VERSION ""

NS_ :

BS_:

BU_:  Inverter  Battery  Charger  Host

BO_ 2571108363 BATT_eventMatrix_A_11: 8 Battery
 SG_ BATT_packModIdFault_11 : 8|1@1+ (1,0) [0|1] "" Host
 SG_ BATT_packModExitedFromBus_11 : 16|1@1+ (1,0) [0|1] "" Host
 SG_ BATT_packFetChgWelded_11 : 35|1@1+ (1,0) [0|1] "" Host
 SG_ BATT_packFetDsgWelded_11 : 36|1@1+ (1,0) [0|1] "" Host
 SG_ BATT_fetDsgShortedAux_11 : 63|1@1+ (1,0) [0|1] "" Host
 SG_ BATT_fetChgShortedAux_11 : 25|1@1+ (1,0) [0|1] "" Host
 SG_ BATT_prechargeFetFail_11 : 39|1@1+ (1,0) [0|1] "" Host
 SG_ BATT_abnormalResetReason_11 : 31|1@1+ (1,0) [0|1] "" Host
 SG_ BATT_prechargeTooSlow_11 : 49|1@1+ (1,0) [0|1] "" Host
 SG_ BATT_prechargeTooFast_11 : 50|1@1+ (1,0) [0|1] "" Host
 SG_ BATT_prechargeTimeout_11 : 51|1@1+ (1,0) [0|1] "" Host
 SG_ BATT_fetChgShorted_11 : 23|1@1+ (1,0) [0|1] "" Host
 SG_ BATT_fetChgFailToClose_11 : 22|1@1+ (1,0) [0|1] "" Host
 SG_ BATT_packModSelectFault_11 : 21|1@1+ (1,0) [0|1] "" Host
 SG_ BATT_packModConnectFault_11 : 20|1@1+ (1,0) [0|1] "" Host
 SG_ BATT_packModMIA_11 : 19|1@1+ (1,0) [0|1] "" Host
 SG_ BATT_packModImbalance_11 : 18|1@1+ (1,0) [0|1] "" Host
 SG_ BATT_afeFault_11 : 17|1@1+ (1,0) [0|1] "" Host
 SG_ BATT_chargerMIA_11 : 60|1@1+ (1,0) [0|1] "" Host
 SG_ BATT_chargerError_11 : 59|1@1+ (1,0) [0|1] "" Host
 SG_ BATT_vBrickUnderWar_11 : 58|1@1+ (1,0) [0|1] "" Host
 SG_ BATT_vBrickUnderSev_11 : 57|1@1+ (1,0) [0|1] "" Host
 SG_ BATT_vBrickUnderMod_11 : 56|1@1+ (1,0) [0|1] "" Host
 SG_ BATT_vBrickOverWar_11 : 55|1@1+ (1,0) [0|1] "" Host
 SG_ BATT_vBrickOverSev_11 : 54|1@1+ (1,0) [0|1] "" Host
 SG_ BATT_vBrickOverMod_11 : 53|1@1+ (1,0) [0|1] "" Host
 SG_ BATT_vBrickImbalance_11 : 52|1@1+ (1,0) [0|1] "" Host
 SG_ BATT_loggerAlmostFull_11 : 61|1@1+ (1,0) [0|1] "" Host
 SG_ BATT_tempModuleUnderWar_11 : 48|1@1+ (1,0) [0|1] "" Host
 SG_ BATT_tempModuleUnderSev_11 : 47|1@1+ (1,0) [0|1] "" Host
 SG_ BATT_tempModuleUnderMod_11 : 46|1@1+ (1,0) [0|1] "" Host
 SG_ BATT_tempModuleOverWar_11 : 45|1@1+ (1,0) [0|1] "" Host
 SG_ BATT_tempModuleOverSev_11 : 44|1@1+ (1,0) [0|1] "" Host
 SG_ BATT_tempModuleOverMod_11 : 43|1@1+ (1,0) [0|1] "" Host
 SG_ BATT_tempBrickImbalance_11 : 42|1@1+ (1,0) [0|1] "" Host
 SG_ BATT_taskLockupError_11 : 41|1@1+ (1,0) [0|1] "" Host
 SG_ BATT_tempAmbientOverWar_11 : 40|1@1+ (1,0) [0|1] "" Host
 SG_ BATT_tempAmbientOverSev_11 : 38|1@1+ (1,0) [0|1] "" Host
 SG_ BATT_tempAmbientOverMod_11 : 37|1@1+ (1,0) [0|1] "" Host
 SG_ BATT_sensePackVoltError_11 : 34|1@1+ (1,0) [0|1] "" Host
 SG_ BATT_senseLoadVoltError_11 : 33|1@1+ (1,0) [0|1] "" Host
 SG_ BATT_loggerFull_11 : 62|1@1+ (1,0) [0|1] "" Host
 SG_ BATT_senseCurrentError_11 : 32|1@1+ (1,0) [0|1] "" Host
 SG_ BATT_senseBrickTempError_11 : 30|1@1+ (1,0) [0|1] "" Host
 SG_ BATT_resPackHigh_11 : 29|1@1+ (1,0) [0|1] "" Host
 SG_ BATT_ramOverUtilError_11 : 28|1@1+ (1,0) [0|1] "" Host
 SG_ BATT_powerPackInsufficient_11 : 27|1@1+ (1,0) [0|1] "" Host
 SG_ BATT_packCellSoftShort_11 : 26|1@1+ (1,0) [0|1] "" Host
 SG_ BATT_iOverHardware_11 : 24|1@1+ (1,0) [0|1] "" Host
 SG_ BATT_fetOverTemp_11 : 15|1@1+ (1,0) [0|1] "" Host
 SG_ BATT_iOverDischarge_11 : 14|1@1+ (1,0) [0|1] "" Host
 SG_ BATT_iOverCharge_11 : 13|1@1+ (1,0) [0|1] "" Host
 SG_ BATT_inverterDriveMIA_11 : 12|1@1+ (1,0) [0|1] "" Host
 SG_ BATT_iUnderCharge_11 : 11|1@1+ (1,0) [0|1] "" Host
 SG_ BATT_hostMIA_11 : 10|1@1+ (1,0) [0|1] "" Host
 SG_ BATT_fetDsgShorted_11 : 7|1@1+ (1,0) [0|1] "" Host
 SG_ BATT_fetDsgFailToClose_11 : 6|1@1+ (1,0) [0|1] "" Host
 SG_ BATT_capLow_11 : 5|1@1+ (1,0) [0|1] "" Host
 SG_ BATT_brickOverDischarge_11 : 4|1@1+ (1,0) [0|1] "" Host
 SG_ BATT_brickOverCharge_11 : 3|1@1+ (1,0) [0|1] "" Host
 SG_ BATT_bmsProcessorError_11 : 2|1@1+ (1,0) [0|1] "" Host
 SG_ BATT_bmsMemoryError_11 : 1|1@1+ (1,0) [0|1] "" Host
 SG_ BATT_afeError_11 : 0|1@1+ (1,0) [0|1] "" Host

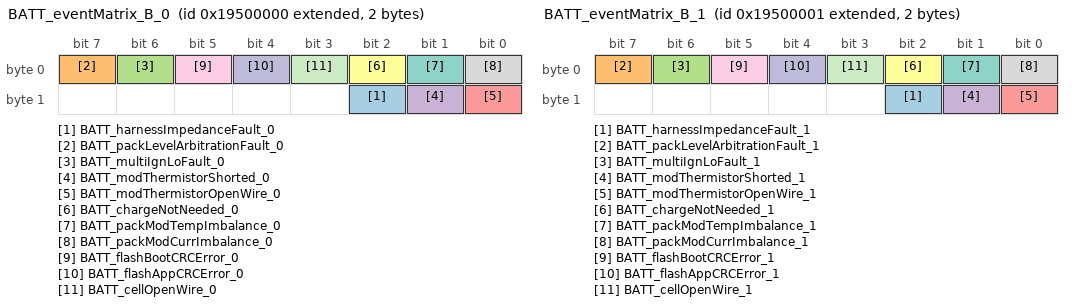
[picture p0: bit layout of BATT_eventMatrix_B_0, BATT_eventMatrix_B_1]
BO_ 2572156928 BATT_eventMatrix_B_0: 2 Battery
 SG_ BATT_harnessImpedanceFault_0 : 10|1@1+ (1,0) [0|1] "mOhms" Host
 SG_ BATT_packLevelArbitrationFault_0 : 7|1@1+ (1,0) [0|1] "" Host
 SG_ BATT_multiIgnLoFault_0 : 6|1@1+ (1,0) [0|1] "" Host
 SG_ BATT_modThermistorShorted_0 : 9|1@1+ (1,0) [0|1] "" Host
 SG_ BATT_modThermistorOpenWire_0 : 8|1@1+ (1,0) [0|1] "" Host
 SG_ BATT_chargeNotNeeded_0 : 2|1@1+ (1,0) [0|1] "" Host
 SG_ BATT_packModTempImbalance_0 : 1|1@1+ (1,0) [0|1] "" Host
 SG_ BATT_packModCurrImbalance_0 : 0|1@1+ (1,0) [0|1] "" Host
 SG_ BATT_flashBootCRCError_0 : 5|1@1+ (1,0) [0|1] "" Host
 SG_ BATT_flashAppCRCError_0 : 4|1@1+ (1,0) [0|1] "" Host
 SG_ BATT_cellOpenWire_0 : 3|1@1+ (1,0) [0|1] "" Host

BO_ 2572156929 BATT_eventMatrix_B_1: 2 Battery
 SG_ BATT_harnessImpedanceFault_1 : 10|1@1+ (1,0) [0|1] "mOhms" Host
 SG_ BATT_packLevelArbitrationFault_1 : 7|1@1+ (1,0) [0|1] "" Host
 SG_ BATT_multiIgnLoFault_1 : 6|1@1+ (1,0) [0|1] "" Host
 SG_ BATT_modThermistorShorted_1 : 9|1@1+ (1,0) [0|1] "" Host
 SG_ BATT_modThermistorOpenWire_1 : 8|1@1+ (1,0) [0|1] "" Host
 SG_ BATT_chargeNotNeeded_1 : 2|1@1+ (1,0) [0|1] "" Host
 SG_ BATT_packModTempImbalance_1 : 1|1@1+ (1,0) [0|1] "" Host
 SG_ BATT_packModCurrImbalance_1 : 0|1@1+ (1,0) [0|1] "" Host
 SG_ BATT_flashBootCRCError_1 : 5|1@1+ (1,0) [0|1] "" Host
 SG_ BATT_flashAppCRCError_1 : 4|1@1+ (1,0) [0|1] "" Host
 SG_ BATT_cellOpenWire_1 : 3|1@1+ (1,0) [0|1] "" Host

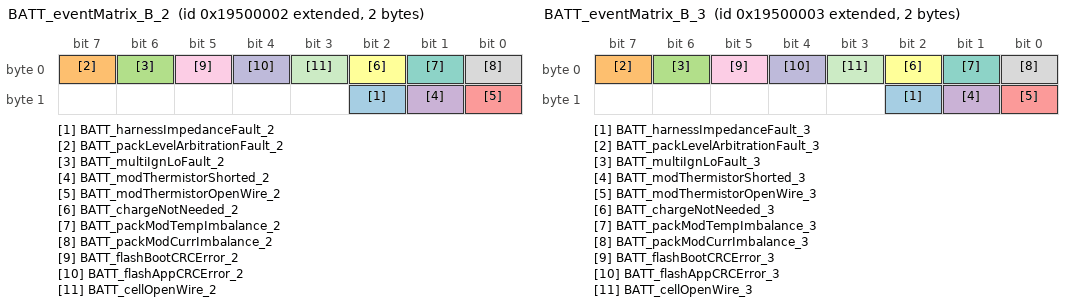
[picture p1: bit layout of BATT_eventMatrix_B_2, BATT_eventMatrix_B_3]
BO_ 2572156930 BATT_eventMatrix_B_2: 2 Battery
 SG_ BATT_harnessImpedanceFault_2 : 10|1@1+ (1,0) [0|1] "mOhms" Host
 SG_ BATT_packLevelArbitrationFault_2 : 7|1@1+ (1,0) [0|1] "" Host
 SG_ BATT_multiIgnLoFault_2 : 6|1@1+ (1,0) [0|1] "" Host
 SG_ BATT_modThermistorShorted_2 : 9|1@1+ (1,0) [0|1] "" Host
 SG_ BATT_modThermistorOpenWire_2 : 8|1@1+ (1,0) [0|1] "" Host
 SG_ BATT_chargeNotNeeded_2 : 2|1@1+ (1,0) [0|1] "" Host
 SG_ BATT_packModTempImbalance_2 : 1|1@1+ (1,0) [0|1] "" Host
 SG_ BATT_packModCurrImbalance_2 : 0|1@1+ (1,0) [0|1] "" Host
 SG_ BATT_flashBootCRCError_2 : 5|1@1+ (1,0) [0|1] "" Host
 SG_ BATT_flashAppCRCError_2 : 4|1@1+ (1,0) [0|1] "" Host
 SG_ BATT_cellOpenWire_2 : 3|1@1+ (1,0) [0|1] "" Host

BO_ 2572156931 BATT_eventMatrix_B_3: 2 Battery
 SG_ BATT_harnessImpedanceFault_3 : 10|1@1+ (1,0) [0|1] "mOhms" Host
 SG_ BATT_packLevelArbitrationFault_3 : 7|1@1+ (1,0) [0|1] "" Host
 SG_ BATT_multiIgnLoFault_3 : 6|1@1+ (1,0) [0|1] "" Host
 SG_ BATT_modThermistorShorted_3 : 9|1@1+ (1,0) [0|1] "" Host
 SG_ BATT_modThermistorOpenWire_3 : 8|1@1+ (1,0) [0|1] "" Host
 SG_ BATT_chargeNotNeeded_3 : 2|1@1+ (1,0) [0|1] "" Host
 SG_ BATT_packModTempImbalance_3 : 1|1@1+ (1,0) [0|1] "" Host
 SG_ BATT_packModCurrImbalance_3 : 0|1@1+ (1,0) [0|1] "" Host
 SG_ BATT_flashBootCRCError_3 : 5|1@1+ (1,0) [0|1] "" Host
 SG_ BATT_flashAppCRCError_3 : 4|1@1+ (1,0) [0|1] "" Host
 SG_ BATT_cellOpenWire_3 : 3|1@1+ (1,0) [0|1] "" Host

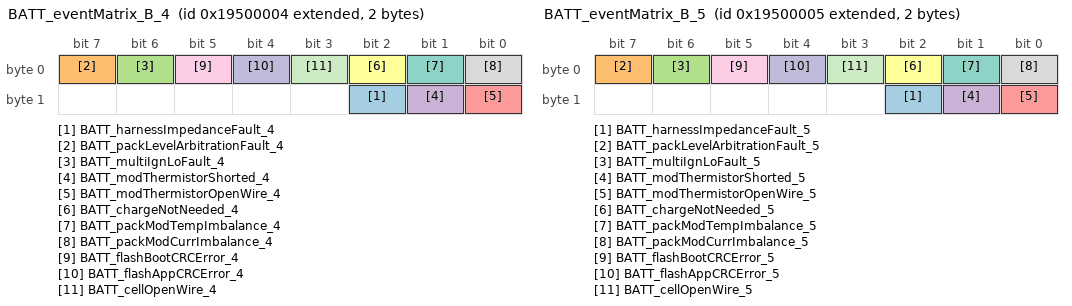
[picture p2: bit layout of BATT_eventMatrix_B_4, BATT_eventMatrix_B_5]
BO_ 2572156932 BATT_eventMatrix_B_4: 2 Battery
 SG_ BATT_harnessImpedanceFault_4 : 10|1@1+ (1,0) [0|1] "mOhms" Host
 SG_ BATT_packLevelArbitrationFault_4 : 7|1@1+ (1,0) [0|1] "" Host
 SG_ BATT_multiIgnLoFault_4 : 6|1@1+ (1,0) [0|1] "" Host
 SG_ BATT_modThermistorShorted_4 : 9|1@1+ (1,0) [0|1] "" Host
 SG_ BATT_modThermistorOpenWire_4 : 8|1@1+ (1,0) [0|1] "" Host
 SG_ BATT_chargeNotNeeded_4 : 2|1@1+ (1,0) [0|1] "" Host
 SG_ BATT_packModTempImbalance_4 : 1|1@1+ (1,0) [0|1] "" Host
 SG_ BATT_packModCurrImbalance_4 : 0|1@1+ (1,0) [0|1] "" Host
 SG_ BATT_flashBootCRCError_4 : 5|1@1+ (1,0) [0|1] "" Host
 SG_ BATT_flashAppCRCError_4 : 4|1@1+ (1,0) [0|1] "" Host
 SG_ BATT_cellOpenWire_4 : 3|1@1+ (1,0) [0|1] "" Host

BO_ 2572156933 BATT_eventMatrix_B_5: 2 Battery
 SG_ BATT_harnessImpedanceFault_5 : 10|1@1+ (1,0) [0|1] "mOhms" Host
 SG_ BATT_packLevelArbitrationFault_5 : 7|1@1+ (1,0) [0|1] "" Host
 SG_ BATT_multiIgnLoFault_5 : 6|1@1+ (1,0) [0|1] "" Host
 SG_ BATT_modThermistorShorted_5 : 9|1@1+ (1,0) [0|1] "" Host
 SG_ BATT_modThermistorOpenWire_5 : 8|1@1+ (1,0) [0|1] "" Host
 SG_ BATT_chargeNotNeeded_5 : 2|1@1+ (1,0) [0|1] "" Host
 SG_ BATT_packModTempImbalance_5 : 1|1@1+ (1,0) [0|1] "" Host
 SG_ BATT_packModCurrImbalance_5 : 0|1@1+ (1,0) [0|1] "" Host
 SG_ BATT_flashBootCRCError_5 : 5|1@1+ (1,0) [0|1] "" Host
 SG_ BATT_flashAppCRCError_5 : 4|1@1+ (1,0) [0|1] "" Host
 SG_ BATT_cellOpenWire_5 : 3|1@1+ (1,0) [0|1] "" Host

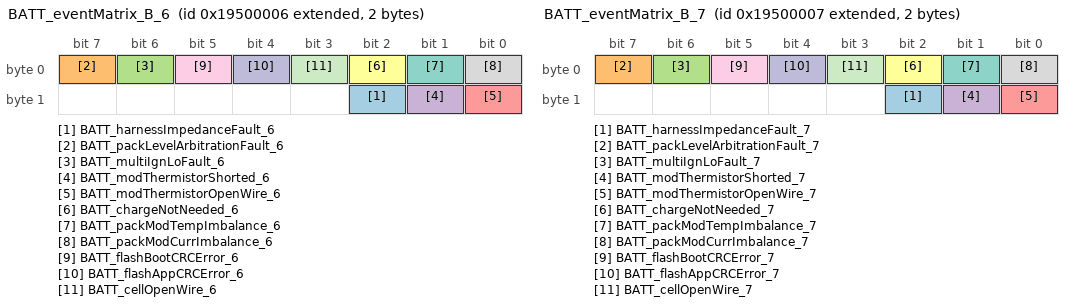
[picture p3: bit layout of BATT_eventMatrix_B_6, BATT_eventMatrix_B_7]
BO_ 2572156934 BATT_eventMatrix_B_6: 2 Battery
 SG_ BATT_harnessImpedanceFault_6 : 10|1@1+ (1,0) [0|1] "mOhms" Host
 SG_ BATT_packLevelArbitrationFault_6 : 7|1@1+ (1,0) [0|1] "" Host
 SG_ BATT_multiIgnLoFault_6 : 6|1@1+ (1,0) [0|1] "" Host
 SG_ BATT_modThermistorShorted_6 : 9|1@1+ (1,0) [0|1] "" Host
 SG_ BATT_modThermistorOpenWire_6 : 8|1@1+ (1,0) [0|1] "" Host
 SG_ BATT_chargeNotNeeded_6 : 2|1@1+ (1,0) [0|1] "" Host
 SG_ BATT_packModTempImbalance_6 : 1|1@1+ (1,0) [0|1] "" Host
 SG_ BATT_packModCurrImbalance_6 : 0|1@1+ (1,0) [0|1] "" Host
 SG_ BATT_flashBootCRCError_6 : 5|1@1+ (1,0) [0|1] "" Host
 SG_ BATT_flashAppCRCError_6 : 4|1@1+ (1,0) [0|1] "" Host
 SG_ BATT_cellOpenWire_6 : 3|1@1+ (1,0) [0|1] "" Host

BO_ 2572156935 BATT_eventMatrix_B_7: 2 Battery
 SG_ BATT_harnessImpedanceFault_7 : 10|1@1+ (1,0) [0|1] "mOhms" Host
 SG_ BATT_packLevelArbitrationFault_7 : 7|1@1+ (1,0) [0|1] "" Host
 SG_ BATT_multiIgnLoFault_7 : 6|1@1+ (1,0) [0|1] "" Host
 SG_ BATT_modThermistorShorted_7 : 9|1@1+ (1,0) [0|1] "" Host
 SG_ BATT_modThermistorOpenWire_7 : 8|1@1+ (1,0) [0|1] "" Host
 SG_ BATT_chargeNotNeeded_7 : 2|1@1+ (1,0) [0|1] "" Host
 SG_ BATT_packModTempImbalance_7 : 1|1@1+ (1,0) [0|1] "" Host
 SG_ BATT_packModCurrImbalance_7 : 0|1@1+ (1,0) [0|1] "" Host
 SG_ BATT_flashBootCRCError_7 : 5|1@1+ (1,0) [0|1] "" Host
 SG_ BATT_flashAppCRCError_7 : 4|1@1+ (1,0) [0|1] "" Host
 SG_ BATT_cellOpenWire_7 : 3|1@1+ (1,0) [0|1] "" Host

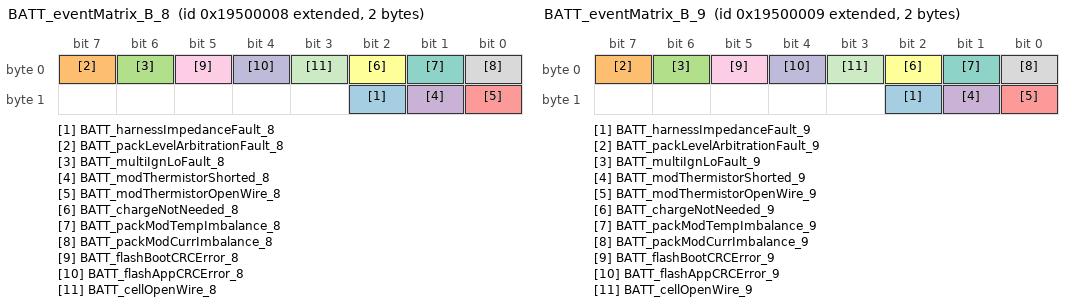
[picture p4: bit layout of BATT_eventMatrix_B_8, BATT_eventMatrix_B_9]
BO_ 2572156936 BATT_eventMatrix_B_8: 2 Battery
 SG_ BATT_harnessImpedanceFault_8 : 10|1@1+ (1,0) [0|1] "mOhms" Host
 SG_ BATT_packLevelArbitrationFault_8 : 7|1@1+ (1,0) [0|1] "" Host
 SG_ BATT_multiIgnLoFault_8 : 6|1@1+ (1,0) [0|1] "" Host
 SG_ BATT_modThermistorShorted_8 : 9|1@1+ (1,0) [0|1] "" Host
 SG_ BATT_modThermistorOpenWire_8 : 8|1@1+ (1,0) [0|1] "" Host
 SG_ BATT_chargeNotNeeded_8 : 2|1@1+ (1,0) [0|1] "" Host
 SG_ BATT_packModTempImbalance_8 : 1|1@1+ (1,0) [0|1] "" Host
 SG_ BATT_packModCurrImbalance_8 : 0|1@1+ (1,0) [0|1] "" Host
 SG_ BATT_flashBootCRCError_8 : 5|1@1+ (1,0) [0|1] "" Host
 SG_ BATT_flashAppCRCError_8 : 4|1@1+ (1,0) [0|1] "" Host
 SG_ BATT_cellOpenWire_8 : 3|1@1+ (1,0) [0|1] "" Host

BO_ 2572156937 BATT_eventMatrix_B_9: 2 Battery
 SG_ BATT_harnessImpedanceFault_9 : 10|1@1+ (1,0) [0|1] "mOhms" Host
 SG_ BATT_packLevelArbitrationFault_9 : 7|1@1+ (1,0) [0|1] "" Host
 SG_ BATT_multiIgnLoFault_9 : 6|1@1+ (1,0) [0|1] "" Host
 SG_ BATT_modThermistorShorted_9 : 9|1@1+ (1,0) [0|1] "" Host
 SG_ BATT_modThermistorOpenWire_9 : 8|1@1+ (1,0) [0|1] "" Host
 SG_ BATT_chargeNotNeeded_9 : 2|1@1+ (1,0) [0|1] "" Host
 SG_ BATT_packModTempImbalance_9 : 1|1@1+ (1,0) [0|1] "" Host
 SG_ BATT_packModCurrImbalance_9 : 0|1@1+ (1,0) [0|1] "" Host
 SG_ BATT_flashBootCRCError_9 : 5|1@1+ (1,0) [0|1] "" Host
 SG_ BATT_flashAppCRCError_9 : 4|1@1+ (1,0) [0|1] "" Host
 SG_ BATT_cellOpenWire_9 : 3|1@1+ (1,0) [0|1] "" Host

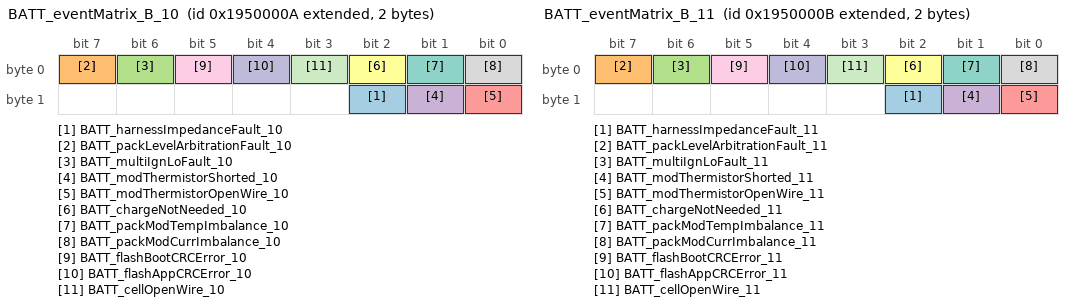
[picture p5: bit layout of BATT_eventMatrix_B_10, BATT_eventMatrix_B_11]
BO_ 2572156938 BATT_eventMatrix_B_10: 2 Battery
 SG_ BATT_harnessImpedanceFault_10 : 10|1@1+ (1,0) [0|1] "mOhms" Host
 SG_ BATT_packLevelArbitrationFault_10 : 7|1@1+ (1,0) [0|1] "" Host
 SG_ BATT_multiIgnLoFault_10 : 6|1@1+ (1,0) [0|1] "" Host
 SG_ BATT_modThermistorShorted_10 : 9|1@1+ (1,0) [0|1] "" Host
 SG_ BATT_modThermistorOpenWire_10 : 8|1@1+ (1,0) [0|1] "" Host
 SG_ BATT_chargeNotNeeded_10 : 2|1@1+ (1,0) [0|1] "" Host
 SG_ BATT_packModTempImbalance_10 : 1|1@1+ (1,0) [0|1] "" Host
 SG_ BATT_packModCurrImbalance_10 : 0|1@1+ (1,0) [0|1] "" Host
 SG_ BATT_flashBootCRCError_10 : 5|1@1+ (1,0) [0|1] "" Host
 SG_ BATT_flashAppCRCError_10 : 4|1@1+ (1,0) [0|1] "" Host
 SG_ BATT_cellOpenWire_10 : 3|1@1+ (1,0) [0|1] "" Host

BO_ 2572156939 BATT_eventMatrix_B_11: 2 Battery
 SG_ BATT_harnessImpedanceFault_11 : 10|1@1+ (1,0) [0|1] "mOhms" Host
 SG_ BATT_packLevelArbitrationFault_11 : 7|1@1+ (1,0) [0|1] "" Host
 SG_ BATT_multiIgnLoFault_11 : 6|1@1+ (1,0) [0|1] "" Host
 SG_ BATT_modThermistorShorted_11 : 9|1@1+ (1,0) [0|1] "" Host
 SG_ BATT_modThermistorOpenWire_11 : 8|1@1+ (1,0) [0|1] "" Host
 SG_ BATT_chargeNotNeeded_11 : 2|1@1+ (1,0) [0|1] "" Host
 SG_ BATT_packModTempImbalance_11 : 1|1@1+ (1,0) [0|1] "" Host
 SG_ BATT_packModCurrImbalance_11 : 0|1@1+ (1,0) [0|1] "" Host
 SG_ BATT_flashBootCRCError_11 : 5|1@1+ (1,0) [0|1] "" Host
 SG_ BATT_flashAppCRCError_11 : 4|1@1+ (1,0) [0|1] "" Host
 SG_ BATT_cellOpenWire_11 : 3|1@1+ (1,0) [0|1] "" Host

BO_ 2617245696 BATT_diagnosticRunTime_0: 6 Battery
 SG_ BATT_totalRunTime_0 : 0|16@1+ (10,0) [0|655350] "10min" Host

BO_ 2617245697 BATT_diagnosticRunTime_1: 6 Battery
 SG_ BATT_totalRunTime_1 : 0|16@1+ (10,0) [0|655350] "10min" Host

BO_ 2617245698 BATT_diagnosticRunTime_2: 6 Battery
 SG_ BATT_totalRunTime_2 : 0|16@1+ (10,0) [0|655350] "10min" Host

BO_ 2617245699 BATT_diagnosticRunTime_3: 6 Battery
 SG_ BATT_totalRunTime_3 : 0|16@1+ (10,0) [0|655350] "10min" Host

BO_ 2617245700 BATT_diagnosticRunTime_4: 6 Battery
 SG_ BATT_totalRunTime_4 : 0|16@1+ (10,0) [0|655350] "10min" Host

BO_ 2617245701 BATT_diagnosticRunTime_5: 6 Battery
 SG_ BATT_totalRunTime_5 : 0|16@1+ (10,0) [0|655350] "10min" Host

BO_ 2617245702 BATT_diagnosticRunTime_6: 6 Battery
 SG_ BATT_totalRunTime_6 : 0|16@1+ (10,0) [0|655350] "10min" Host

BO_ 2617245703 BATT_diagnosticRunTime_7: 6 Battery
 SG_ BATT_totalRunTime_7 : 0|16@1+ (10,0) [0|655350] "10min" Host

BO_ 2617245704 BATT_diagnosticRunTime_8: 6 Battery
 SG_ BATT_totalRunTime_8 : 0|16@1+ (10,0) [0|655350] "10min" Host

BO_ 2617245705 BATT_diagnosticRunTime_9: 6 Battery
 SG_ BATT_totalRunTime_9 : 0|16@1+ (10,0) [0|655350] "10min" Host

BO_ 2617245706 BATT_diagnosticRunTime_10: 6 Battery
 SG_ BATT_totalRunTime_10 : 0|16@1+ (10,0) [0|655350] "10min" Host

BO_ 2617245707 BATT_diagnosticRunTime_11: 6 Battery
 SG_ BATT_totalRunTime_11 : 0|16@1+ (10,0) [0|655350] "10min" Host

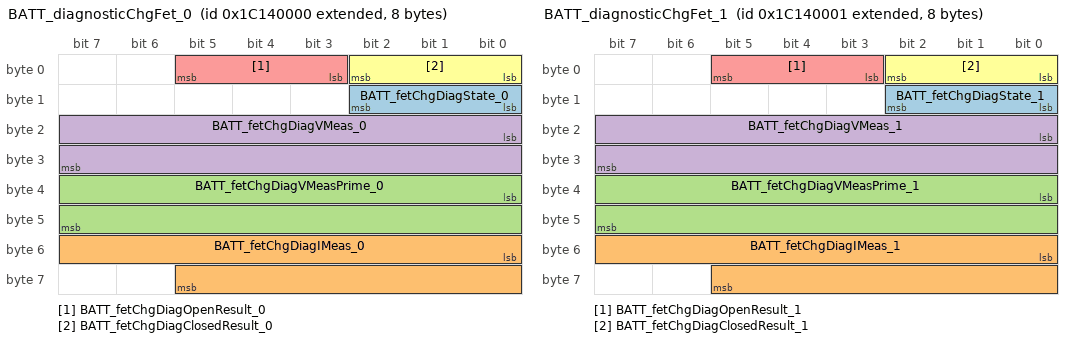
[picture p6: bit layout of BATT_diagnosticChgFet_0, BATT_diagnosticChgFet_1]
BO_ 2618556416 BATT_diagnosticChgFet_0: 8 Battery
 SG_ BATT_fetChgDiagState_0 : 8|3@1+ (1,0) [0|7] "" Host
 SG_ BATT_fetChgDiagIMeas_0 : 48|14@1- (0.025,0) [-204.8|204.775] "A" Host
 SG_ BATT_fetChgDiagVMeasPrime_0 : 32|16@1- (0.005,0) [-163.84|163.835] "V" Host
 SG_ BATT_fetChgDiagVMeas_0 : 16|16@1- (0.005,0) [-163.84|163.835] "V" Host
 SG_ BATT_fetChgDiagOpenResult_0 : 3|3@1+ (1,0) [0|7] "" Host
 SG_ BATT_fetChgDiagClosedResult_0 : 0|3@1+ (1,0) [0|7] "" Host

BO_ 2618556417 BATT_diagnosticChgFet_1: 8 Battery
 SG_ BATT_fetChgDiagState_1 : 8|3@1+ (1,0) [0|7] "" Host
 SG_ BATT_fetChgDiagIMeas_1 : 48|14@1- (0.025,0) [-204.8|204.775] "A" Host
 SG_ BATT_fetChgDiagVMeasPrime_1 : 32|16@1- (0.005,0) [-163.84|163.835] "V" Host
 SG_ BATT_fetChgDiagVMeas_1 : 16|16@1- (0.005,0) [-163.84|163.835] "V" Host
 SG_ BATT_fetChgDiagOpenResult_1 : 3|3@1+ (1,0) [0|7] "" Host
 SG_ BATT_fetChgDiagClosedResult_1 : 0|3@1+ (1,0) [0|7] "" Host

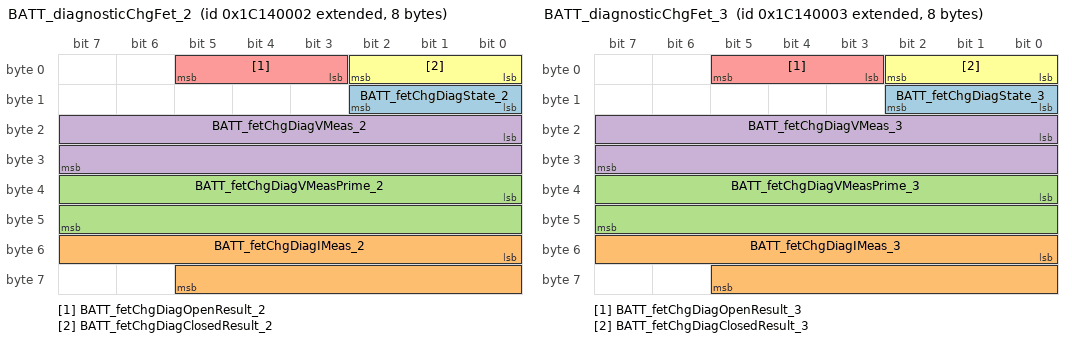
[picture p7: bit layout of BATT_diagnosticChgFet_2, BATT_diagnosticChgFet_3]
BO_ 2618556418 BATT_diagnosticChgFet_2: 8 Battery
 SG_ BATT_fetChgDiagState_2 : 8|3@1+ (1,0) [0|7] "" Host
 SG_ BATT_fetChgDiagIMeas_2 : 48|14@1- (0.025,0) [-204.8|204.775] "A" Host
 SG_ BATT_fetChgDiagVMeasPrime_2 : 32|16@1- (0.005,0) [-163.84|163.835] "V" Host
 SG_ BATT_fetChgDiagVMeas_2 : 16|16@1- (0.005,0) [-163.84|163.835] "V" Host
 SG_ BATT_fetChgDiagOpenResult_2 : 3|3@1+ (1,0) [0|7] "" Host
 SG_ BATT_fetChgDiagClosedResult_2 : 0|3@1+ (1,0) [0|7] "" Host

BO_ 2618556419 BATT_diagnosticChgFet_3: 8 Battery
 SG_ BATT_fetChgDiagState_3 : 8|3@1+ (1,0) [0|7] "" Host
 SG_ BATT_fetChgDiagIMeas_3 : 48|14@1- (0.025,0) [-204.8|204.775] "A" Host
 SG_ BATT_fetChgDiagVMeasPrime_3 : 32|16@1- (0.005,0) [-163.84|163.835] "V" Host
 SG_ BATT_fetChgDiagVMeas_3 : 16|16@1- (0.005,0) [-163.84|163.835] "V" Host
 SG_ BATT_fetChgDiagOpenResult_3 : 3|3@1+ (1,0) [0|7] "" Host
 SG_ BATT_fetChgDiagClosedResult_3 : 0|3@1+ (1,0) [0|7] "" Host

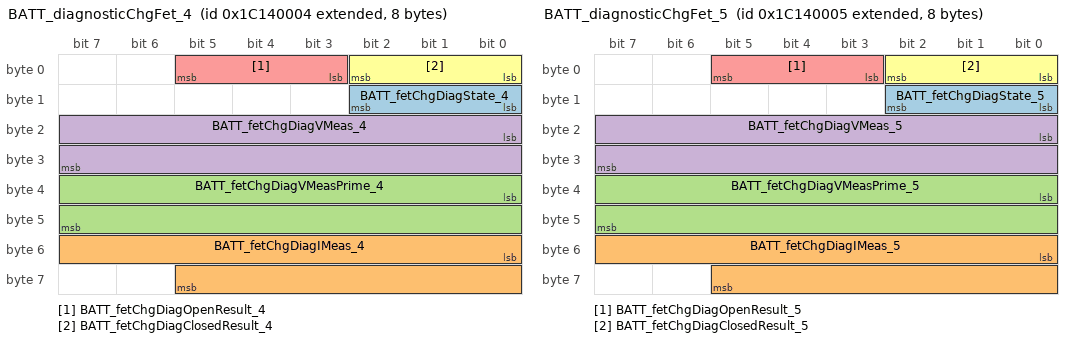
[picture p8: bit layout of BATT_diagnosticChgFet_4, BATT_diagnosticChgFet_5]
BO_ 2618556420 BATT_diagnosticChgFet_4: 8 Battery
 SG_ BATT_fetChgDiagState_4 : 8|3@1+ (1,0) [0|7] "" Host
 SG_ BATT_fetChgDiagIMeas_4 : 48|14@1- (0.025,0) [-204.8|204.775] "A" Host
 SG_ BATT_fetChgDiagVMeasPrime_4 : 32|16@1- (0.005,0) [-163.84|163.835] "V" Host
 SG_ BATT_fetChgDiagVMeas_4 : 16|16@1- (0.005,0) [-163.84|163.835] "V" Host
 SG_ BATT_fetChgDiagOpenResult_4 : 3|3@1+ (1,0) [0|7] "" Host
 SG_ BATT_fetChgDiagClosedResult_4 : 0|3@1+ (1,0) [0|7] "" Host

BO_ 2618556421 BATT_diagnosticChgFet_5: 8 Battery
 SG_ BATT_fetChgDiagState_5 : 8|3@1+ (1,0) [0|7] "" Host
 SG_ BATT_fetChgDiagIMeas_5 : 48|14@1- (0.025,0) [-204.8|204.775] "A" Host
 SG_ BATT_fetChgDiagVMeasPrime_5 : 32|16@1- (0.005,0) [-163.84|163.835] "V" Host
 SG_ BATT_fetChgDiagVMeas_5 : 16|16@1- (0.005,0) [-163.84|163.835] "V" Host
 SG_ BATT_fetChgDiagOpenResult_5 : 3|3@1+ (1,0) [0|7] "" Host
 SG_ BATT_fetChgDiagClosedResult_5 : 0|3@1+ (1,0) [0|7] "" Host

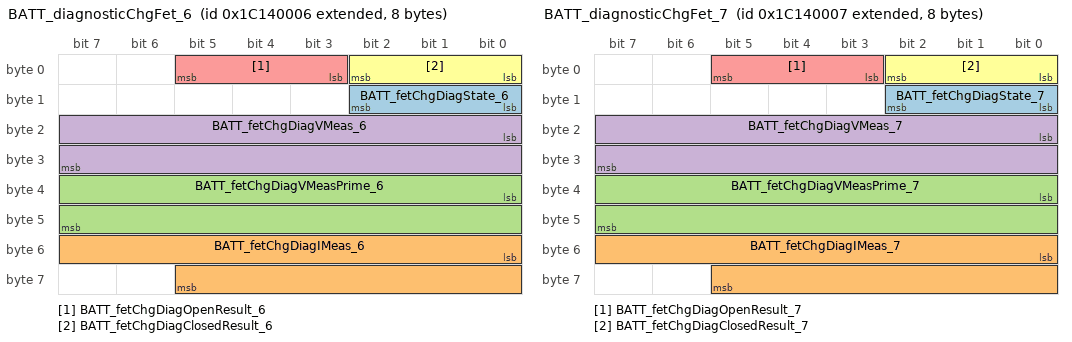
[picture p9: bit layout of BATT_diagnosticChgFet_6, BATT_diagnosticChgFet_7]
BO_ 2618556422 BATT_diagnosticChgFet_6: 8 Battery
 SG_ BATT_fetChgDiagState_6 : 8|3@1+ (1,0) [0|7] "" Host
 SG_ BATT_fetChgDiagIMeas_6 : 48|14@1- (0.025,0) [-204.8|204.775] "A" Host
 SG_ BATT_fetChgDiagVMeasPrime_6 : 32|16@1- (0.005,0) [-163.84|163.835] "V" Host
 SG_ BATT_fetChgDiagVMeas_6 : 16|16@1- (0.005,0) [-163.84|163.835] "V" Host
 SG_ BATT_fetChgDiagOpenResult_6 : 3|3@1+ (1,0) [0|7] "" Host
 SG_ BATT_fetChgDiagClosedResult_6 : 0|3@1+ (1,0) [0|7] "" Host

BO_ 2618556423 BATT_diagnosticChgFet_7: 8 Battery
 SG_ BATT_fetChgDiagState_7 : 8|3@1+ (1,0) [0|7] "" Host
 SG_ BATT_fetChgDiagIMeas_7 : 48|14@1- (0.025,0) [-204.8|204.775] "A" Host
 SG_ BATT_fetChgDiagVMeasPrime_7 : 32|16@1- (0.005,0) [-163.84|163.835] "V" Host
 SG_ BATT_fetChgDiagVMeas_7 : 16|16@1- (0.005,0) [-163.84|163.835] "V" Host
 SG_ BATT_fetChgDiagOpenResult_7 : 3|3@1+ (1,0) [0|7] "" Host
 SG_ BATT_fetChgDiagClosedResult_7 : 0|3@1+ (1,0) [0|7] "" Host

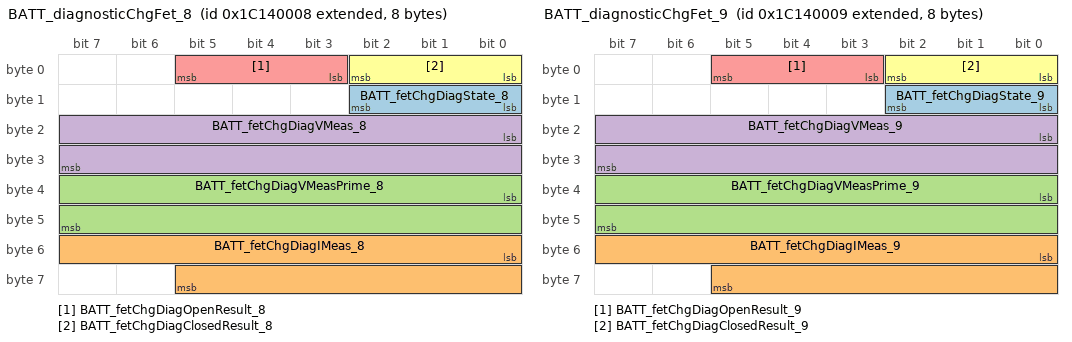
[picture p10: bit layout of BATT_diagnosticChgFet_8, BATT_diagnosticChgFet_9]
BO_ 2618556424 BATT_diagnosticChgFet_8: 8 Battery
 SG_ BATT_fetChgDiagState_8 : 8|3@1+ (1,0) [0|7] "" Host
 SG_ BATT_fetChgDiagIMeas_8 : 48|14@1- (0.025,0) [-204.8|204.775] "A" Host
 SG_ BATT_fetChgDiagVMeasPrime_8 : 32|16@1- (0.005,0) [-163.84|163.835] "V" Host
 SG_ BATT_fetChgDiagVMeas_8 : 16|16@1- (0.005,0) [-163.84|163.835] "V" Host
 SG_ BATT_fetChgDiagOpenResult_8 : 3|3@1+ (1,0) [0|7] "" Host
 SG_ BATT_fetChgDiagClosedResult_8 : 0|3@1+ (1,0) [0|7] "" Host

BO_ 2618556425 BATT_diagnosticChgFet_9: 8 Battery
 SG_ BATT_fetChgDiagState_9 : 8|3@1+ (1,0) [0|7] "" Host
 SG_ BATT_fetChgDiagIMeas_9 : 48|14@1- (0.025,0) [-204.8|204.775] "A" Host
 SG_ BATT_fetChgDiagVMeasPrime_9 : 32|16@1- (0.005,0) [-163.84|163.835] "V" Host
 SG_ BATT_fetChgDiagVMeas_9 : 16|16@1- (0.005,0) [-163.84|163.835] "V" Host
 SG_ BATT_fetChgDiagOpenResult_9 : 3|3@1+ (1,0) [0|7] "" Host
 SG_ BATT_fetChgDiagClosedResult_9 : 0|3@1+ (1,0) [0|7] "" Host

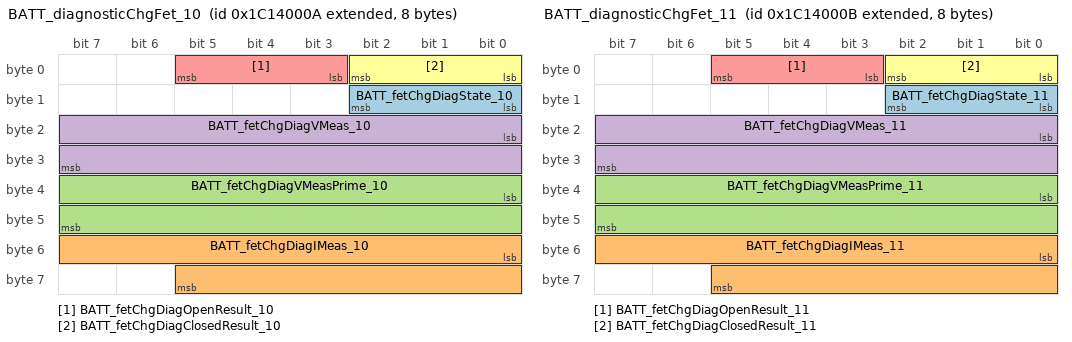
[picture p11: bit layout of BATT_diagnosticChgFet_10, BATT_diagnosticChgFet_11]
BO_ 2618556426 BATT_diagnosticChgFet_10: 8 Battery
 SG_ BATT_fetChgDiagState_10 : 8|3@1+ (1,0) [0|7] "" Host
 SG_ BATT_fetChgDiagIMeas_10 : 48|14@1- (0.025,0) [-204.8|204.775] "A" Host
 SG_ BATT_fetChgDiagVMeasPrime_10 : 32|16@1- (0.005,0) [-163.84|163.835] "V" Host
 SG_ BATT_fetChgDiagVMeas_10 : 16|16@1- (0.005,0) [-163.84|163.835] "V" Host
 SG_ BATT_fetChgDiagOpenResult_10 : 3|3@1+ (1,0) [0|7] "" Host
 SG_ BATT_fetChgDiagClosedResult_10 : 0|3@1+ (1,0) [0|7] "" Host

BO_ 2618556427 BATT_diagnosticChgFet_11: 8 Battery
 SG_ BATT_fetChgDiagState_11 : 8|3@1+ (1,0) [0|7] "" Host
 SG_ BATT_fetChgDiagIMeas_11 : 48|14@1- (0.025,0) [-204.8|204.775] "A" Host
 SG_ BATT_fetChgDiagVMeasPrime_11 : 32|16@1- (0.005,0) [-163.84|163.835] "V" Host
 SG_ BATT_fetChgDiagVMeas_11 : 16|16@1- (0.005,0) [-163.84|163.835] "V" Host
 SG_ BATT_fetChgDiagOpenResult_11 : 3|3@1+ (1,0) [0|7] "" Host
 SG_ BATT_fetChgDiagClosedResult_11 : 0|3@1+ (1,0) [0|7] "" Host

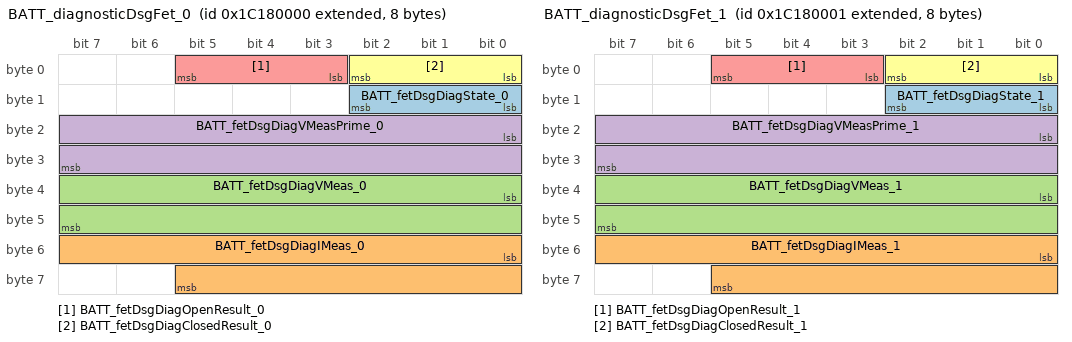
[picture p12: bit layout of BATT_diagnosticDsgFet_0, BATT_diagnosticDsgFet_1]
BO_ 2618818560 BATT_diagnosticDsgFet_0: 8 Battery
 SG_ BATT_fetDsgDiagState_0 : 8|3@1+ (1,0) [0|7] "" Host
 SG_ BATT_fetDsgDiagIMeas_0 : 48|14@1- (0.025,0) [-204.8|204.775] "A" Host
 SG_ BATT_fetDsgDiagVMeas_0 : 32|16@1- (0.005,0) [-163.84|163.835] "V" Host
 SG_ BATT_fetDsgDiagVMeasPrime_0 : 16|16@1- (0.005,0) [-163.84|163.835] "V" Host
 SG_ BATT_fetDsgDiagOpenResult_0 : 3|3@1+ (1,0) [0|7] "" Host
 SG_ BATT_fetDsgDiagClosedResult_0 : 0|3@1+ (1,0) [0|7] "" Host

BO_ 2618818561 BATT_diagnosticDsgFet_1: 8 Battery
 SG_ BATT_fetDsgDiagState_1 : 8|3@1+ (1,0) [0|7] "" Host
 SG_ BATT_fetDsgDiagIMeas_1 : 48|14@1- (0.025,0) [-204.8|204.775] "A" Host
 SG_ BATT_fetDsgDiagVMeas_1 : 32|16@1- (0.005,0) [-163.84|163.835] "V" Host
 SG_ BATT_fetDsgDiagVMeasPrime_1 : 16|16@1- (0.005,0) [-163.84|163.835] "V" Host
 SG_ BATT_fetDsgDiagOpenResult_1 : 3|3@1+ (1,0) [0|7] "" Host
 SG_ BATT_fetDsgDiagClosedResult_1 : 0|3@1+ (1,0) [0|7] "" Host

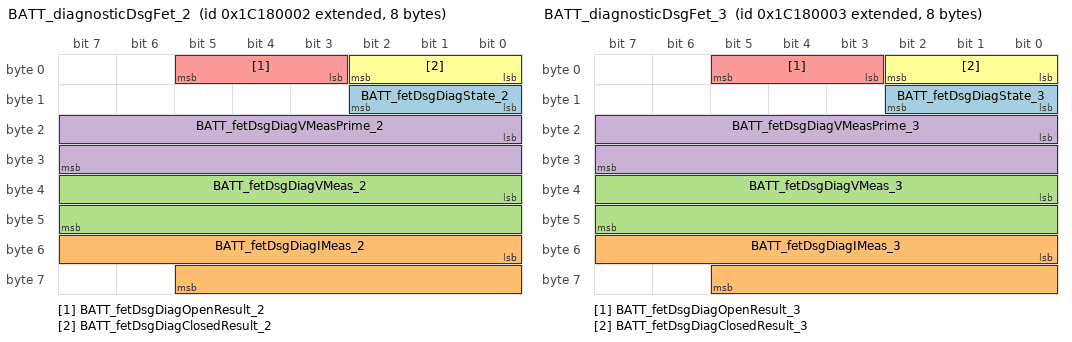
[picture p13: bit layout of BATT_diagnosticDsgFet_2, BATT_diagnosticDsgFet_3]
BO_ 2618818562 BATT_diagnosticDsgFet_2: 8 Battery
 SG_ BATT_fetDsgDiagState_2 : 8|3@1+ (1,0) [0|7] "" Host
 SG_ BATT_fetDsgDiagIMeas_2 : 48|14@1- (0.025,0) [-204.8|204.775] "A" Host
 SG_ BATT_fetDsgDiagVMeas_2 : 32|16@1- (0.005,0) [-163.84|163.835] "V" Host
 SG_ BATT_fetDsgDiagVMeasPrime_2 : 16|16@1- (0.005,0) [-163.84|163.835] "V" Host
 SG_ BATT_fetDsgDiagOpenResult_2 : 3|3@1+ (1,0) [0|7] "" Host
 SG_ BATT_fetDsgDiagClosedResult_2 : 0|3@1+ (1,0) [0|7] "" Host

BO_ 2618818563 BATT_diagnosticDsgFet_3: 8 Battery
 SG_ BATT_fetDsgDiagState_3 : 8|3@1+ (1,0) [0|7] "" Host
 SG_ BATT_fetDsgDiagIMeas_3 : 48|14@1- (0.025,0) [-204.8|204.775] "A" Host
 SG_ BATT_fetDsgDiagVMeas_3 : 32|16@1- (0.005,0) [-163.84|163.835] "V" Host
 SG_ BATT_fetDsgDiagVMeasPrime_3 : 16|16@1- (0.005,0) [-163.84|163.835] "V" Host
 SG_ BATT_fetDsgDiagOpenResult_3 : 3|3@1+ (1,0) [0|7] "" Host
 SG_ BATT_fetDsgDiagClosedResult_3 : 0|3@1+ (1,0) [0|7] "" Host

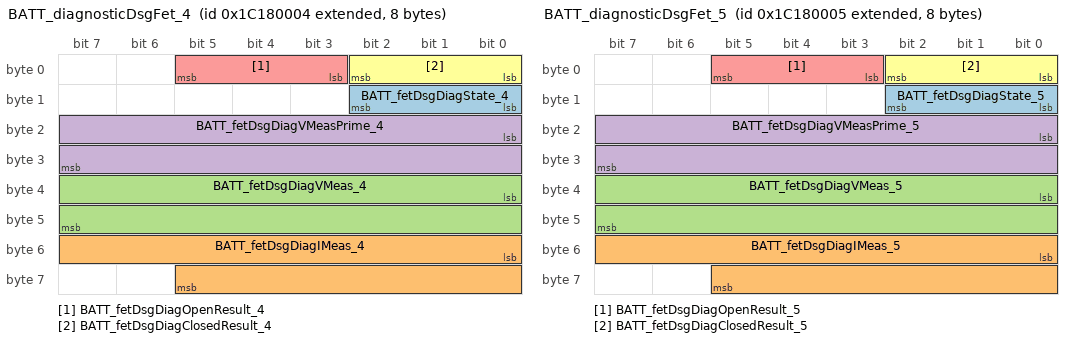
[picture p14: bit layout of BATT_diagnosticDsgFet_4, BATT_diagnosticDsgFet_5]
BO_ 2618818564 BATT_diagnosticDsgFet_4: 8 Battery
 SG_ BATT_fetDsgDiagState_4 : 8|3@1+ (1,0) [0|7] "" Host
 SG_ BATT_fetDsgDiagIMeas_4 : 48|14@1- (0.025,0) [-204.8|204.775] "A" Host
 SG_ BATT_fetDsgDiagVMeas_4 : 32|16@1- (0.005,0) [-163.84|163.835] "V" Host
 SG_ BATT_fetDsgDiagVMeasPrime_4 : 16|16@1- (0.005,0) [-163.84|163.835] "V" Host
 SG_ BATT_fetDsgDiagOpenResult_4 : 3|3@1+ (1,0) [0|7] "" Host
 SG_ BATT_fetDsgDiagClosedResult_4 : 0|3@1+ (1,0) [0|7] "" Host

BO_ 2618818565 BATT_diagnosticDsgFet_5: 8 Battery
 SG_ BATT_fetDsgDiagState_5 : 8|3@1+ (1,0) [0|7] "" Host
 SG_ BATT_fetDsgDiagIMeas_5 : 48|14@1- (0.025,0) [-204.8|204.775] "A" Host
 SG_ BATT_fetDsgDiagVMeas_5 : 32|16@1- (0.005,0) [-163.84|163.835] "V" Host
 SG_ BATT_fetDsgDiagVMeasPrime_5 : 16|16@1- (0.005,0) [-163.84|163.835] "V" Host
 SG_ BATT_fetDsgDiagOpenResult_5 : 3|3@1+ (1,0) [0|7] "" Host
 SG_ BATT_fetDsgDiagClosedResult_5 : 0|3@1+ (1,0) [0|7] "" Host

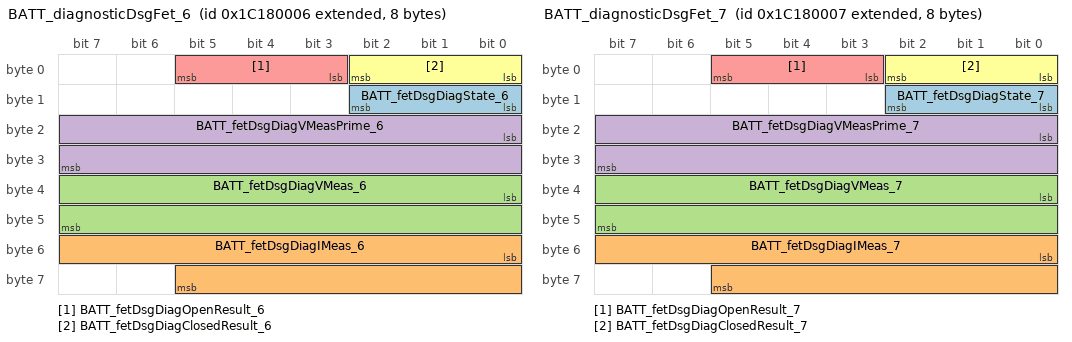
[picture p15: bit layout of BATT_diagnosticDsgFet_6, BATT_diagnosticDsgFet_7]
BO_ 2618818566 BATT_diagnosticDsgFet_6: 8 Battery
 SG_ BATT_fetDsgDiagState_6 : 8|3@1+ (1,0) [0|7] "" Host
 SG_ BATT_fetDsgDiagIMeas_6 : 48|14@1- (0.025,0) [-204.8|204.775] "A" Host
 SG_ BATT_fetDsgDiagVMeas_6 : 32|16@1- (0.005,0) [-163.84|163.835] "V" Host
 SG_ BATT_fetDsgDiagVMeasPrime_6 : 16|16@1- (0.005,0) [-163.84|163.835] "V" Host
 SG_ BATT_fetDsgDiagOpenResult_6 : 3|3@1+ (1,0) [0|7] "" Host
 SG_ BATT_fetDsgDiagClosedResult_6 : 0|3@1+ (1,0) [0|7] "" Host

BO_ 2618818567 BATT_diagnosticDsgFet_7: 8 Battery
 SG_ BATT_fetDsgDiagState_7 : 8|3@1+ (1,0) [0|7] "" Host
 SG_ BATT_fetDsgDiagIMeas_7 : 48|14@1- (0.025,0) [-204.8|204.775] "A" Host
 SG_ BATT_fetDsgDiagVMeas_7 : 32|16@1- (0.005,0) [-163.84|163.835] "V" Host
 SG_ BATT_fetDsgDiagVMeasPrime_7 : 16|16@1- (0.005,0) [-163.84|163.835] "V" Host
 SG_ BATT_fetDsgDiagOpenResult_7 : 3|3@1+ (1,0) [0|7] "" Host
 SG_ BATT_fetDsgDiagClosedResult_7 : 0|3@1+ (1,0) [0|7] "" Host

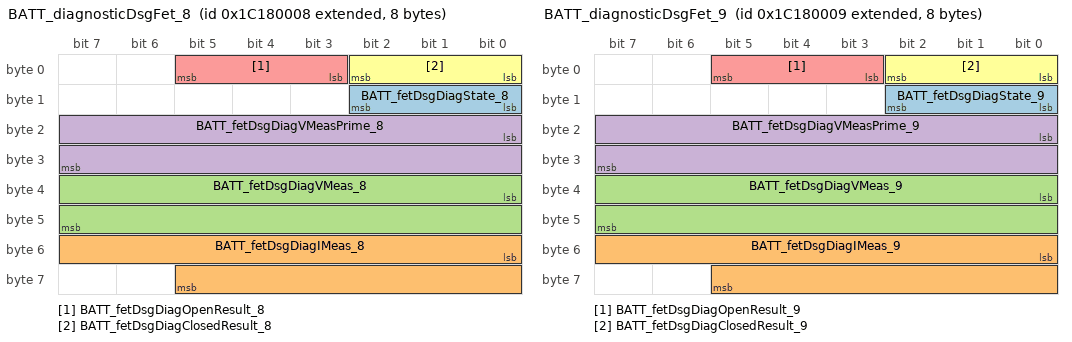
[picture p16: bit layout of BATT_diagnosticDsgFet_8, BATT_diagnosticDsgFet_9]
BO_ 2618818568 BATT_diagnosticDsgFet_8: 8 Battery
 SG_ BATT_fetDsgDiagState_8 : 8|3@1+ (1,0) [0|7] "" Host
 SG_ BATT_fetDsgDiagIMeas_8 : 48|14@1- (0.025,0) [-204.8|204.775] "A" Host
 SG_ BATT_fetDsgDiagVMeas_8 : 32|16@1- (0.005,0) [-163.84|163.835] "V" Host
 SG_ BATT_fetDsgDiagVMeasPrime_8 : 16|16@1- (0.005,0) [-163.84|163.835] "V" Host
 SG_ BATT_fetDsgDiagOpenResult_8 : 3|3@1+ (1,0) [0|7] "" Host
 SG_ BATT_fetDsgDiagClosedResult_8 : 0|3@1+ (1,0) [0|7] "" Host

BO_ 2618818569 BATT_diagnosticDsgFet_9: 8 Battery
 SG_ BATT_fetDsgDiagState_9 : 8|3@1+ (1,0) [0|7] "" Host
 SG_ BATT_fetDsgDiagIMeas_9 : 48|14@1- (0.025,0) [-204.8|204.775] "A" Host
 SG_ BATT_fetDsgDiagVMeas_9 : 32|16@1- (0.005,0) [-163.84|163.835] "V" Host
 SG_ BATT_fetDsgDiagVMeasPrime_9 : 16|16@1- (0.005,0) [-163.84|163.835] "V" Host
 SG_ BATT_fetDsgDiagOpenResult_9 : 3|3@1+ (1,0) [0|7] "" Host
 SG_ BATT_fetDsgDiagClosedResult_9 : 0|3@1+ (1,0) [0|7] "" Host

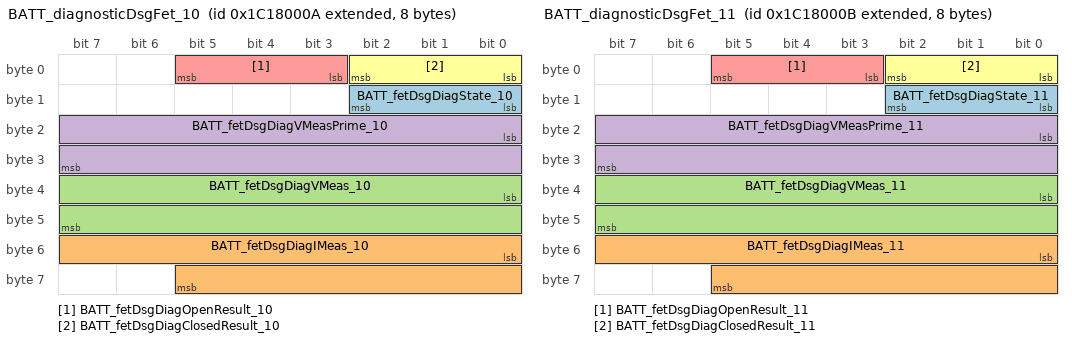
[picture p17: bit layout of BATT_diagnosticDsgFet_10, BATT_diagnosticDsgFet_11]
BO_ 2618818570 BATT_diagnosticDsgFet_10: 8 Battery
 SG_ BATT_fetDsgDiagState_10 : 8|3@1+ (1,0) [0|7] "" Host
 SG_ BATT_fetDsgDiagIMeas_10 : 48|14@1- (0.025,0) [-204.8|204.775] "A" Host
 SG_ BATT_fetDsgDiagVMeas_10 : 32|16@1- (0.005,0) [-163.84|163.835] "V" Host
 SG_ BATT_fetDsgDiagVMeasPrime_10 : 16|16@1- (0.005,0) [-163.84|163.835] "V" Host
 SG_ BATT_fetDsgDiagOpenResult_10 : 3|3@1+ (1,0) [0|7] "" Host
 SG_ BATT_fetDsgDiagClosedResult_10 : 0|3@1+ (1,0) [0|7] "" Host

BO_ 2618818571 BATT_diagnosticDsgFet_11: 8 Battery
 SG_ BATT_fetDsgDiagState_11 : 8|3@1+ (1,0) [0|7] "" Host
 SG_ BATT_fetDsgDiagIMeas_11 : 48|14@1- (0.025,0) [-204.8|204.775] "A" Host
 SG_ BATT_fetDsgDiagVMeas_11 : 32|16@1- (0.005,0) [-163.84|163.835] "V" Host
 SG_ BATT_fetDsgDiagVMeasPrime_11 : 16|16@1- (0.005,0) [-163.84|163.835] "V" Host
 SG_ BATT_fetDsgDiagOpenResult_11 : 3|3@1+ (1,0) [0|7] "" Host
 SG_ BATT_fetDsgDiagClosedResult_11 : 0|3@1+ (1,0) [0|7] "" Host

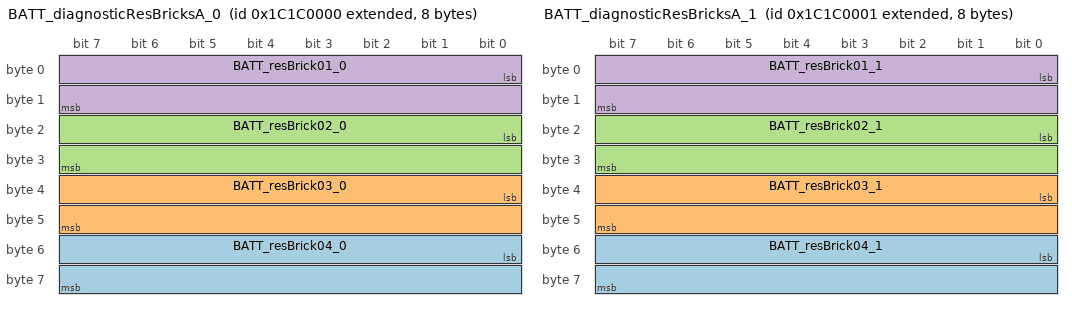
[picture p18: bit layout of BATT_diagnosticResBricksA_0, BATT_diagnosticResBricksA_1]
BO_ 2619080704 BATT_diagnosticResBricksA_0: 8 Battery
 SG_ BATT_resBrick04_0 : 48|16@1+ (0.01,0) [0|655.35] "mOhms" Host
 SG_ BATT_resBrick03_0 : 32|16@1+ (0.01,0) [0|655.35] "mOhms" Host
 SG_ BATT_resBrick02_0 : 16|16@1+ (0.01,0) [0|655.35] "mOhms" Host
 SG_ BATT_resBrick01_0 : 0|16@1+ (0.01,0) [0|655.35] "mOhms" Host

BO_ 2619080705 BATT_diagnosticResBricksA_1: 8 Battery
 SG_ BATT_resBrick04_1 : 48|16@1+ (0.01,0) [0|655.35] "mOhms" Host
 SG_ BATT_resBrick03_1 : 32|16@1+ (0.01,0) [0|655.35] "mOhms" Host
 SG_ BATT_resBrick02_1 : 16|16@1+ (0.01,0) [0|655.35] "mOhms" Host
 SG_ BATT_resBrick01_1 : 0|16@1+ (0.01,0) [0|655.35] "mOhms" Host

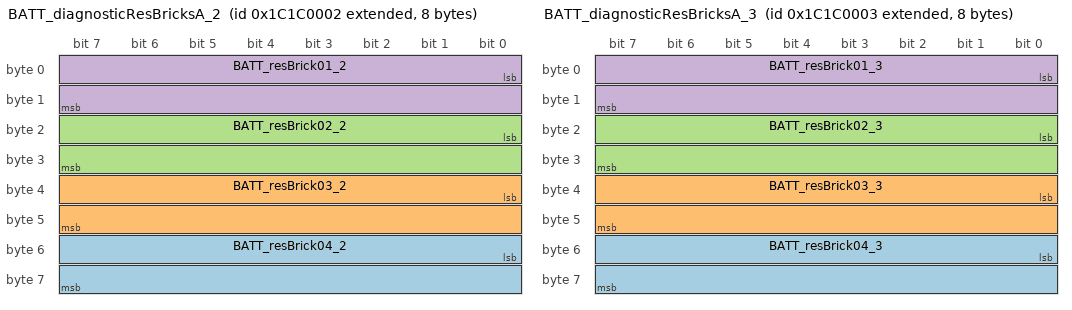
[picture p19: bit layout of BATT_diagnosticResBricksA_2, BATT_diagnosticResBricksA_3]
BO_ 2619080706 BATT_diagnosticResBricksA_2: 8 Battery
 SG_ BATT_resBrick04_2 : 48|16@1+ (0.01,0) [0|655.35] "mOhms" Host
 SG_ BATT_resBrick03_2 : 32|16@1+ (0.01,0) [0|655.35] "mOhms" Host
 SG_ BATT_resBrick02_2 : 16|16@1+ (0.01,0) [0|655.35] "mOhms" Host
 SG_ BATT_resBrick01_2 : 0|16@1+ (0.01,0) [0|655.35] "mOhms" Host

BO_ 2619080707 BATT_diagnosticResBricksA_3: 8 Battery
 SG_ BATT_resBrick04_3 : 48|16@1+ (0.01,0) [0|655.35] "mOhms" Host
 SG_ BATT_resBrick03_3 : 32|16@1+ (0.01,0) [0|655.35] "mOhms" Host
 SG_ BATT_resBrick02_3 : 16|16@1+ (0.01,0) [0|655.35] "mOhms" Host
 SG_ BATT_resBrick01_3 : 0|16@1+ (0.01,0) [0|655.35] "mOhms" Host

BO_ 2619080708 BATT_diagnosticResBricksA_4: 8 Battery
 SG_ BATT_resBrick04_4 : 48|16@1+ (0.01,0) [0|655.35] "mOhms" Host
 SG_ BATT_resBrick03_4 : 32|16@1+ (0.01,0) [0|655.35] "mOhms" Host
 SG_ BATT_resBrick02_4 : 16|16@1+ (0.01,0) [0|655.35] "mOhms" Host
 SG_ BATT_resBrick01_4 : 0|16@1+ (0.01,0) [0|655.35] "mOhms" Host

BO_ 2619080709 BATT_diagnosticResBricksA_5: 8 Battery
 SG_ BATT_resBrick04_5 : 48|16@1+ (0.01,0) [0|655.35] "mOhms" Host
 SG_ BATT_resBrick03_5 : 32|16@1+ (0.01,0) [0|655.35] "mOhms" Host
 SG_ BATT_resBrick02_5 : 16|16@1+ (0.01,0) [0|655.35] "mOhms" Host
 SG_ BATT_resBrick01_5 : 0|16@1+ (0.01,0) [0|655.35] "mOhms" Host

BO_ 2619080710 BATT_diagnosticResBricksA_6: 8 Battery
 SG_ BATT_resBrick04_6 : 48|16@1+ (0.01,0) [0|655.35] "mOhms" Host
 SG_ BATT_resBrick03_6 : 32|16@1+ (0.01,0) [0|655.35] "mOhms" Host
 SG_ BATT_resBrick02_6 : 16|16@1+ (0.01,0) [0|655.35] "mOhms" Host
 SG_ BATT_resBrick01_6 : 0|16@1+ (0.01,0) [0|655.35] "mOhms" Host

BO_ 2619080711 BATT_diagnosticResBricksA_7: 8 Battery
 SG_ BATT_resBrick04_7 : 48|16@1+ (0.01,0) [0|655.35] "mOhms" Host
 SG_ BATT_resBrick03_7 : 32|16@1+ (0.01,0) [0|655.35] "mOhms" Host
 SG_ BATT_resBrick02_7 : 16|16@1+ (0.01,0) [0|655.35] "mOhms" Host
 SG_ BATT_resBrick01_7 : 0|16@1+ (0.01,0) [0|655.35] "mOhms" Host

BO_ 2619080712 BATT_diagnosticResBricksA_8: 8 Battery
 SG_ BATT_resBrick04_8 : 48|16@1+ (0.01,0) [0|655.35] "mOhms" Host
 SG_ BATT_resBrick03_8 : 32|16@1+ (0.01,0) [0|655.35] "mOhms" Host
 SG_ BATT_resBrick02_8 : 16|16@1+ (0.01,0) [0|655.35] "mOhms" Host
 SG_ BATT_resBrick01_8 : 0|16@1+ (0.01,0) [0|655.35] "mOhms" Host

BO_ 2619080713 BATT_diagnosticResBricksA_9: 8 Battery
 SG_ BATT_resBrick04_9 : 48|16@1+ (0.01,0) [0|655.35] "mOhms" Host
 SG_ BATT_resBrick03_9 : 32|16@1+ (0.01,0) [0|655.35] "mOhms" Host
 SG_ BATT_resBrick02_9 : 16|16@1+ (0.01,0) [0|655.35] "mOhms" Host
 SG_ BATT_resBrick01_9 : 0|16@1+ (0.01,0) [0|655.35] "mOhms" Host

BO_ 2619080714 BATT_diagnosticResBricksA_10: 8 Battery
 SG_ BATT_resBrick04_10 : 48|16@1+ (0.01,0) [0|655.35] "mOhms" Host
 SG_ BATT_resBrick03_10 : 32|16@1+ (0.01,0) [0|655.35] "mOhms" Host
 SG_ BATT_resBrick02_10 : 16|16@1+ (0.01,0) [0|655.35] "mOhms" Host
 SG_ BATT_resBrick01_10 : 0|16@1+ (0.01,0) [0|655.35] "mOhms" Host

BO_ 2619080715 BATT_diagnosticResBricksA_11: 8 Battery
 SG_ BATT_resBrick04_11 : 48|16@1+ (0.01,0) [0|655.35] "mOhms" Host
 SG_ BATT_resBrick03_11 : 32|16@1+ (0.01,0) [0|655.35] "mOhms" Host
 SG_ BATT_resBrick02_11 : 16|16@1+ (0.01,0) [0|655.35] "mOhms" Host
 SG_ BATT_resBrick01_11 : 0|16@1+ (0.01,0) [0|655.35] "mOhms" Host

BO_ 2619342848 BATT_diagnosticResBricksB_0: 8 Battery
 SG_ BATT_resBrick08_0 : 48|16@1+ (0.01,0) [0|655.35] "mOhms" Host
 SG_ BATT_resBrick07_0 : 32|16@1+ (0.01,0) [0|655.35] "mOhms" Host
 SG_ BATT_resBrick06_0 : 16|16@1+ (0.01,0) [0|655.35] "mOhms" Host
 SG_ BATT_resBrick05_0 : 0|16@1+ (0.01,0) [0|655.35] "mOhms" Host

BO_ 2619342849 BATT_diagnosticResBricksB_1: 8 Battery
 SG_ BATT_resBrick08_1 : 48|16@1+ (0.01,0) [0|655.35] "mOhms" Host
 SG_ BATT_resBrick07_1 : 32|16@1+ (0.01,0) [0|655.35] "mOhms" Host
 SG_ BATT_resBrick06_1 : 16|16@1+ (0.01,0) [0|655.35] "mOhms" Host
 SG_ BATT_resBrick05_1 : 0|16@1+ (0.01,0) [0|655.35] "mOhms" Host

BO_ 2619342850 BATT_diagnosticResBricksB_2: 8 Battery
 SG_ BATT_resBrick08_2 : 48|16@1+ (0.01,0) [0|655.35] "mOhms" Host
 SG_ BATT_resBrick07_2 : 32|16@1+ (0.01,0) [0|655.35] "mOhms" Host
 SG_ BATT_resBrick06_2 : 16|16@1+ (0.01,0) [0|655.35] "mOhms" Host
 SG_ BATT_resBrick05_2 : 0|16@1+ (0.01,0) [0|655.35] "mOhms" Host

BO_ 2619342851 BATT_diagnosticResBricksB_3: 8 Battery
 SG_ BATT_resBrick08_3 : 48|16@1+ (0.01,0) [0|655.35] "mOhms" Host
 SG_ BATT_resBrick07_3 : 32|16@1+ (0.01,0) [0|655.35] "mOhms" Host
 SG_ BATT_resBrick06_3 : 16|16@1+ (0.01,0) [0|655.35] "mOhms" Host
 SG_ BATT_resBrick05_3 : 0|16@1+ (0.01,0) [0|655.35] "mOhms" Host

BO_ 2619342852 BATT_diagnosticResBricksB_4: 8 Battery
 SG_ BATT_resBrick08_4 : 48|16@1+ (0.01,0) [0|655.35] "mOhms" Host
 SG_ BATT_resBrick07_4 : 32|16@1+ (0.01,0) [0|655.35] "mOhms" Host
 SG_ BATT_resBrick06_4 : 16|16@1+ (0.01,0) [0|655.35] "mOhms" Host
 SG_ BATT_resBrick05_4 : 0|16@1+ (0.01,0) [0|655.35] "mOhms" Host

BO_ 2619342853 BATT_diagnosticResBricksB_5: 8 Battery
 SG_ BATT_resBrick08_5 : 48|16@1+ (0.01,0) [0|655.35] "mOhms" Host
 SG_ BATT_resBrick07_5 : 32|16@1+ (0.01,0) [0|655.35] "mOhms" Host
 SG_ BATT_resBrick06_5 : 16|16@1+ (0.01,0) [0|655.35] "mOhms" Host
 SG_ BATT_resBrick05_5 : 0|16@1+ (0.01,0) [0|655.35] "mOhms" Host

BO_ 2619342854 BATT_diagnosticResBricksB_6: 8 Battery
 SG_ BATT_resBrick08_6 : 48|16@1+ (0.01,0) [0|655.35] "mOhms" Host
 SG_ BATT_resBrick07_6 : 32|16@1+ (0.01,0) [0|655.35] "mOhms" Host
 SG_ BATT_resBrick06_6 : 16|16@1+ (0.01,0) [0|655.35] "mOhms" Host
 SG_ BATT_resBrick05_6 : 0|16@1+ (0.01,0) [0|655.35] "mOhms" Host

BO_ 2619342855 BATT_diagnosticResBricksB_7: 8 Battery
 SG_ BATT_resBrick08_7 : 48|16@1+ (0.01,0) [0|655.35] "mOhms" Host
 SG_ BATT_resBrick07_7 : 32|16@1+ (0.01,0) [0|655.35] "mOhms" Host
 SG_ BATT_resBrick06_7 : 16|16@1+ (0.01,0) [0|655.35] "mOhms" Host
 SG_ BATT_resBrick05_7 : 0|16@1+ (0.01,0) [0|655.35] "mOhms" Host

BO_ 2619342856 BATT_diagnosticResBricksB_8: 8 Battery
 SG_ BATT_resBrick08_8 : 48|16@1+ (0.01,0) [0|655.35] "mOhms" Host
 SG_ BATT_resBrick07_8 : 32|16@1+ (0.01,0) [0|655.35] "mOhms" Host
 SG_ BATT_resBrick06_8 : 16|16@1+ (0.01,0) [0|655.35] "mOhms" Host
 SG_ BATT_resBrick05_8 : 0|16@1+ (0.01,0) [0|655.35] "mOhms" Host

BO_ 2619342857 BATT_diagnosticResBricksB_9: 8 Battery
 SG_ BATT_resBrick08_9 : 48|16@1+ (0.01,0) [0|655.35] "mOhms" Host
 SG_ BATT_resBrick07_9 : 32|16@1+ (0.01,0) [0|655.35] "mOhms" Host
 SG_ BATT_resBrick06_9 : 16|16@1+ (0.01,0) [0|655.35] "mOhms" Host
 SG_ BATT_resBrick05_9 : 0|16@1+ (0.01,0) [0|655.35] "mOhms" Host

BO_ 2619342858 BATT_diagnosticResBricksB_10: 8 Battery
 SG_ BATT_resBrick08_10 : 48|16@1+ (0.01,0) [0|655.35] "mOhms" Host
 SG_ BATT_resBrick07_10 : 32|16@1+ (0.01,0) [0|655.35] "mOhms" Host
 SG_ BATT_resBrick06_10 : 16|16@1+ (0.01,0) [0|655.35] "mOhms" Host
 SG_ BATT_resBrick05_10 : 0|16@1+ (0.01,0) [0|655.35] "mOhms" Host

BO_ 2619342859 BATT_diagnosticResBricksB_11: 8 Battery
 SG_ BATT_resBrick08_11 : 48|16@1+ (0.01,0) [0|655.35] "mOhms" Host
 SG_ BATT_resBrick07_11 : 32|16@1+ (0.01,0) [0|655.35] "mOhms" Host
 SG_ BATT_resBrick06_11 : 16|16@1+ (0.01,0) [0|655.35] "mOhms" Host
 SG_ BATT_resBrick05_11 : 0|16@1+ (0.01,0) [0|655.35] "mOhms" Host

BO_ 2619604992 BATT_diagnosticResBricksC_0: 8 Battery
 SG_ BATT_resBrick12_0 : 48|16@1+ (0.01,0) [0|655.35] "mOhms" Host
 SG_ BATT_resBrick11_0 : 32|16@1+ (0.01,0) [0|655.35] "mOhms" Host
 SG_ BATT_resBrick09_0 : 0|16@1+ (0.01,0) [0|655.35] "mOhms" Host
 SG_ BATT_resBrick10_0 : 16|16@1+ (0.01,0) [0|655.35] "mOhms" Host

BO_ 2619604993 BATT_diagnosticResBricksC_1: 8 Battery
 SG_ BATT_resBrick12_1 : 48|16@1+ (0.01,0) [0|655.35] "mOhms" Host
 SG_ BATT_resBrick11_1 : 32|16@1+ (0.01,0) [0|655.35] "mOhms" Host
 SG_ BATT_resBrick09_1 : 0|16@1+ (0.01,0) [0|655.35] "mOhms" Host
 SG_ BATT_resBrick10_1 : 16|16@1+ (0.01,0) [0|655.35] "mOhms" Host

BO_ 2619604994 BATT_diagnosticResBricksC_2: 8 Battery
 SG_ BATT_resBrick12_2 : 48|16@1+ (0.01,0) [0|655.35] "mOhms" Host
 SG_ BATT_resBrick11_2 : 32|16@1+ (0.01,0) [0|655.35] "mOhms" Host
 SG_ BATT_resBrick09_2 : 0|16@1+ (0.01,0) [0|655.35] "mOhms" Host
 SG_ BATT_resBrick10_2 : 16|16@1+ (0.01,0) [0|655.35] "mOhms" Host

BO_ 2619604995 BATT_diagnosticResBricksC_3: 8 Battery
 SG_ BATT_resBrick12_3 : 48|16@1+ (0.01,0) [0|655.35] "mOhms" Host
 SG_ BATT_resBrick11_3 : 32|16@1+ (0.01,0) [0|655.35] "mOhms" Host
 SG_ BATT_resBrick09_3 : 0|16@1+ (0.01,0) [0|655.35] "mOhms" Host
 SG_ BATT_resBrick10_3 : 16|16@1+ (0.01,0) [0|655.35] "mOhms" Host

BO_ 2619604996 BATT_diagnosticResBricksC_4: 8 Battery
 SG_ BATT_resBrick12_4 : 48|16@1+ (0.01,0) [0|655.35] "mOhms" Host
 SG_ BATT_resBrick11_4 : 32|16@1+ (0.01,0) [0|655.35] "mOhms" Host
 SG_ BATT_resBrick09_4 : 0|16@1+ (0.01,0) [0|655.35] "mOhms" Host
 SG_ BATT_resBrick10_4 : 16|16@1+ (0.01,0) [0|655.35] "mOhms" Host

BO_ 2619604997 BATT_diagnosticResBricksC_5: 8 Battery
 SG_ BATT_resBrick12_5 : 48|16@1+ (0.01,0) [0|655.35] "mOhms" Host
 SG_ BATT_resBrick11_5 : 32|16@1+ (0.01,0) [0|655.35] "mOhms" Host
 SG_ BATT_resBrick09_5 : 0|16@1+ (0.01,0) [0|655.35] "mOhms" Host
 SG_ BATT_resBrick10_5 : 16|16@1+ (0.01,0) [0|655.35] "mOhms" Host

BO_ 2619604998 BATT_diagnosticResBricksC_6: 8 Battery
 SG_ BATT_resBrick12_6 : 48|16@1+ (0.01,0) [0|655.35] "mOhms" Host
 SG_ BATT_resBrick11_6 : 32|16@1+ (0.01,0) [0|655.35] "mOhms" Host
 SG_ BATT_resBrick09_6 : 0|16@1+ (0.01,0) [0|655.35] "mOhms" Host
 SG_ BATT_resBrick10_6 : 16|16@1+ (0.01,0) [0|655.35] "mOhms" Host

BO_ 2619604999 BATT_diagnosticResBricksC_7: 8 Battery
 SG_ BATT_resBrick12_7 : 48|16@1+ (0.01,0) [0|655.35] "mOhms" Host
 SG_ BATT_resBrick11_7 : 32|16@1+ (0.01,0) [0|655.35] "mOhms" Host
 SG_ BATT_resBrick09_7 : 0|16@1+ (0.01,0) [0|655.35] "mOhms" Host
 SG_ BATT_resBrick10_7 : 16|16@1+ (0.01,0) [0|655.35] "mOhms" Host

BO_ 2619605000 BATT_diagnosticResBricksC_8: 8 Battery
 SG_ BATT_resBrick12_8 : 48|16@1+ (0.01,0) [0|655.35] "mOhms" Host
 SG_ BATT_resBrick11_8 : 32|16@1+ (0.01,0) [0|655.35] "mOhms" Host
 SG_ BATT_resBrick09_8 : 0|16@1+ (0.01,0) [0|655.35] "mOhms" Host
 SG_ BATT_resBrick10_8 : 16|16@1+ (0.01,0) [0|655.35] "mOhms" Host

BO_ 2619605001 BATT_diagnosticResBricksC_9: 8 Battery
 SG_ BATT_resBrick12_9 : 48|16@1+ (0.01,0) [0|655.35] "mOhms" Host
 SG_ BATT_resBrick11_9 : 32|16@1+ (0.01,0) [0|655.35] "mOhms" Host
 SG_ BATT_resBrick09_9 : 0|16@1+ (0.01,0) [0|655.35] "mOhms" Host
 SG_ BATT_resBrick10_9 : 16|16@1+ (0.01,0) [0|655.35] "mOhms" Host

BO_ 2619605002 BATT_diagnosticResBricksC_10: 8 Battery
 SG_ BATT_resBrick12_10 : 48|16@1+ (0.01,0) [0|655.35] "mOhms" Host
 SG_ BATT_resBrick11_10 : 32|16@1+ (0.01,0) [0|655.35] "mOhms" Host
 SG_ BATT_resBrick09_10 : 0|16@1+ (0.01,0) [0|655.35] "mOhms" Host
 SG_ BATT_resBrick10_10 : 16|16@1+ (0.01,0) [0|655.35] "mOhms" Host

BO_ 2619605003 BATT_diagnosticResBricksC_11: 8 Battery
 SG_ BATT_resBrick12_11 : 48|16@1+ (0.01,0) [0|655.35] "mOhms" Host
 SG_ BATT_resBrick11_11 : 32|16@1+ (0.01,0) [0|655.35] "mOhms" Host
 SG_ BATT_resBrick09_11 : 0|16@1+ (0.01,0) [0|655.35] "mOhms" Host
 SG_ BATT_resBrick10_11 : 16|16@1+ (0.01,0) [0|655.35] "mOhms" Host

BO_ 2620653568 BATT_sleepWake_0: 1 Battery
 SG_ BATT_wakeReason_0 : 4|4@1+ (1,0) [0|15] "" Host

BO_ 2620653569 BATT_sleepWake_1: 1 Battery
 SG_ BATT_wakeReason_1 : 4|4@1+ (1,0) [0|15] "" Host

BO_ 2620653570 BATT_sleepWake_2: 1 Battery
 SG_ BATT_wakeReason_2 : 4|4@1+ (1,0) [0|15] "" Host

BO_ 2620653571 BATT_sleepWake_3: 1 Battery
 SG_ BATT_wakeReason_3 : 4|4@1+ (1,0) [0|15] "" Host

BO_ 2620653572 BATT_sleepWake_4: 1 Battery
 SG_ BATT_wakeReason_4 : 4|4@1+ (1,0) [0|15] "" Host

BO_ 2620653573 BATT_sleepWake_5: 1 Battery
 SG_ BATT_wakeReason_5 : 4|4@1+ (1,0) [0|15] "" Host

BO_ 2620653574 BATT_sleepWake_6: 1 Battery
 SG_ BATT_wakeReason_6 : 4|4@1+ (1,0) [0|15] "" Host

BO_ 2620653575 BATT_sleepWake_7: 1 Battery
 SG_ BATT_wakeReason_7 : 4|4@1+ (1,0) [0|15] "" Host

BO_ 2620653576 BATT_sleepWake_8: 1 Battery
 SG_ BATT_wakeReason_8 : 4|4@1+ (1,0) [0|15] "" Host

BO_ 2620653577 BATT_sleepWake_9: 1 Battery
 SG_ BATT_wakeReason_9 : 4|4@1+ (1,0) [0|15] "" Host

BO_ 2620653578 BATT_sleepWake_10: 1 Battery
 SG_ BATT_wakeReason_10 : 4|4@1+ (1,0) [0|15] "" Host

BO_ 2620653579 BATT_sleepWake_11: 1 Battery
 SG_ BATT_wakeReason_11 : 4|4@1+ (1,0) [0|15] "" Host

BO_ 2620915712 BATT_diagnosticSleepWake_0: 8 Battery
 SG_ BATT_timeSleepCycle_0 : 32|32@1+ (1,0) [0|4294967295] "seconds" Host
 SG_ BATT_timeWakeCycle_0 : 0|32@1+ (1,0) [0|4294967295] "seconds" Host

BO_ 2620915713 BATT_diagnosticSleepWake_1: 8 Battery
 SG_ BATT_timeSleepCycle_1 : 32|32@1+ (1,0) [0|4294967295] "seconds" Host
 SG_ BATT_timeWakeCycle_1 : 0|32@1+ (1,0) [0|4294967295] "seconds" Host

BO_ 2620915714 BATT_diagnosticSleepWake_2: 8 Battery
 SG_ BATT_timeSleepCycle_2 : 32|32@1+ (1,0) [0|4294967295] "seconds" Host
 SG_ BATT_timeWakeCycle_2 : 0|32@1+ (1,0) [0|4294967295] "seconds" Host

BO_ 2620915715 BATT_diagnosticSleepWake_3: 8 Battery
 SG_ BATT_timeSleepCycle_3 : 32|32@1+ (1,0) [0|4294967295] "seconds" Host
 SG_ BATT_timeWakeCycle_3 : 0|32@1+ (1,0) [0|4294967295] "seconds" Host

BO_ 2620915716 BATT_diagnosticSleepWake_4: 8 Battery
 SG_ BATT_timeSleepCycle_4 : 32|32@1+ (1,0) [0|4294967295] "seconds" Host
 SG_ BATT_timeWakeCycle_4 : 0|32@1+ (1,0) [0|4294967295] "seconds" Host

BO_ 2620915717 BATT_diagnosticSleepWake_5: 8 Battery
 SG_ BATT_timeSleepCycle_5 : 32|32@1+ (1,0) [0|4294967295] "seconds" Host
 SG_ BATT_timeWakeCycle_5 : 0|32@1+ (1,0) [0|4294967295] "seconds" Host

BO_ 2620915718 BATT_diagnosticSleepWake_6: 8 Battery
 SG_ BATT_timeSleepCycle_6 : 32|32@1+ (1,0) [0|4294967295] "seconds" Host
 SG_ BATT_timeWakeCycle_6 : 0|32@1+ (1,0) [0|4294967295] "seconds" Host

BO_ 2620915719 BATT_diagnosticSleepWake_7: 8 Battery
 SG_ BATT_timeSleepCycle_7 : 32|32@1+ (1,0) [0|4294967295] "seconds" Host
 SG_ BATT_timeWakeCycle_7 : 0|32@1+ (1,0) [0|4294967295] "seconds" Host

BO_ 2620915720 BATT_diagnosticSleepWake_8: 8 Battery
 SG_ BATT_timeSleepCycle_8 : 32|32@1+ (1,0) [0|4294967295] "seconds" Host
 SG_ BATT_timeWakeCycle_8 : 0|32@1+ (1,0) [0|4294967295] "seconds" Host

BO_ 2620915721 BATT_diagnosticSleepWake_9: 8 Battery
 SG_ BATT_timeSleepCycle_9 : 32|32@1+ (1,0) [0|4294967295] "seconds" Host
 SG_ BATT_timeWakeCycle_9 : 0|32@1+ (1,0) [0|4294967295] "seconds" Host

BO_ 2620915722 BATT_diagnosticSleepWake_10: 8 Battery
 SG_ BATT_timeSleepCycle_10 : 32|32@1+ (1,0) [0|4294967295] "seconds" Host
 SG_ BATT_timeWakeCycle_10 : 0|32@1+ (1,0) [0|4294967295] "seconds" Host

BO_ 2620915723 BATT_diagnosticSleepWake_11: 8 Battery
 SG_ BATT_timeSleepCycle_11 : 32|32@1+ (1,0) [0|4294967295] "seconds" Host
 SG_ BATT_timeWakeCycle_11 : 0|32@1+ (1,0) [0|4294967295] "seconds" Host

BO_ 2621440000 BATT_diagnosticResBricksD_0: 4 Battery
 SG_ BATT_resBrick14_0 : 16|16@1+ (0.01,0) [0|655.35] "mOhms" Host
 SG_ BATT_resBrick13_0 : 0|16@1+ (0.01,0) [0|655.35] "mOhms" Host

BO_ 2621440001 BATT_diagnosticResBricksD_1: 4 Battery
 SG_ BATT_resBrick14_1 : 16|16@1+ (0.01,0) [0|655.35] "mOhms" Host
 SG_ BATT_resBrick13_1 : 0|16@1+ (0.01,0) [0|655.35] "mOhms" Host

BO_ 2621440002 BATT_diagnosticResBricksD_2: 4 Battery
 SG_ BATT_resBrick14_2 : 16|16@1+ (0.01,0) [0|655.35] "mOhms" Host
 SG_ BATT_resBrick13_2 : 0|16@1+ (0.01,0) [0|655.35] "mOhms" Host

BO_ 2621440003 BATT_diagnosticResBricksD_3: 4 Battery
 SG_ BATT_resBrick14_3 : 16|16@1+ (0.01,0) [0|655.35] "mOhms" Host
 SG_ BATT_resBrick13_3 : 0|16@1+ (0.01,0) [0|655.35] "mOhms" Host

BO_ 2621440004 BATT_diagnosticResBricksD_4: 4 Battery
 SG_ BATT_resBrick14_4 : 16|16@1+ (0.01,0) [0|655.35] "mOhms" Host
 SG_ BATT_resBrick13_4 : 0|16@1+ (0.01,0) [0|655.35] "mOhms" Host

BO_ 2621440005 BATT_diagnosticResBricksD_5: 4 Battery
 SG_ BATT_resBrick14_5 : 16|16@1+ (0.01,0) [0|655.35] "mOhms" Host
 SG_ BATT_resBrick13_5 : 0|16@1+ (0.01,0) [0|655.35] "mOhms" Host

BO_ 2621440006 BATT_diagnosticResBricksD_6: 4 Battery
 SG_ BATT_resBrick14_6 : 16|16@1+ (0.01,0) [0|655.35] "mOhms" Host
 SG_ BATT_resBrick13_6 : 0|16@1+ (0.01,0) [0|655.35] "mOhms" Host

BO_ 2621440007 BATT_diagnosticResBricksD_7: 4 Battery
 SG_ BATT_resBrick14_7 : 16|16@1+ (0.01,0) [0|655.35] "mOhms" Host
 SG_ BATT_resBrick13_7 : 0|16@1+ (0.01,0) [0|655.35] "mOhms" Host

BO_ 2621440008 BATT_diagnosticResBricksD_8: 4 Battery
 SG_ BATT_resBrick14_8 : 16|16@1+ (0.01,0) [0|655.35] "mOhms" Host
 SG_ BATT_resBrick13_8 : 0|16@1+ (0.01,0) [0|655.35] "mOhms" Host

BO_ 2621440009 BATT_diagnosticResBricksD_9: 4 Battery
 SG_ BATT_resBrick14_9 : 16|16@1+ (0.01,0) [0|655.35] "mOhms" Host
 SG_ BATT_resBrick13_9 : 0|16@1+ (0.01,0) [0|655.35] "mOhms" Host

BO_ 2621440010 BATT_diagnosticResBricksD_10: 4 Battery
 SG_ BATT_resBrick14_10 : 16|16@1+ (0.01,0) [0|655.35] "mOhms" Host
 SG_ BATT_resBrick13_10 : 0|16@1+ (0.01,0) [0|655.35] "mOhms" Host

BO_ 2621440011 BATT_diagnosticResBricksD_11: 4 Battery
 SG_ BATT_resBrick14_11 : 16|16@1+ (0.01,0) [0|655.35] "mOhms" Host
 SG_ BATT_resBrick13_11 : 0|16@1+ (0.01,0) [0|655.35] "mOhms" Host

BO_ 2621702144 BATT_diagnosticCapBricksA_0: 8 Battery
 SG_ BATT_capBrick04_0 : 48|16@1+ (0.00075,0) [0|49.15125] "Ah" Host
 SG_ BATT_capBrick03_0 : 32|16@1+ (0.00075,0) [0|49.15125] "Ah" Host
 SG_ BATT_capBrick02_0 : 16|16@1+ (0.00075,0) [0|49.15125] "Ah" Host
 SG_ BATT_capBrick01_0 : 0|16@1+ (0.00075,0) [0|49.15125] "Ah" Host

BO_ 2621702145 BATT_diagnosticCapBricksA_1: 8 Battery
 SG_ BATT_capBrick04_1 : 48|16@1+ (0.00075,0) [0|49.15125] "Ah" Host
 SG_ BATT_capBrick03_1 : 32|16@1+ (0.00075,0) [0|49.15125] "Ah" Host
 SG_ BATT_capBrick02_1 : 16|16@1+ (0.00075,0) [0|49.15125] "Ah" Host
 SG_ BATT_capBrick01_1 : 0|16@1+ (0.00075,0) [0|49.15125] "Ah" Host

BO_ 2621702146 BATT_diagnosticCapBricksA_2: 8 Battery
 SG_ BATT_capBrick04_2 : 48|16@1+ (0.00075,0) [0|49.15125] "Ah" Host
 SG_ BATT_capBrick03_2 : 32|16@1+ (0.00075,0) [0|49.15125] "Ah" Host
 SG_ BATT_capBrick02_2 : 16|16@1+ (0.00075,0) [0|49.15125] "Ah" Host
 SG_ BATT_capBrick01_2 : 0|16@1+ (0.00075,0) [0|49.15125] "Ah" Host

BO_ 2621702147 BATT_diagnosticCapBricksA_3: 8 Battery
 SG_ BATT_capBrick04_3 : 48|16@1+ (0.00075,0) [0|49.15125] "Ah" Host
 SG_ BATT_capBrick03_3 : 32|16@1+ (0.00075,0) [0|49.15125] "Ah" Host
 SG_ BATT_capBrick02_3 : 16|16@1+ (0.00075,0) [0|49.15125] "Ah" Host
 SG_ BATT_capBrick01_3 : 0|16@1+ (0.00075,0) [0|49.15125] "Ah" Host

BO_ 2621702148 BATT_diagnosticCapBricksA_4: 8 Battery
 SG_ BATT_capBrick04_4 : 48|16@1+ (0.00075,0) [0|49.15125] "Ah" Host
 SG_ BATT_capBrick03_4 : 32|16@1+ (0.00075,0) [0|49.15125] "Ah" Host
 SG_ BATT_capBrick02_4 : 16|16@1+ (0.00075,0) [0|49.15125] "Ah" Host
 SG_ BATT_capBrick01_4 : 0|16@1+ (0.00075,0) [0|49.15125] "Ah" Host

BO_ 2621702149 BATT_diagnosticCapBricksA_5: 8 Battery
 SG_ BATT_capBrick04_5 : 48|16@1+ (0.00075,0) [0|49.15125] "Ah" Host
 SG_ BATT_capBrick03_5 : 32|16@1+ (0.00075,0) [0|49.15125] "Ah" Host
 SG_ BATT_capBrick02_5 : 16|16@1+ (0.00075,0) [0|49.15125] "Ah" Host
 SG_ BATT_capBrick01_5 : 0|16@1+ (0.00075,0) [0|49.15125] "Ah" Host

BO_ 2621702150 BATT_diagnosticCapBricksA_6: 8 Battery
 SG_ BATT_capBrick04_6 : 48|16@1+ (0.00075,0) [0|49.15125] "Ah" Host
 SG_ BATT_capBrick03_6 : 32|16@1+ (0.00075,0) [0|49.15125] "Ah" Host
 SG_ BATT_capBrick02_6 : 16|16@1+ (0.00075,0) [0|49.15125] "Ah" Host
 SG_ BATT_capBrick01_6 : 0|16@1+ (0.00075,0) [0|49.15125] "Ah" Host

CM_ BO_ 2571108363 "Message with flags from event matrix";
CM_ SG_ 2571108363 BATT_packModIdFault_11 "0 - Battery pack module ID okay (default)
1 - Battery pack module ID fault";
CM_ SG_ 2571108363 BATT_packModExitedFromBus_11 "0 - Battery pack modules OK (default)
1 - Battery pack module(s) exited from the bus during charge or drive";
CM_ SG_ 2571108363 BATT_packFetChgWelded_11 "0 - Battery pack module CHG FETs not welded (default)
1 - Battery pack module CHG FETs welded ";
CM_ SG_ 2571108363 BATT_packFetDsgWelded_11 "0 - Battery pack module DSG FETs not welded (default)
1 - Battery pack module DSG FETs welded ";
CM_ SG_ 2571108363 BATT_fetDsgShortedAux_11 "0 - FETs are operational (default)
1 - FET is shorted detected by auxiliary diagnostic";
CM_ SG_ 2571108363 BATT_fetChgShortedAux_11 "0 - FETs are operational (default)
1 - FET is shorted detected by auxiliary diagnostic";
CM_ SG_ 2571108363 BATT_prechargeFetFail_11 "0 - Precharge FET okay (default)
1 - Precharge FET failed";
CM_ SG_ 2571108363 BATT_abnormalResetReason_11 "0 - Reset reason okay (default)
1 - Abnormal reset reason";
CM_ SG_ 2571108363 BATT_prechargeTooSlow_11 "0 - Precharge okay (default)
1 - Precharge too slow";
CM_ SG_ 2571108363 BATT_prechargeTooFast_11 "0 - Precharge okay (default)
1 - Precharge too fast";
CM_ SG_ 2571108363 BATT_prechargeTimeout_11 "0 - Precharge okay (default)
1 - Precharge timeout";
CM_ SG_ 2571108363 BATT_fetChgShorted_11 "0 - FETs are operational (default)
1 - FET is shorted";
CM_ SG_ 2571108363 BATT_fetChgFailToClose_11 "0 - FETs are operational (default)
1 -  FET fail to close";
CM_ SG_ 2571108363 BATT_packModSelectFault_11 "0 - Battery pack module selection okay (default)
1 - Battery pack module selection fault";
CM_ SG_ 2571108363 BATT_packModConnectFault_11 "0 - Battery pack module connection okay (default)
1 - Battery pack module connection fault";
CM_ SG_ 2571108363 BATT_packModMIA_11 "0 - Battery pack modules not MIA (default)
1 - Battery pack module MIA";
CM_ SG_ 2571108363 BATT_packModImbalance_11 "0 - Battery pack modules balanced (default)
1 - Battery pack module imblance present";
CM_ SG_ 2571108363 BATT_afeFault_11 "0 - BMS AFE okay (default)
1 - BMS AFE fault";
CM_ SG_ 2571108363 BATT_chargerMIA_11 "0 - Charger communications okay (default)
1 - Charger MIA";
CM_ SG_ 2571108363 BATT_chargerError_11 "0 - Charger working as intended (default)
1 - Charger error";
CM_ SG_ 2571108363 BATT_vBrickUnderWar_11 "0 - Brick voltage okay (default)
1 - Brick undervoltage warning";
CM_ SG_ 2571108363 BATT_vBrickUnderSev_11 "0 - Brick voltage okay (default)
1 - Brick undervoltage severe";
CM_ SG_ 2571108363 BATT_vBrickUnderMod_11 "0 - Brick voltage okay (default)
1 - Brick undervoltage moderate";
CM_ SG_ 2571108363 BATT_vBrickOverWar_11 "0 - Brick voltage okay (default)
1 - Brick overvoltage warning";
CM_ SG_ 2571108363 BATT_vBrickOverSev_11 "0 - Brick voltage okay (default)
1 - Brick overvoltage severe";
CM_ SG_ 2571108363 BATT_vBrickOverMod_11 "0 - Brick voltage okay (default)
1 - Brick overvoltage moderate";
CM_ SG_ 2571108363 BATT_vBrickImbalance_11 "0 - Battery brick voltage okay (default)
1 - Battery brick voltage imbalance";
CM_ SG_ 2571108363 BATT_loggerAlmostFull_11 "0 - Logger not almost full (default)
1 - Logger almost full (section >= 80%) ";
CM_ SG_ 2571108363 BATT_tempModuleUnderWar_11 "0 - Battery temperature okay (default)
1 - Battery under temperature warning";
CM_ SG_ 2571108363 BATT_tempModuleUnderSev_11 "0 - Battery temperature okay (default)
1 - Battery under temperature severe";
CM_ SG_ 2571108363 BATT_tempModuleUnderMod_11 "0 - Battery temperature okay (default)
1 - Battery under temperature moderate";
CM_ SG_ 2571108363 BATT_tempModuleOverWar_11 "0 - Battery temperature okay (default)
1 - Battery over temperature warning";
CM_ SG_ 2571108363 BATT_tempModuleOverSev_11 "0 - Battery temperature okay (default)
1 - Battery over temperature severe";
CM_ SG_ 2571108363 BATT_tempModuleOverMod_11 "0 - Battery temperature okay (default)
1 - Battery over temperature moderate";
CM_ SG_ 2571108363 BATT_tempBrickImbalance_11 "0 - Brick temperatures are balanced (default)
1 - Brick temperatures are imbalanced";
CM_ SG_ 2571108363 BATT_taskLockupError_11 "0 - Tasks okay (default)
1 - Task lockup error";
CM_ SG_ 2571108363 BATT_tempAmbientOverWar_11 "0 - Ambient temperature okay (default)
1 - Ambient over temperature warning";
CM_ SG_ 2571108363 BATT_tempAmbientOverSev_11 "0 - Temperature okay (default)
1 - Ambient over temperature severe";
CM_ SG_ 2571108363 BATT_tempAmbientOverMod_11 "0 - Ambient temperature okay (default)
1 - Ambient over temparature moderate";
CM_ SG_ 2571108363 BATT_sensePackVoltError_11 "0 - Sensor okay (default)
1 - Sensor for pack voltage error";
CM_ SG_ 2571108363 BATT_senseLoadVoltError_11 "0 - Sensor okay (default)
1 - Sensor for load voltage error";
CM_ SG_ 2571108363 BATT_loggerFull_11 "0 - Logger not full (default)
1 - Logger full ";
CM_ SG_ 2571108363 BATT_senseCurrentError_11 "0 - Sensor okay (default)
1 - Sensor for current error";
CM_ SG_ 2571108363 BATT_senseBrickTempError_11 "0 - Sensor okay (default)
1 - Brick temperature sensor error";
CM_ SG_ 2571108363 BATT_resPackHigh_11 "0 - Battery pack resistance okay (default)
1 - Battery pack resistance high (High SOH-R)";
CM_ SG_ 2571108363 BATT_ramOverUtilError_11 "0 - RAM okay (default)
1 - RAM over utilization";
CM_ SG_ 2571108363 BATT_powerPackInsufficient_11 "0 - Battery pack power okay (default)
1 - Battery pack power insufficient";
CM_ SG_ 2571108363 BATT_packCellSoftShort_11 "0 - Battery back cells are okay (default)
1 - Battery pack cell soft short";
CM_ SG_ 2571108363 BATT_iOverHardware_11 "0 - Hardware current okay (default)
1 - Overcurrent in hardware";
CM_ SG_ 2571108363 BATT_fetOverTemp_11 "0 - FET temperature okay (default)
1 - Overtemp at FETs";
CM_ SG_ 2571108363 BATT_iOverDischarge_11 "0 - Discharge okay (default)
1 - Overcurrent during discharge";
CM_ SG_ 2571108363 BATT_iOverCharge_11 "0 - Charging okay (default)
1 - Overcurrent during charging";
CM_ SG_ 2571108363 BATT_inverterDriveMIA_11 "0 - Inverter drive present (default)
1 - Inverter drive MIA";
CM_ SG_ 2571108363 BATT_iUnderCharge_11 "0 - Normal charging (default)
1 -  Charging undercurrent (discharging)";
CM_ SG_ 2571108363 BATT_hostMIA_11 "0 - host communication open (default)
1 - host MIA";
CM_ SG_ 2571108363 BATT_fetDsgShorted_11 "0 - FETs are operational (default)
1 - FET is shorted";
CM_ SG_ 2571108363 BATT_fetDsgFailToClose_11 "0 - FETs are operational (default)
1 -  FET fail to close";
CM_ SG_ 2571108363 BATT_capLow_11 "0 - Battery capacity normal (SOH-C) (default)
1 - Low battery capacity (Low SOH-C)";
CM_ SG_ 2571108363 BATT_brickOverDischarge_11 "0 - Battery brick charge is normal (default)
1 - Battery brick is overdischarged";
CM_ SG_ 2571108363 BATT_brickOverCharge_11 "0 - Battery brick charge is normal (default)
1 - Battery brick is overcharged";
CM_ SG_ 2571108363 BATT_bmsProcessorError_11 "0 - No BMS processor failure (default)
1 - BMS processor failure";
CM_ SG_ 2571108363 BATT_bmsMemoryError_11 "0 - No BMS memory error
1 - BMS memory error";
CM_ SG_ 2571108363 BATT_afeError_11 "0 - No BMS AFE error (default)
1 - BMS AFE error";
CM_ BO_ 2572156928 "Message with flags from event matrix";
CM_ SG_ 2572156928 BATT_harnessImpedanceFault_0 "Harness Impedance fault
";
CM_ SG_ 2572156928 BATT_packLevelArbitrationFault_0 "0 - Pack Level Arbitration fault clear (default)
1 - Pack Level Arbitration fault";
CM_ SG_ 2572156928 BATT_multiIgnLoFault_0 "0 - Single module has IGN_LO connection (default)
1 - Multimodule have IGN_LO connections";
CM_ SG_ 2572156928 BATT_modThermistorShorted_0 "0 - module thermistor okay (default)
1 - module thermistor shorted";
CM_ SG_ 2572156928 BATT_modThermistorOpenWire_0 "0 - module thermistor okay (default)
1 - module thermistor open wire";
CM_ SG_ 2572156928 BATT_chargeNotNeeded_0 "0 - Local module charge needed (default)
1 - Local module charge not needed";
CM_ SG_ 2572156928 BATT_packModTempImbalance_0 "0 - Battery pack module temperatures okay (default)
1 - Battery pack module temperature imblance present";
CM_ SG_ 2572156928 BATT_packModCurrImbalance_0 "0 - Battery pack module curent okay (default)
1 - Battery pack module current imblance present";
CM_ SG_ 2572156928 BATT_flashBootCRCError_0 "0 - No flash bootloader CRC error (default)
1 - Flash bootloader CRC error";
CM_ SG_ 2572156928 BATT_flashAppCRCError_0 "0 - No flash app CRC error (default)
1 -  Flash App CRC error";
CM_ SG_ 2572156928 BATT_cellOpenWire_0 "0 - Reset reason okay (default)
1 - Abnormal reset reason";
CM_ BO_ 2572156929 "Message with flags from event matrix";
CM_ SG_ 2572156929 BATT_harnessImpedanceFault_1 "Harness Impedance fault
";
CM_ SG_ 2572156929 BATT_packLevelArbitrationFault_1 "0 - Pack Level Arbitration fault clear (default)
1 - Pack Level Arbitration fault";
CM_ SG_ 2572156929 BATT_multiIgnLoFault_1 "0 - Single module has IGN_LO connection (default)
1 - Multimodule have IGN_LO connections";
CM_ SG_ 2572156929 BATT_modThermistorShorted_1 "0 - module thermistor okay (default)
1 - module thermistor shorted";
CM_ SG_ 2572156929 BATT_modThermistorOpenWire_1 "0 - module thermistor okay (default)
1 - module thermistor open wire";
CM_ SG_ 2572156929 BATT_chargeNotNeeded_1 "0 - Local module charge needed (default)
1 - Local module charge not needed";
CM_ SG_ 2572156929 BATT_packModTempImbalance_1 "0 - Battery pack module temperatures okay (default)
1 - Battery pack module temperature imblance present";
CM_ SG_ 2572156929 BATT_packModCurrImbalance_1 "0 - Battery pack module curent okay (default)
1 - Battery pack module current imblance present";
CM_ SG_ 2572156929 BATT_flashBootCRCError_1 "0 - No flash bootloader CRC error (default)
1 - Flash bootloader CRC error";
CM_ SG_ 2572156929 BATT_flashAppCRCError_1 "0 - No flash app CRC error (default)
1 -  Flash App CRC error";
CM_ SG_ 2572156929 BATT_cellOpenWire_1 "0 - Reset reason okay (default)
1 - Abnormal reset reason";
CM_ BO_ 2572156930 "Message with flags from event matrix";
CM_ SG_ 2572156930 BATT_harnessImpedanceFault_2 "Harness Impedance fault
";
CM_ SG_ 2572156930 BATT_packLevelArbitrationFault_2 "0 - Pack Level Arbitration fault clear (default)
1 - Pack Level Arbitration fault";
CM_ SG_ 2572156930 BATT_multiIgnLoFault_2 "0 - Single module has IGN_LO connection (default)
1 - Multimodule have IGN_LO connections";
CM_ SG_ 2572156930 BATT_modThermistorShorted_2 "0 - module thermistor okay (default)
1 - module thermistor shorted";
CM_ SG_ 2572156930 BATT_modThermistorOpenWire_2 "0 - module thermistor okay (default)
1 - module thermistor open wire";
CM_ SG_ 2572156930 BATT_chargeNotNeeded_2 "0 - Local module charge needed (default)
1 - Local module charge not needed";
CM_ SG_ 2572156930 BATT_packModTempImbalance_2 "0 - Battery pack module temperatures okay (default)
1 - Battery pack module temperature imblance present";
CM_ SG_ 2572156930 BATT_packModCurrImbalance_2 "0 - Battery pack module curent okay (default)
1 - Battery pack module current imblance present";
CM_ SG_ 2572156930 BATT_flashBootCRCError_2 "0 - No flash bootloader CRC error (default)
1 - Flash bootloader CRC error";
CM_ SG_ 2572156930 BATT_flashAppCRCError_2 "0 - No flash app CRC error (default)
1 -  Flash App CRC error";
CM_ SG_ 2572156930 BATT_cellOpenWire_2 "0 - Reset reason okay (default)
1 - Abnormal reset reason";
CM_ BO_ 2572156931 "Message with flags from event matrix";
CM_ SG_ 2572156931 BATT_harnessImpedanceFault_3 "Harness Impedance fault
";
CM_ SG_ 2572156931 BATT_packLevelArbitrationFault_3 "0 - Pack Level Arbitration fault clear (default)
1 - Pack Level Arbitration fault";
CM_ SG_ 2572156931 BATT_multiIgnLoFault_3 "0 - Single module has IGN_LO connection (default)
1 - Multimodule have IGN_LO connections";
CM_ SG_ 2572156931 BATT_modThermistorShorted_3 "0 - module thermistor okay (default)
1 - module thermistor shorted";
CM_ SG_ 2572156931 BATT_modThermistorOpenWire_3 "0 - module thermistor okay (default)
1 - module thermistor open wire";
CM_ SG_ 2572156931 BATT_chargeNotNeeded_3 "0 - Local module charge needed (default)
1 - Local module charge not needed";
CM_ SG_ 2572156931 BATT_packModTempImbalance_3 "0 - Battery pack module temperatures okay (default)
1 - Battery pack module temperature imblance present";
CM_ SG_ 2572156931 BATT_packModCurrImbalance_3 "0 - Battery pack module curent okay (default)
1 - Battery pack module current imblance present";
CM_ SG_ 2572156931 BATT_flashBootCRCError_3 "0 - No flash bootloader CRC error (default)
1 - Flash bootloader CRC error";
CM_ SG_ 2572156931 BATT_flashAppCRCError_3 "0 - No flash app CRC error (default)
1 -  Flash App CRC error";
CM_ SG_ 2572156931 BATT_cellOpenWire_3 "0 - Reset reason okay (default)
1 - Abnormal reset reason";
CM_ BO_ 2572156932 "Message with flags from event matrix";
CM_ SG_ 2572156932 BATT_harnessImpedanceFault_4 "Harness Impedance fault
";
CM_ SG_ 2572156932 BATT_packLevelArbitrationFault_4 "0 - Pack Level Arbitration fault clear (default)
1 - Pack Level Arbitration fault";
CM_ SG_ 2572156932 BATT_multiIgnLoFault_4 "0 - Single module has IGN_LO connection (default)
1 - Multimodule have IGN_LO connections";
CM_ SG_ 2572156932 BATT_modThermistorShorted_4 "0 - module thermistor okay (default)
1 - module thermistor shorted";
CM_ SG_ 2572156932 BATT_modThermistorOpenWire_4 "0 - module thermistor okay (default)
1 - module thermistor open wire";
CM_ SG_ 2572156932 BATT_chargeNotNeeded_4 "0 - Local module charge needed (default)
1 - Local module charge not needed";
CM_ SG_ 2572156932 BATT_packModTempImbalance_4 "0 - Battery pack module temperatures okay (default)
1 - Battery pack module temperature imblance present";
CM_ SG_ 2572156932 BATT_packModCurrImbalance_4 "0 - Battery pack module curent okay (default)
1 - Battery pack module current imblance present";
CM_ SG_ 2572156932 BATT_flashBootCRCError_4 "0 - No flash bootloader CRC error (default)
1 - Flash bootloader CRC error";
CM_ SG_ 2572156932 BATT_flashAppCRCError_4 "0 - No flash app CRC error (default)
1 -  Flash App CRC error";
CM_ SG_ 2572156932 BATT_cellOpenWire_4 "0 - Reset reason okay (default)
1 - Abnormal reset reason";
CM_ BO_ 2572156933 "Message with flags from event matrix";
CM_ SG_ 2572156933 BATT_harnessImpedanceFault_5 "Harness Impedance fault
";
CM_ SG_ 2572156933 BATT_packLevelArbitrationFault_5 "0 - Pack Level Arbitration fault clear (default)
1 - Pack Level Arbitration fault";
CM_ SG_ 2572156933 BATT_multiIgnLoFault_5 "0 - Single module has IGN_LO connection (default)
1 - Multimodule have IGN_LO connections";
CM_ SG_ 2572156933 BATT_modThermistorShorted_5 "0 - module thermistor okay (default)
1 - module thermistor shorted";
CM_ SG_ 2572156933 BATT_modThermistorOpenWire_5 "0 - module thermistor okay (default)
1 - module thermistor open wire";
CM_ SG_ 2572156933 BATT_chargeNotNeeded_5 "0 - Local module charge needed (default)
1 - Local module charge not needed";
CM_ SG_ 2572156933 BATT_packModTempImbalance_5 "0 - Battery pack module temperatures okay (default)
1 - Battery pack module temperature imblance present";
CM_ SG_ 2572156933 BATT_packModCurrImbalance_5 "0 - Battery pack module curent okay (default)
1 - Battery pack module current imblance present";
CM_ SG_ 2572156933 BATT_flashBootCRCError_5 "0 - No flash bootloader CRC error (default)
1 - Flash bootloader CRC error";
CM_ SG_ 2572156933 BATT_flashAppCRCError_5 "0 - No flash app CRC error (default)
1 -  Flash App CRC error";
CM_ SG_ 2572156933 BATT_cellOpenWire_5 "0 - Reset reason okay (default)
1 - Abnormal reset reason";
CM_ BO_ 2572156934 "Message with flags from event matrix";
CM_ SG_ 2572156934 BATT_harnessImpedanceFault_6 "Harness Impedance fault
";
CM_ SG_ 2572156934 BATT_packLevelArbitrationFault_6 "0 - Pack Level Arbitration fault clear (default)
1 - Pack Level Arbitration fault";
CM_ SG_ 2572156934 BATT_multiIgnLoFault_6 "0 - Single module has IGN_LO connection (default)
1 - Multimodule have IGN_LO connections";
CM_ SG_ 2572156934 BATT_modThermistorShorted_6 "0 - module thermistor okay (default)
1 - module thermistor shorted";
CM_ SG_ 2572156934 BATT_modThermistorOpenWire_6 "0 - module thermistor okay (default)
1 - module thermistor open wire";
CM_ SG_ 2572156934 BATT_chargeNotNeeded_6 "0 - Local module charge needed (default)
1 - Local module charge not needed";
CM_ SG_ 2572156934 BATT_packModTempImbalance_6 "0 - Battery pack module temperatures okay (default)
1 - Battery pack module temperature imblance present";
CM_ SG_ 2572156934 BATT_packModCurrImbalance_6 "0 - Battery pack module curent okay (default)
1 - Battery pack module current imblance present";
CM_ SG_ 2572156934 BATT_flashBootCRCError_6 "0 - No flash bootloader CRC error (default)
1 - Flash bootloader CRC error";
CM_ SG_ 2572156934 BATT_flashAppCRCError_6 "0 - No flash app CRC error (default)
1 -  Flash App CRC error";
CM_ SG_ 2572156934 BATT_cellOpenWire_6 "0 - Reset reason okay (default)
1 - Abnormal reset reason";
CM_ BO_ 2572156935 "Message with flags from event matrix";
CM_ SG_ 2572156935 BATT_harnessImpedanceFault_7 "Harness Impedance fault
";
CM_ SG_ 2572156935 BATT_packLevelArbitrationFault_7 "0 - Pack Level Arbitration fault clear (default)
1 - Pack Level Arbitration fault";
CM_ SG_ 2572156935 BATT_multiIgnLoFault_7 "0 - Single module has IGN_LO connection (default)
1 - Multimodule have IGN_LO connections";
CM_ SG_ 2572156935 BATT_modThermistorShorted_7 "0 - module thermistor okay (default)
1 - module thermistor shorted";
CM_ SG_ 2572156935 BATT_modThermistorOpenWire_7 "0 - module thermistor okay (default)
1 - module thermistor open wire";
CM_ SG_ 2572156935 BATT_chargeNotNeeded_7 "0 - Local module charge needed (default)
1 - Local module charge not needed";
CM_ SG_ 2572156935 BATT_packModTempImbalance_7 "0 - Battery pack module temperatures okay (default)
1 - Battery pack module temperature imblance present";
CM_ SG_ 2572156935 BATT_packModCurrImbalance_7 "0 - Battery pack module curent okay (default)
1 - Battery pack module current imblance present";
CM_ SG_ 2572156935 BATT_flashBootCRCError_7 "0 - No flash bootloader CRC error (default)
1 - Flash bootloader CRC error";
CM_ SG_ 2572156935 BATT_flashAppCRCError_7 "0 - No flash app CRC error (default)
1 -  Flash App CRC error";
CM_ SG_ 2572156935 BATT_cellOpenWire_7 "0 - Reset reason okay (default)
1 - Abnormal reset reason";
CM_ BO_ 2572156936 "Message with flags from event matrix";
CM_ SG_ 2572156936 BATT_harnessImpedanceFault_8 "Harness Impedance fault
";
CM_ SG_ 2572156936 BATT_packLevelArbitrationFault_8 "0 - Pack Level Arbitration fault clear (default)
1 - Pack Level Arbitration fault";
CM_ SG_ 2572156936 BATT_multiIgnLoFault_8 "0 - Single module has IGN_LO connection (default)
1 - Multimodule have IGN_LO connections";
CM_ SG_ 2572156936 BATT_modThermistorShorted_8 "0 - module thermistor okay (default)
1 - module thermistor shorted";
CM_ SG_ 2572156936 BATT_modThermistorOpenWire_8 "0 - module thermistor okay (default)
1 - module thermistor open wire";
CM_ SG_ 2572156936 BATT_chargeNotNeeded_8 "0 - Local module charge needed (default)
1 - Local module charge not needed";
CM_ SG_ 2572156936 BATT_packModTempImbalance_8 "0 - Battery pack module temperatures okay (default)
1 - Battery pack module temperature imblance present";
CM_ SG_ 2572156936 BATT_packModCurrImbalance_8 "0 - Battery pack module curent okay (default)
1 - Battery pack module current imblance present";
CM_ SG_ 2572156936 BATT_flashBootCRCError_8 "0 - No flash bootloader CRC error (default)
1 - Flash bootloader CRC error";
CM_ SG_ 2572156936 BATT_flashAppCRCError_8 "0 - No flash app CRC error (default)
1 -  Flash App CRC error";
CM_ SG_ 2572156936 BATT_cellOpenWire_8 "0 - Reset reason okay (default)
1 - Abnormal reset reason";
CM_ BO_ 2572156937 "Message with flags from event matrix";
CM_ SG_ 2572156937 BATT_harnessImpedanceFault_9 "Harness Impedance fault
";
CM_ SG_ 2572156937 BATT_packLevelArbitrationFault_9 "0 - Pack Level Arbitration fault clear (default)
1 - Pack Level Arbitration fault";
CM_ SG_ 2572156937 BATT_multiIgnLoFault_9 "0 - Single module has IGN_LO connection (default)
1 - Multimodule have IGN_LO connections";
CM_ SG_ 2572156937 BATT_modThermistorShorted_9 "0 - module thermistor okay (default)
1 - module thermistor shorted";
CM_ SG_ 2572156937 BATT_modThermistorOpenWire_9 "0 - module thermistor okay (default)
1 - module thermistor open wire";
CM_ SG_ 2572156937 BATT_chargeNotNeeded_9 "0 - Local module charge needed (default)
1 - Local module charge not needed";
CM_ SG_ 2572156937 BATT_packModTempImbalance_9 "0 - Battery pack module temperatures okay (default)
1 - Battery pack module temperature imblance present";
CM_ SG_ 2572156937 BATT_packModCurrImbalance_9 "0 - Battery pack module curent okay (default)
1 - Battery pack module current imblance present";
CM_ SG_ 2572156937 BATT_flashBootCRCError_9 "0 - No flash bootloader CRC error (default)
1 - Flash bootloader CRC error";
CM_ SG_ 2572156937 BATT_flashAppCRCError_9 "0 - No flash app CRC error (default)
1 -  Flash App CRC error";
CM_ SG_ 2572156937 BATT_cellOpenWire_9 "0 - Reset reason okay (default)
1 - Abnormal reset reason";
CM_ BO_ 2572156938 "Message with flags from event matrix";
CM_ SG_ 2572156938 BATT_harnessImpedanceFault_10 "Harness Impedance fault
";
CM_ SG_ 2572156938 BATT_packLevelArbitrationFault_10 "0 - Pack Level Arbitration fault clear (default)
1 - Pack Level Arbitration fault";
CM_ SG_ 2572156938 BATT_multiIgnLoFault_10 "0 - Single module has IGN_LO connection (default)
1 - Multimodule have IGN_LO connections";
CM_ SG_ 2572156938 BATT_modThermistorShorted_10 "0 - module thermistor okay (default)
1 - module thermistor shorted";
CM_ SG_ 2572156938 BATT_modThermistorOpenWire_10 "0 - module thermistor okay (default)
1 - module thermistor open wire";
CM_ SG_ 2572156938 BATT_chargeNotNeeded_10 "0 - Local module charge needed (default)
1 - Local module charge not needed";
CM_ SG_ 2572156938 BATT_packModTempImbalance_10 "0 - Battery pack module temperatures okay (default)
1 - Battery pack module temperature imblance present";
CM_ SG_ 2572156938 BATT_packModCurrImbalance_10 "0 - Battery pack module curent okay (default)
1 - Battery pack module current imblance present";
CM_ SG_ 2572156938 BATT_flashBootCRCError_10 "0 - No flash bootloader CRC error (default)
1 - Flash bootloader CRC error";
CM_ SG_ 2572156938 BATT_flashAppCRCError_10 "0 - No flash app CRC error (default)
1 -  Flash App CRC error";
CM_ SG_ 2572156938 BATT_cellOpenWire_10 "0 - Reset reason okay (default)
1 - Abnormal reset reason";
CM_ BO_ 2572156939 "Message with flags from event matrix";
CM_ SG_ 2572156939 BATT_harnessImpedanceFault_11 "Harness Impedance fault
";
CM_ SG_ 2572156939 BATT_packLevelArbitrationFault_11 "0 - Pack Level Arbitration fault clear (default)
1 - Pack Level Arbitration fault";
CM_ SG_ 2572156939 BATT_multiIgnLoFault_11 "0 - Single module has IGN_LO connection (default)
1 - Multimodule have IGN_LO connections";
CM_ SG_ 2572156939 BATT_modThermistorShorted_11 "0 - module thermistor okay (default)
1 - module thermistor shorted";
CM_ SG_ 2572156939 BATT_modThermistorOpenWire_11 "0 - module thermistor okay (default)
1 - module thermistor open wire";
CM_ SG_ 2572156939 BATT_chargeNotNeeded_11 "0 - Local module charge needed (default)
1 - Local module charge not needed";
CM_ SG_ 2572156939 BATT_packModTempImbalance_11 "0 - Battery pack module temperatures okay (default)
1 - Battery pack module temperature imblance present";
CM_ SG_ 2572156939 BATT_packModCurrImbalance_11 "0 - Battery pack module curent okay (default)
1 - Battery pack module current imblance present";
CM_ SG_ 2572156939 BATT_flashBootCRCError_11 "0 - No flash bootloader CRC error (default)
1 - Flash bootloader CRC error";
CM_ SG_ 2572156939 BATT_flashAppCRCError_11 "0 - No flash app CRC error (default)
1 -  Flash App CRC error";
CM_ SG_ 2572156939 BATT_cellOpenWire_11 "0 - Reset reason okay (default)
1 - Abnormal reset reason";
CM_ SG_ 2617245696 BATT_totalRunTime_0 "Total time FETs have been closed measured in seconds";
CM_ SG_ 2617245697 BATT_totalRunTime_1 "Total time FETs have been closed measured in seconds";
CM_ SG_ 2617245698 BATT_totalRunTime_2 "Total time FETs have been closed measured in seconds";
CM_ SG_ 2617245699 BATT_totalRunTime_3 "Total time FETs have been closed measured in seconds";
CM_ SG_ 2617245700 BATT_totalRunTime_4 "Total time FETs have been closed measured in seconds";
CM_ SG_ 2617245701 BATT_totalRunTime_5 "Total time FETs have been closed measured in seconds";
CM_ SG_ 2617245702 BATT_totalRunTime_6 "Total time FETs have been closed measured in seconds";
CM_ SG_ 2617245703 BATT_totalRunTime_7 "Total time FETs have been closed measured in seconds";
CM_ SG_ 2617245704 BATT_totalRunTime_8 "Total time FETs have been closed measured in seconds";
CM_ SG_ 2617245705 BATT_totalRunTime_9 "Total time FETs have been closed measured in seconds";
CM_ SG_ 2617245706 BATT_totalRunTime_10 "Total time FETs have been closed measured in seconds";
CM_ SG_ 2617245707 BATT_totalRunTime_11 "Total time FETs have been closed measured in seconds";
CM_ BO_ 2618556416 "Diagnostic CHG FET";
CM_ SG_ 2618556416 BATT_fetChgDiagState_0 "CHG FETs diagnostic state";
CM_ SG_ 2618556416 BATT_fetChgDiagIMeas_0 "CHG FETs diagnostic current measurement";
CM_ SG_ 2618556416 BATT_fetChgDiagVMeasPrime_0 "CHG FETs diagnostic voltage prime measurement";
CM_ SG_ 2618556416 BATT_fetChgDiagVMeas_0 "CHG FETs diagnostic voltage measurement";
CM_ SG_ 2618556416 BATT_fetChgDiagOpenResult_0 "CHG FETs diagnostic open check result";
CM_ SG_ 2618556416 BATT_fetChgDiagClosedResult_0 "CHG FETs diagnostic closed check result";
CM_ BO_ 2618556417 "Diagnostic CHG FET";
CM_ SG_ 2618556417 BATT_fetChgDiagState_1 "CHG FETs diagnostic state";
CM_ SG_ 2618556417 BATT_fetChgDiagIMeas_1 "CHG FETs diagnostic current measurement";
CM_ SG_ 2618556417 BATT_fetChgDiagVMeasPrime_1 "CHG FETs diagnostic voltage prime measurement";
CM_ SG_ 2618556417 BATT_fetChgDiagVMeas_1 "CHG FETs diagnostic voltage measurement";
CM_ SG_ 2618556417 BATT_fetChgDiagOpenResult_1 "CHG FETs diagnostic open check result";
CM_ SG_ 2618556417 BATT_fetChgDiagClosedResult_1 "CHG FETs diagnostic closed check result";
CM_ BO_ 2618556418 "Diagnostic CHG FET";
CM_ SG_ 2618556418 BATT_fetChgDiagState_2 "CHG FETs diagnostic state";
CM_ SG_ 2618556418 BATT_fetChgDiagIMeas_2 "CHG FETs diagnostic current measurement";
CM_ SG_ 2618556418 BATT_fetChgDiagVMeasPrime_2 "CHG FETs diagnostic voltage prime measurement";
CM_ SG_ 2618556418 BATT_fetChgDiagVMeas_2 "CHG FETs diagnostic voltage measurement";
CM_ SG_ 2618556418 BATT_fetChgDiagOpenResult_2 "CHG FETs diagnostic open check result";
CM_ SG_ 2618556418 BATT_fetChgDiagClosedResult_2 "CHG FETs diagnostic closed check result";
CM_ BO_ 2618556419 "Diagnostic CHG FET";
CM_ SG_ 2618556419 BATT_fetChgDiagState_3 "CHG FETs diagnostic state";
CM_ SG_ 2618556419 BATT_fetChgDiagIMeas_3 "CHG FETs diagnostic current measurement";
CM_ SG_ 2618556419 BATT_fetChgDiagVMeasPrime_3 "CHG FETs diagnostic voltage prime measurement";
CM_ SG_ 2618556419 BATT_fetChgDiagVMeas_3 "CHG FETs diagnostic voltage measurement";
CM_ SG_ 2618556419 BATT_fetChgDiagOpenResult_3 "CHG FETs diagnostic open check result";
CM_ SG_ 2618556419 BATT_fetChgDiagClosedResult_3 "CHG FETs diagnostic closed check result";
CM_ BO_ 2618556420 "Diagnostic CHG FET";
CM_ SG_ 2618556420 BATT_fetChgDiagState_4 "CHG FETs diagnostic state";
CM_ SG_ 2618556420 BATT_fetChgDiagIMeas_4 "CHG FETs diagnostic current measurement";
CM_ SG_ 2618556420 BATT_fetChgDiagVMeasPrime_4 "CHG FETs diagnostic voltage prime measurement";
CM_ SG_ 2618556420 BATT_fetChgDiagVMeas_4 "CHG FETs diagnostic voltage measurement";
CM_ SG_ 2618556420 BATT_fetChgDiagOpenResult_4 "CHG FETs diagnostic open check result";
CM_ SG_ 2618556420 BATT_fetChgDiagClosedResult_4 "CHG FETs diagnostic closed check result";
CM_ BO_ 2618556421 "Diagnostic CHG FET";
CM_ SG_ 2618556421 BATT_fetChgDiagState_5 "CHG FETs diagnostic state";
CM_ SG_ 2618556421 BATT_fetChgDiagIMeas_5 "CHG FETs diagnostic current measurement";
CM_ SG_ 2618556421 BATT_fetChgDiagVMeasPrime_5 "CHG FETs diagnostic voltage prime measurement";
CM_ SG_ 2618556421 BATT_fetChgDiagVMeas_5 "CHG FETs diagnostic voltage measurement";
CM_ SG_ 2618556421 BATT_fetChgDiagOpenResult_5 "CHG FETs diagnostic open check result";
CM_ SG_ 2618556421 BATT_fetChgDiagClosedResult_5 "CHG FETs diagnostic closed check result";
CM_ BO_ 2618556422 "Diagnostic CHG FET";
CM_ SG_ 2618556422 BATT_fetChgDiagState_6 "CHG FETs diagnostic state";
CM_ SG_ 2618556422 BATT_fetChgDiagIMeas_6 "CHG FETs diagnostic current measurement";
CM_ SG_ 2618556422 BATT_fetChgDiagVMeasPrime_6 "CHG FETs diagnostic voltage prime measurement";
CM_ SG_ 2618556422 BATT_fetChgDiagVMeas_6 "CHG FETs diagnostic voltage measurement";
CM_ SG_ 2618556422 BATT_fetChgDiagOpenResult_6 "CHG FETs diagnostic open check result";
CM_ SG_ 2618556422 BATT_fetChgDiagClosedResult_6 "CHG FETs diagnostic closed check result";
CM_ BO_ 2618556423 "Diagnostic CHG FET";
CM_ SG_ 2618556423 BATT_fetChgDiagState_7 "CHG FETs diagnostic state";
CM_ SG_ 2618556423 BATT_fetChgDiagIMeas_7 "CHG FETs diagnostic current measurement";
CM_ SG_ 2618556423 BATT_fetChgDiagVMeasPrime_7 "CHG FETs diagnostic voltage prime measurement";
CM_ SG_ 2618556423 BATT_fetChgDiagVMeas_7 "CHG FETs diagnostic voltage measurement";
CM_ SG_ 2618556423 BATT_fetChgDiagOpenResult_7 "CHG FETs diagnostic open check result";
CM_ SG_ 2618556423 BATT_fetChgDiagClosedResult_7 "CHG FETs diagnostic closed check result";
CM_ BO_ 2618556424 "Diagnostic CHG FET";
CM_ SG_ 2618556424 BATT_fetChgDiagState_8 "CHG FETs diagnostic state";
CM_ SG_ 2618556424 BATT_fetChgDiagIMeas_8 "CHG FETs diagnostic current measurement";
CM_ SG_ 2618556424 BATT_fetChgDiagVMeasPrime_8 "CHG FETs diagnostic voltage prime measurement";
CM_ SG_ 2618556424 BATT_fetChgDiagVMeas_8 "CHG FETs diagnostic voltage measurement";
CM_ SG_ 2618556424 BATT_fetChgDiagOpenResult_8 "CHG FETs diagnostic open check result";
CM_ SG_ 2618556424 BATT_fetChgDiagClosedResult_8 "CHG FETs diagnostic closed check result";
CM_ BO_ 2618556425 "Diagnostic CHG FET";
CM_ SG_ 2618556425 BATT_fetChgDiagState_9 "CHG FETs diagnostic state";
CM_ SG_ 2618556425 BATT_fetChgDiagIMeas_9 "CHG FETs diagnostic current measurement";
CM_ SG_ 2618556425 BATT_fetChgDiagVMeasPrime_9 "CHG FETs diagnostic voltage prime measurement";
CM_ SG_ 2618556425 BATT_fetChgDiagVMeas_9 "CHG FETs diagnostic voltage measurement";
CM_ SG_ 2618556425 BATT_fetChgDiagOpenResult_9 "CHG FETs diagnostic open check result";
CM_ SG_ 2618556425 BATT_fetChgDiagClosedResult_9 "CHG FETs diagnostic closed check result";
CM_ BO_ 2618556426 "Diagnostic CHG FET";
CM_ SG_ 2618556426 BATT_fetChgDiagState_10 "CHG FETs diagnostic state";
CM_ SG_ 2618556426 BATT_fetChgDiagIMeas_10 "CHG FETs diagnostic current measurement";
CM_ SG_ 2618556426 BATT_fetChgDiagVMeasPrime_10 "CHG FETs diagnostic voltage prime measurement";
CM_ SG_ 2618556426 BATT_fetChgDiagVMeas_10 "CHG FETs diagnostic voltage measurement";
CM_ SG_ 2618556426 BATT_fetChgDiagOpenResult_10 "CHG FETs diagnostic open check result";
CM_ SG_ 2618556426 BATT_fetChgDiagClosedResult_10 "CHG FETs diagnostic closed check result";
CM_ BO_ 2618556427 "Diagnostic CHG FET";
CM_ SG_ 2618556427 BATT_fetChgDiagState_11 "CHG FETs diagnostic state";
CM_ SG_ 2618556427 BATT_fetChgDiagIMeas_11 "CHG FETs diagnostic current measurement";
CM_ SG_ 2618556427 BATT_fetChgDiagVMeasPrime_11 "CHG FETs diagnostic voltage prime measurement";
CM_ SG_ 2618556427 BATT_fetChgDiagVMeas_11 "CHG FETs diagnostic voltage measurement";
CM_ SG_ 2618556427 BATT_fetChgDiagOpenResult_11 "CHG FETs diagnostic open check result";
CM_ SG_ 2618556427 BATT_fetChgDiagClosedResult_11 "CHG FETs diagnostic closed check result";
CM_ BO_ 2618818560 "Diagnostic DSG FET";
CM_ SG_ 2618818560 BATT_fetDsgDiagState_0 "DSG FETs diagnostic state";
CM_ SG_ 2618818560 BATT_fetDsgDiagVMeas_0 "DSG FETs diagnostic voltage measurement";
CM_ SG_ 2618818560 BATT_fetDsgDiagVMeasPrime_0 "DSG FETs diagnostic voltage prime measurement";
CM_ SG_ 2618818560 BATT_fetDsgDiagOpenResult_0 "DSG FETs diagnostic open check result";
CM_ SG_ 2618818560 BATT_fetDsgDiagClosedResult_0 "DSG FETs diagnostic closed check result";
CM_ BO_ 2618818561 "Diagnostic DSG FET";
CM_ SG_ 2618818561 BATT_fetDsgDiagState_1 "DSG FETs diagnostic state";
CM_ SG_ 2618818561 BATT_fetDsgDiagVMeas_1 "DSG FETs diagnostic voltage measurement";
CM_ SG_ 2618818561 BATT_fetDsgDiagVMeasPrime_1 "DSG FETs diagnostic voltage prime measurement";
CM_ SG_ 2618818561 BATT_fetDsgDiagOpenResult_1 "DSG FETs diagnostic open check result";
CM_ SG_ 2618818561 BATT_fetDsgDiagClosedResult_1 "DSG FETs diagnostic closed check result";
CM_ BO_ 2618818562 "Diagnostic DSG FET";
CM_ SG_ 2618818562 BATT_fetDsgDiagState_2 "DSG FETs diagnostic state";
CM_ SG_ 2618818562 BATT_fetDsgDiagVMeas_2 "DSG FETs diagnostic voltage measurement";
CM_ SG_ 2618818562 BATT_fetDsgDiagVMeasPrime_2 "DSG FETs diagnostic voltage prime measurement";
CM_ SG_ 2618818562 BATT_fetDsgDiagOpenResult_2 "DSG FETs diagnostic open check result";
CM_ SG_ 2618818562 BATT_fetDsgDiagClosedResult_2 "DSG FETs diagnostic closed check result";
CM_ BO_ 2618818563 "Diagnostic DSG FET";
CM_ SG_ 2618818563 BATT_fetDsgDiagState_3 "DSG FETs diagnostic state";
CM_ SG_ 2618818563 BATT_fetDsgDiagVMeas_3 "DSG FETs diagnostic voltage measurement";
CM_ SG_ 2618818563 BATT_fetDsgDiagVMeasPrime_3 "DSG FETs diagnostic voltage prime measurement";
CM_ SG_ 2618818563 BATT_fetDsgDiagOpenResult_3 "DSG FETs diagnostic open check result";
CM_ SG_ 2618818563 BATT_fetDsgDiagClosedResult_3 "DSG FETs diagnostic closed check result";
CM_ BO_ 2618818564 "Diagnostic DSG FET";
CM_ SG_ 2618818564 BATT_fetDsgDiagState_4 "DSG FETs diagnostic state";
CM_ SG_ 2618818564 BATT_fetDsgDiagVMeas_4 "DSG FETs diagnostic voltage measurement";
CM_ SG_ 2618818564 BATT_fetDsgDiagVMeasPrime_4 "DSG FETs diagnostic voltage prime measurement";
CM_ SG_ 2618818564 BATT_fetDsgDiagOpenResult_4 "DSG FETs diagnostic open check result";
CM_ SG_ 2618818564 BATT_fetDsgDiagClosedResult_4 "DSG FETs diagnostic closed check result";
CM_ BO_ 2618818565 "Diagnostic DSG FET";
CM_ SG_ 2618818565 BATT_fetDsgDiagState_5 "DSG FETs diagnostic state";
CM_ SG_ 2618818565 BATT_fetDsgDiagVMeas_5 "DSG FETs diagnostic voltage measurement";
CM_ SG_ 2618818565 BATT_fetDsgDiagVMeasPrime_5 "DSG FETs diagnostic voltage prime measurement";
CM_ SG_ 2618818565 BATT_fetDsgDiagOpenResult_5 "DSG FETs diagnostic open check result";
CM_ SG_ 2618818565 BATT_fetDsgDiagClosedResult_5 "DSG FETs diagnostic closed check result";
CM_ BO_ 2618818566 "Diagnostic DSG FET";
CM_ SG_ 2618818566 BATT_fetDsgDiagState_6 "DSG FETs diagnostic state";
CM_ SG_ 2618818566 BATT_fetDsgDiagVMeas_6 "DSG FETs diagnostic voltage measurement";
CM_ SG_ 2618818566 BATT_fetDsgDiagVMeasPrime_6 "DSG FETs diagnostic voltage prime measurement";
CM_ SG_ 2618818566 BATT_fetDsgDiagOpenResult_6 "DSG FETs diagnostic open check result";
CM_ SG_ 2618818566 BATT_fetDsgDiagClosedResult_6 "DSG FETs diagnostic closed check result";
CM_ BO_ 2618818567 "Diagnostic DSG FET";
CM_ SG_ 2618818567 BATT_fetDsgDiagState_7 "DSG FETs diagnostic state";
CM_ SG_ 2618818567 BATT_fetDsgDiagVMeas_7 "DSG FETs diagnostic voltage measurement";
CM_ SG_ 2618818567 BATT_fetDsgDiagVMeasPrime_7 "DSG FETs diagnostic voltage prime measurement";
CM_ SG_ 2618818567 BATT_fetDsgDiagOpenResult_7 "DSG FETs diagnostic open check result";
CM_ SG_ 2618818567 BATT_fetDsgDiagClosedResult_7 "DSG FETs diagnostic closed check result";
CM_ BO_ 2618818568 "Diagnostic DSG FET";
CM_ SG_ 2618818568 BATT_fetDsgDiagState_8 "DSG FETs diagnostic state";
CM_ SG_ 2618818568 BATT_fetDsgDiagVMeas_8 "DSG FETs diagnostic voltage measurement";
CM_ SG_ 2618818568 BATT_fetDsgDiagVMeasPrime_8 "DSG FETs diagnostic voltage prime measurement";
CM_ SG_ 2618818568 BATT_fetDsgDiagOpenResult_8 "DSG FETs diagnostic open check result";
CM_ SG_ 2618818568 BATT_fetDsgDiagClosedResult_8 "DSG FETs diagnostic closed check result";
CM_ BO_ 2618818569 "Diagnostic DSG FET";
CM_ SG_ 2618818569 BATT_fetDsgDiagState_9 "DSG FETs diagnostic state";
CM_ SG_ 2618818569 BATT_fetDsgDiagVMeas_9 "DSG FETs diagnostic voltage measurement";
CM_ SG_ 2618818569 BATT_fetDsgDiagVMeasPrime_9 "DSG FETs diagnostic voltage prime measurement";
CM_ SG_ 2618818569 BATT_fetDsgDiagOpenResult_9 "DSG FETs diagnostic open check result";
CM_ SG_ 2618818569 BATT_fetDsgDiagClosedResult_9 "DSG FETs diagnostic closed check result";
CM_ BO_ 2618818570 "Diagnostic DSG FET";
CM_ SG_ 2618818570 BATT_fetDsgDiagState_10 "DSG FETs diagnostic state";
CM_ SG_ 2618818570 BATT_fetDsgDiagVMeas_10 "DSG FETs diagnostic voltage measurement";
CM_ SG_ 2618818570 BATT_fetDsgDiagVMeasPrime_10 "DSG FETs diagnostic voltage prime measurement";
CM_ SG_ 2618818570 BATT_fetDsgDiagOpenResult_10 "DSG FETs diagnostic open check result";
CM_ SG_ 2618818570 BATT_fetDsgDiagClosedResult_10 "DSG FETs diagnostic closed check result";
CM_ BO_ 2618818571 "Diagnostic DSG FET";
CM_ SG_ 2618818571 BATT_fetDsgDiagState_11 "DSG FETs diagnostic state";
CM_ SG_ 2618818571 BATT_fetDsgDiagVMeas_11 "DSG FETs diagnostic voltage measurement";
CM_ SG_ 2618818571 BATT_fetDsgDiagVMeasPrime_11 "DSG FETs diagnostic voltage prime measurement";
CM_ SG_ 2618818571 BATT_fetDsgDiagOpenResult_11 "DSG FETs diagnostic open check result";
CM_ SG_ 2618818571 BATT_fetDsgDiagClosedResult_11 "DSG FETs diagnostic closed check result";
CM_ BO_ 2619080704 "Impedance of bricks 1-4";
CM_ SG_ 2619080704 BATT_resBrick04_0 "Impedance of brick 4";
CM_ SG_ 2619080704 BATT_resBrick03_0 "Impedance of brick 3";
CM_ SG_ 2619080704 BATT_resBrick02_0 "Impedance of brick 2";
CM_ SG_ 2619080704 BATT_resBrick01_0 "Impedance of brick 1";
CM_ BO_ 2619080705 "Impedance of bricks 1-4";
CM_ SG_ 2619080705 BATT_resBrick04_1 "Impedance of brick 4";
CM_ SG_ 2619080705 BATT_resBrick03_1 "Impedance of brick 3";
CM_ SG_ 2619080705 BATT_resBrick02_1 "Impedance of brick 2";
CM_ SG_ 2619080705 BATT_resBrick01_1 "Impedance of brick 1";
CM_ BO_ 2619080706 "Impedance of bricks 1-4";
CM_ SG_ 2619080706 BATT_resBrick04_2 "Impedance of brick 4";
CM_ SG_ 2619080706 BATT_resBrick03_2 "Impedance of brick 3";
CM_ SG_ 2619080706 BATT_resBrick02_2 "Impedance of brick 2";
CM_ SG_ 2619080706 BATT_resBrick01_2 "Impedance of brick 1";
CM_ BO_ 2619080707 "Impedance of bricks 1-4";
CM_ SG_ 2619080707 BATT_resBrick04_3 "Impedance of brick 4";
CM_ SG_ 2619080707 BATT_resBrick03_3 "Impedance of brick 3";
CM_ SG_ 2619080707 BATT_resBrick02_3 "Impedance of brick 2";
CM_ SG_ 2619080707 BATT_resBrick01_3 "Impedance of brick 1";
CM_ BO_ 2619080708 "Impedance of bricks 1-4";
CM_ SG_ 2619080708 BATT_resBrick04_4 "Impedance of brick 4";
CM_ SG_ 2619080708 BATT_resBrick03_4 "Impedance of brick 3";
CM_ SG_ 2619080708 BATT_resBrick02_4 "Impedance of brick 2";
CM_ SG_ 2619080708 BATT_resBrick01_4 "Impedance of brick 1";
CM_ BO_ 2619080709 "Impedance of bricks 1-4";
CM_ SG_ 2619080709 BATT_resBrick04_5 "Impedance of brick 4";
CM_ SG_ 2619080709 BATT_resBrick03_5 "Impedance of brick 3";
CM_ SG_ 2619080709 BATT_resBrick02_5 "Impedance of brick 2";
CM_ SG_ 2619080709 BATT_resBrick01_5 "Impedance of brick 1";
CM_ BO_ 2619080710 "Impedance of bricks 1-4";
CM_ SG_ 2619080710 BATT_resBrick04_6 "Impedance of brick 4";
CM_ SG_ 2619080710 BATT_resBrick03_6 "Impedance of brick 3";
CM_ SG_ 2619080710 BATT_resBrick02_6 "Impedance of brick 2";
CM_ SG_ 2619080710 BATT_resBrick01_6 "Impedance of brick 1";
CM_ BO_ 2619080711 "Impedance of bricks 1-4";
CM_ SG_ 2619080711 BATT_resBrick04_7 "Impedance of brick 4";
CM_ SG_ 2619080711 BATT_resBrick03_7 "Impedance of brick 3";
CM_ SG_ 2619080711 BATT_resBrick02_7 "Impedance of brick 2";
CM_ SG_ 2619080711 BATT_resBrick01_7 "Impedance of brick 1";
CM_ BO_ 2619080712 "Impedance of bricks 1-4";
CM_ SG_ 2619080712 BATT_resBrick04_8 "Impedance of brick 4";
CM_ SG_ 2619080712 BATT_resBrick03_8 "Impedance of brick 3";
CM_ SG_ 2619080712 BATT_resBrick02_8 "Impedance of brick 2";
CM_ SG_ 2619080712 BATT_resBrick01_8 "Impedance of brick 1";
CM_ BO_ 2619080713 "Impedance of bricks 1-4";
CM_ SG_ 2619080713 BATT_resBrick04_9 "Impedance of brick 4";
CM_ SG_ 2619080713 BATT_resBrick03_9 "Impedance of brick 3";
CM_ SG_ 2619080713 BATT_resBrick02_9 "Impedance of brick 2";
CM_ SG_ 2619080713 BATT_resBrick01_9 "Impedance of brick 1";
CM_ BO_ 2619080714 "Impedance of bricks 1-4";
CM_ SG_ 2619080714 BATT_resBrick04_10 "Impedance of brick 4";
CM_ SG_ 2619080714 BATT_resBrick03_10 "Impedance of brick 3";
CM_ SG_ 2619080714 BATT_resBrick02_10 "Impedance of brick 2";
CM_ SG_ 2619080714 BATT_resBrick01_10 "Impedance of brick 1";
CM_ BO_ 2619080715 "Impedance of bricks 1-4";
CM_ SG_ 2619080715 BATT_resBrick04_11 "Impedance of brick 4";
CM_ SG_ 2619080715 BATT_resBrick03_11 "Impedance of brick 3";
CM_ SG_ 2619080715 BATT_resBrick02_11 "Impedance of brick 2";
CM_ SG_ 2619080715 BATT_resBrick01_11 "Impedance of brick 1";
CM_ BO_ 2619342848 "Impedance of bricks 5-8";
CM_ SG_ 2619342848 BATT_resBrick08_0 "Impedance of brick 8";
CM_ SG_ 2619342848 BATT_resBrick07_0 "Impedance of brick 7";
CM_ SG_ 2619342848 BATT_resBrick06_0 "Impedance of brick 6";
CM_ SG_ 2619342848 BATT_resBrick05_0 "Impedance of brick 5";
CM_ BO_ 2619342849 "Impedance of bricks 5-8";
CM_ SG_ 2619342849 BATT_resBrick08_1 "Impedance of brick 8";
CM_ SG_ 2619342849 BATT_resBrick07_1 "Impedance of brick 7";
CM_ SG_ 2619342849 BATT_resBrick06_1 "Impedance of brick 6";
CM_ SG_ 2619342849 BATT_resBrick05_1 "Impedance of brick 5";
CM_ BO_ 2619342850 "Impedance of bricks 5-8";
CM_ SG_ 2619342850 BATT_resBrick08_2 "Impedance of brick 8";
CM_ SG_ 2619342850 BATT_resBrick07_2 "Impedance of brick 7";
CM_ SG_ 2619342850 BATT_resBrick06_2 "Impedance of brick 6";
CM_ SG_ 2619342850 BATT_resBrick05_2 "Impedance of brick 5";
CM_ BO_ 2619342851 "Impedance of bricks 5-8";
CM_ SG_ 2619342851 BATT_resBrick08_3 "Impedance of brick 8";
CM_ SG_ 2619342851 BATT_resBrick07_3 "Impedance of brick 7";
CM_ SG_ 2619342851 BATT_resBrick06_3 "Impedance of brick 6";
CM_ SG_ 2619342851 BATT_resBrick05_3 "Impedance of brick 5";
CM_ BO_ 2619342852 "Impedance of bricks 5-8";
CM_ SG_ 2619342852 BATT_resBrick08_4 "Impedance of brick 8";
CM_ SG_ 2619342852 BATT_resBrick07_4 "Impedance of brick 7";
CM_ SG_ 2619342852 BATT_resBrick06_4 "Impedance of brick 6";
CM_ SG_ 2619342852 BATT_resBrick05_4 "Impedance of brick 5";
CM_ BO_ 2619342853 "Impedance of bricks 5-8";
CM_ SG_ 2619342853 BATT_resBrick08_5 "Impedance of brick 8";
CM_ SG_ 2619342853 BATT_resBrick07_5 "Impedance of brick 7";
CM_ SG_ 2619342853 BATT_resBrick06_5 "Impedance of brick 6";
CM_ SG_ 2619342853 BATT_resBrick05_5 "Impedance of brick 5";
CM_ BO_ 2619342854 "Impedance of bricks 5-8";
CM_ SG_ 2619342854 BATT_resBrick08_6 "Impedance of brick 8";
CM_ SG_ 2619342854 BATT_resBrick07_6 "Impedance of brick 7";
CM_ SG_ 2619342854 BATT_resBrick06_6 "Impedance of brick 6";
CM_ SG_ 2619342854 BATT_resBrick05_6 "Impedance of brick 5";
CM_ BO_ 2619342855 "Impedance of bricks 5-8";
CM_ SG_ 2619342855 BATT_resBrick08_7 "Impedance of brick 8";
CM_ SG_ 2619342855 BATT_resBrick07_7 "Impedance of brick 7";
CM_ SG_ 2619342855 BATT_resBrick06_7 "Impedance of brick 6";
CM_ SG_ 2619342855 BATT_resBrick05_7 "Impedance of brick 5";
CM_ BO_ 2619342856 "Impedance of bricks 5-8";
CM_ SG_ 2619342856 BATT_resBrick08_8 "Impedance of brick 8";
CM_ SG_ 2619342856 BATT_resBrick07_8 "Impedance of brick 7";
CM_ SG_ 2619342856 BATT_resBrick06_8 "Impedance of brick 6";
CM_ SG_ 2619342856 BATT_resBrick05_8 "Impedance of brick 5";
CM_ BO_ 2619342857 "Impedance of bricks 5-8";
CM_ SG_ 2619342857 BATT_resBrick08_9 "Impedance of brick 8";
CM_ SG_ 2619342857 BATT_resBrick07_9 "Impedance of brick 7";
CM_ SG_ 2619342857 BATT_resBrick06_9 "Impedance of brick 6";
CM_ SG_ 2619342857 BATT_resBrick05_9 "Impedance of brick 5";
CM_ BO_ 2619342858 "Impedance of bricks 5-8";
CM_ SG_ 2619342858 BATT_resBrick08_10 "Impedance of brick 8";
CM_ SG_ 2619342858 BATT_resBrick07_10 "Impedance of brick 7";
CM_ SG_ 2619342858 BATT_resBrick06_10 "Impedance of brick 6";
CM_ SG_ 2619342858 BATT_resBrick05_10 "Impedance of brick 5";
CM_ BO_ 2619342859 "Impedance of bricks 5-8";
CM_ SG_ 2619342859 BATT_resBrick08_11 "Impedance of brick 8";
CM_ SG_ 2619342859 BATT_resBrick07_11 "Impedance of brick 7";
CM_ SG_ 2619342859 BATT_resBrick06_11 "Impedance of brick 6";
CM_ SG_ 2619342859 BATT_resBrick05_11 "Impedance of brick 5";
CM_ BO_ 2619604992 "Impedance of bricks 9-12";
CM_ SG_ 2619604992 BATT_resBrick12_0 "Impedance of brick 12";
CM_ SG_ 2619604992 BATT_resBrick11_0 "Impedance of brick 11";
CM_ SG_ 2619604992 BATT_resBrick09_0 "Impedance of brick 9";
CM_ SG_ 2619604992 BATT_resBrick10_0 "Impedance of brick 10";
CM_ BO_ 2619604993 "Impedance of bricks 9-12";
CM_ SG_ 2619604993 BATT_resBrick12_1 "Impedance of brick 12";
CM_ SG_ 2619604993 BATT_resBrick11_1 "Impedance of brick 11";
CM_ SG_ 2619604993 BATT_resBrick09_1 "Impedance of brick 9";
CM_ SG_ 2619604993 BATT_resBrick10_1 "Impedance of brick 10";
CM_ BO_ 2619604994 "Impedance of bricks 9-12";
CM_ SG_ 2619604994 BATT_resBrick12_2 "Impedance of brick 12";
CM_ SG_ 2619604994 BATT_resBrick11_2 "Impedance of brick 11";
CM_ SG_ 2619604994 BATT_resBrick09_2 "Impedance of brick 9";
CM_ SG_ 2619604994 BATT_resBrick10_2 "Impedance of brick 10";
CM_ BO_ 2619604995 "Impedance of bricks 9-12";
CM_ SG_ 2619604995 BATT_resBrick12_3 "Impedance of brick 12";
CM_ SG_ 2619604995 BATT_resBrick11_3 "Impedance of brick 11";
CM_ SG_ 2619604995 BATT_resBrick09_3 "Impedance of brick 9";
CM_ SG_ 2619604995 BATT_resBrick10_3 "Impedance of brick 10";
CM_ BO_ 2619604996 "Impedance of bricks 9-12";
CM_ SG_ 2619604996 BATT_resBrick12_4 "Impedance of brick 12";
CM_ SG_ 2619604996 BATT_resBrick11_4 "Impedance of brick 11";
CM_ SG_ 2619604996 BATT_resBrick09_4 "Impedance of brick 9";
CM_ SG_ 2619604996 BATT_resBrick10_4 "Impedance of brick 10";
CM_ BO_ 2619604997 "Impedance of bricks 9-12";
CM_ SG_ 2619604997 BATT_resBrick12_5 "Impedance of brick 12";
CM_ SG_ 2619604997 BATT_resBrick11_5 "Impedance of brick 11";
CM_ SG_ 2619604997 BATT_resBrick09_5 "Impedance of brick 9";
CM_ SG_ 2619604997 BATT_resBrick10_5 "Impedance of brick 10";
CM_ BO_ 2619604998 "Impedance of bricks 9-12";
CM_ SG_ 2619604998 BATT_resBrick12_6 "Impedance of brick 12";
CM_ SG_ 2619604998 BATT_resBrick11_6 "Impedance of brick 11";
CM_ SG_ 2619604998 BATT_resBrick09_6 "Impedance of brick 9";
CM_ SG_ 2619604998 BATT_resBrick10_6 "Impedance of brick 10";
CM_ BO_ 2619604999 "Impedance of bricks 9-12";
CM_ SG_ 2619604999 BATT_resBrick12_7 "Impedance of brick 12";
CM_ SG_ 2619604999 BATT_resBrick11_7 "Impedance of brick 11";
CM_ SG_ 2619604999 BATT_resBrick09_7 "Impedance of brick 9";
CM_ SG_ 2619604999 BATT_resBrick10_7 "Impedance of brick 10";
CM_ BO_ 2619605000 "Impedance of bricks 9-12";
CM_ SG_ 2619605000 BATT_resBrick12_8 "Impedance of brick 12";
CM_ SG_ 2619605000 BATT_resBrick11_8 "Impedance of brick 11";
CM_ SG_ 2619605000 BATT_resBrick09_8 "Impedance of brick 9";
CM_ SG_ 2619605000 BATT_resBrick10_8 "Impedance of brick 10";
CM_ BO_ 2619605001 "Impedance of bricks 9-12";
CM_ SG_ 2619605001 BATT_resBrick12_9 "Impedance of brick 12";
CM_ SG_ 2619605001 BATT_resBrick11_9 "Impedance of brick 11";
CM_ SG_ 2619605001 BATT_resBrick09_9 "Impedance of brick 9";
CM_ SG_ 2619605001 BATT_resBrick10_9 "Impedance of brick 10";
CM_ BO_ 2619605002 "Impedance of bricks 9-12";
CM_ SG_ 2619605002 BATT_resBrick12_10 "Impedance of brick 12";
CM_ SG_ 2619605002 BATT_resBrick11_10 "Impedance of brick 11";
CM_ SG_ 2619605002 BATT_resBrick09_10 "Impedance of brick 9";
CM_ SG_ 2619605002 BATT_resBrick10_10 "Impedance of brick 10";
CM_ BO_ 2619605003 "Impedance of bricks 9-12";
CM_ SG_ 2619605003 BATT_resBrick12_11 "Impedance of brick 12";
CM_ SG_ 2619605003 BATT_resBrick11_11 "Impedance of brick 11";
CM_ SG_ 2619605003 BATT_resBrick09_11 "Impedance of brick 9";
CM_ SG_ 2619605003 BATT_resBrick10_11 "Impedance of brick 10";
CM_ BO_ 2621440000 "Impedance of bricks 13-14";
CM_ SG_ 2621440000 BATT_resBrick14_0 "Impedance of brick 14";
CM_ SG_ 2621440000 BATT_resBrick13_0 "Impedance of brick 13";
CM_ BO_ 2621440001 "Impedance of bricks 13-14";
CM_ SG_ 2621440001 BATT_resBrick14_1 "Impedance of brick 14";
CM_ SG_ 2621440001 BATT_resBrick13_1 "Impedance of brick 13";
CM_ BO_ 2621440002 "Impedance of bricks 13-14";
CM_ SG_ 2621440002 BATT_resBrick14_2 "Impedance of brick 14";
CM_ SG_ 2621440002 BATT_resBrick13_2 "Impedance of brick 13";
CM_ BO_ 2621440003 "Impedance of bricks 13-14";
CM_ SG_ 2621440003 BATT_resBrick14_3 "Impedance of brick 14";
CM_ SG_ 2621440003 BATT_resBrick13_3 "Impedance of brick 13";
CM_ BO_ 2621440004 "Impedance of bricks 13-14";
CM_ SG_ 2621440004 BATT_resBrick14_4 "Impedance of brick 14";
CM_ SG_ 2621440004 BATT_resBrick13_4 "Impedance of brick 13";
CM_ BO_ 2621440005 "Impedance of bricks 13-14";
CM_ SG_ 2621440005 BATT_resBrick14_5 "Impedance of brick 14";
CM_ SG_ 2621440005 BATT_resBrick13_5 "Impedance of brick 13";
CM_ BO_ 2621440006 "Impedance of bricks 13-14";
CM_ SG_ 2621440006 BATT_resBrick14_6 "Impedance of brick 14";
CM_ SG_ 2621440006 BATT_resBrick13_6 "Impedance of brick 13";
CM_ BO_ 2621440007 "Impedance of bricks 13-14";
CM_ SG_ 2621440007 BATT_resBrick14_7 "Impedance of brick 14";
CM_ SG_ 2621440007 BATT_resBrick13_7 "Impedance of brick 13";
CM_ BO_ 2621440008 "Impedance of bricks 13-14";
CM_ SG_ 2621440008 BATT_resBrick14_8 "Impedance of brick 14";
CM_ SG_ 2621440008 BATT_resBrick13_8 "Impedance of brick 13";
CM_ BO_ 2621440009 "Impedance of bricks 13-14";
CM_ SG_ 2621440009 BATT_resBrick14_9 "Impedance of brick 14";
CM_ SG_ 2621440009 BATT_resBrick13_9 "Impedance of brick 13";
CM_ BO_ 2621440010 "Impedance of bricks 13-14";
CM_ SG_ 2621440010 BATT_resBrick14_10 "Impedance of brick 14";
CM_ SG_ 2621440010 BATT_resBrick13_10 "Impedance of brick 13";
CM_ BO_ 2621440011 "Impedance of bricks 13-14";
CM_ SG_ 2621440011 BATT_resBrick14_11 "Impedance of brick 14";
CM_ SG_ 2621440011 BATT_resBrick13_11 "Impedance of brick 13";
CM_ BO_ 2621702144 "Capacity of bricks 1-4";
CM_ SG_ 2621702144 BATT_capBrick04_0 "Capacity of brick 4";
CM_ SG_ 2621702144 BATT_capBrick03_0 "Capacity of brick 3";
CM_ SG_ 2621702144 BATT_capBrick02_0 "Capacity of brick 2";
CM_ SG_ 2621702144 BATT_capBrick01_0 "Capacity of brick 1";
CM_ BO_ 2621702145 "Capacity of bricks 1-4";
CM_ SG_ 2621702145 BATT_capBrick04_1 "Capacity of brick 4";
CM_ SG_ 2621702145 BATT_capBrick03_1 "Capacity of brick 3";
CM_ SG_ 2621702145 BATT_capBrick02_1 "Capacity of brick 2";
CM_ SG_ 2621702145 BATT_capBrick01_1 "Capacity of brick 1";
CM_ BO_ 2621702146 "Capacity of bricks 1-4";
CM_ SG_ 2621702146 BATT_capBrick04_2 "Capacity of brick 4";
CM_ SG_ 2621702146 BATT_capBrick03_2 "Capacity of brick 3";
CM_ SG_ 2621702146 BATT_capBrick02_2 "Capacity of brick 2";
CM_ SG_ 2621702146 BATT_capBrick01_2 "Capacity of brick 1";
CM_ BO_ 2621702147 "Capacity of bricks 1-4";
CM_ SG_ 2621702147 BATT_capBrick04_3 "Capacity of brick 4";
CM_ SG_ 2621702147 BATT_capBrick03_3 "Capacity of brick 3";
CM_ SG_ 2621702147 BATT_capBrick02_3 "Capacity of brick 2";
CM_ SG_ 2621702147 BATT_capBrick01_3 "Capacity of brick 1";
CM_ BO_ 2621702148 "Capacity of bricks 1-4";
CM_ SG_ 2621702148 BATT_capBrick04_4 "Capacity of brick 4";
CM_ SG_ 2621702148 BATT_capBrick03_4 "Capacity of brick 3";
CM_ SG_ 2621702148 BATT_capBrick02_4 "Capacity of brick 2";
CM_ SG_ 2621702148 BATT_capBrick01_4 "Capacity of brick 1";
CM_ BO_ 2621702149 "Capacity of bricks 1-4";
CM_ SG_ 2621702149 BATT_capBrick04_5 "Capacity of brick 4";
CM_ SG_ 2621702149 BATT_capBrick03_5 "Capacity of brick 3";
CM_ SG_ 2621702149 BATT_capBrick02_5 "Capacity of brick 2";
CM_ SG_ 2621702149 BATT_capBrick01_5 "Capacity of brick 1";
CM_ BO_ 2621702150 "Capacity of bricks 1-4";
CM_ SG_ 2621702150 BATT_capBrick04_6 "Capacity of brick 4";
CM_ SG_ 2621702150 BATT_capBrick03_6 "Capacity of brick 3";
CM_ SG_ 2621702150 BATT_capBrick02_6 "Capacity of brick 2";
CM_ SG_ 2621702150 BATT_capBrick01_6 "Capacity of brick 1";

BA_DEF_ BO_  "GenMsgDiag" ENUM "No","Yes";
BA_DEF_ BO_  "GenMsgInstanced" STRING ;
BA_DEF_ SG_  "GenSigType" ENUM "Extended","Diagnostic","Standard","Modified";
BA_DEF_ BO_  "GenMsgCycleTime" INT 0 0;
BA_DEF_ SG_  "GenSigSNA" INT 0 65535;
BA_DEF_ SG_  "Access" ENUM "r","rw";
BA_DEF_DEF_  "GenMsgDiag" "No";
BA_DEF_DEF_  "GenMsgInstanced" "No";
BA_DEF_DEF_  "GenSigType" "Standard";
BA_DEF_DEF_  "GenMsgCycleTime" 0;
BA_DEF_DEF_  "GenSigSNA" 0;
BA_DEF_DEF_  "Access" "r";
BA_ "GenMsgDiag" BO_ 2617245696 1;
BA_ "GenMsgDiag" BO_ 2617245697 1;
BA_ "GenMsgDiag" BO_ 2617245698 1;
BA_ "GenMsgDiag" BO_ 2617245699 1;
BA_ "GenMsgDiag" BO_ 2617245700 1;
BA_ "GenMsgDiag" BO_ 2617245701 1;
BA_ "GenMsgDiag" BO_ 2617245702 1;
BA_ "GenMsgDiag" BO_ 2617245703 1;
BA_ "GenMsgDiag" BO_ 2617245704 1;
BA_ "GenMsgDiag" BO_ 2617245705 1;
BA_ "GenMsgDiag" BO_ 2617245706 1;
BA_ "GenMsgDiag" BO_ 2617245707 1;
BA_ "GenMsgDiag" BO_ 2618556416 1;
BA_ "GenMsgDiag" BO_ 2618556417 1;
BA_ "GenMsgDiag" BO_ 2618556418 1;
BA_ "GenMsgDiag" BO_ 2618556419 1;
BA_ "GenMsgDiag" BO_ 2618556420 1;
BA_ "GenMsgDiag" BO_ 2618556421 1;
BA_ "GenMsgDiag" BO_ 2618556422 1;
BA_ "GenMsgDiag" BO_ 2618556423 1;
BA_ "GenMsgDiag" BO_ 2618556424 1;
BA_ "GenMsgDiag" BO_ 2618556425 1;
BA_ "GenMsgDiag" BO_ 2618556426 1;
BA_ "GenMsgDiag" BO_ 2618556427 1;
BA_ "GenMsgDiag" BO_ 2618818560 1;
BA_ "GenMsgDiag" BO_ 2618818561 1;
BA_ "GenMsgDiag" BO_ 2618818562 1;
BA_ "GenMsgDiag" BO_ 2618818563 1;
BA_ "GenMsgDiag" BO_ 2618818564 1;
BA_ "GenMsgDiag" BO_ 2618818565 1;
BA_ "GenMsgDiag" BO_ 2618818566 1;
BA_ "GenMsgDiag" BO_ 2618818567 1;
BA_ "GenMsgDiag" BO_ 2618818568 1;
BA_ "GenMsgDiag" BO_ 2618818569 1;
BA_ "GenMsgDiag" BO_ 2618818570 1;
BA_ "GenMsgDiag" BO_ 2618818571 1;
BA_ "GenMsgDiag" BO_ 2619080704 1;
BA_ "GenMsgDiag" BO_ 2619080705 1;
BA_ "GenMsgDiag" BO_ 2619080706 1;
BA_ "GenMsgDiag" BO_ 2619080707 1;
BA_ "GenMsgDiag" BO_ 2619080708 1;
BA_ "GenMsgDiag" BO_ 2619080709 1;
BA_ "GenMsgDiag" BO_ 2619080710 1;
BA_ "GenMsgDiag" BO_ 2619080711 1;
BA_ "GenMsgDiag" BO_ 2619080712 1;
BA_ "GenMsgDiag" BO_ 2619080713 1;
BA_ "GenMsgDiag" BO_ 2619080714 1;
BA_ "GenMsgDiag" BO_ 2619080715 1;
BA_ "GenMsgDiag" BO_ 2619342848 1;
BA_ "GenMsgDiag" BO_ 2619342849 1;
BA_ "GenMsgDiag" BO_ 2619342850 1;
BA_ "GenMsgDiag" BO_ 2619342851 1;
BA_ "GenMsgDiag" BO_ 2619342852 1;
BA_ "GenMsgDiag" BO_ 2619342853 1;
BA_ "GenMsgDiag" BO_ 2619342854 1;
BA_ "GenMsgDiag" BO_ 2619342855 1;
BA_ "GenMsgDiag" BO_ 2619342856 1;
BA_ "GenMsgDiag" BO_ 2619342857 1;
BA_ "GenMsgDiag" BO_ 2619342858 1;
BA_ "GenMsgDiag" BO_ 2619342859 1;
BA_ "GenMsgDiag" BO_ 2619604992 1;
BA_ "GenMsgDiag" BO_ 2619604993 1;
BA_ "GenMsgDiag" BO_ 2619604994 1;
BA_ "GenMsgDiag" BO_ 2619604995 1;
BA_ "GenMsgDiag" BO_ 2619604996 1;
BA_ "GenMsgDiag" BO_ 2619604997 1;
BA_ "GenMsgDiag" BO_ 2619604998 1;
BA_ "GenMsgDiag" BO_ 2619604999 1;
BA_ "GenMsgDiag" BO_ 2619605000 1;
BA_ "GenMsgDiag" BO_ 2619605001 1;
BA_ "GenMsgDiag" BO_ 2619605002 1;
BA_ "GenMsgDiag" BO_ 2619605003 1;
BA_ "GenMsgDiag" BO_ 2620653568 1;
BA_ "GenMsgDiag" BO_ 2620653569 1;
BA_ "GenMsgDiag" BO_ 2620653570 1;
BA_ "GenMsgDiag" BO_ 2620653571 1;
BA_ "GenMsgDiag" BO_ 2620653572 1;
BA_ "GenMsgDiag" BO_ 2620653573 1;
BA_ "GenMsgDiag" BO_ 2620653574 1;
BA_ "GenMsgDiag" BO_ 2620653575 1;
BA_ "GenMsgDiag" BO_ 2620653576 1;
BA_ "GenMsgDiag" BO_ 2620653577 1;
BA_ "GenMsgDiag" BO_ 2620653578 1;
BA_ "GenMsgDiag" BO_ 2620653579 1;
BA_ "GenMsgDiag" BO_ 2620915712 1;
BA_ "GenMsgDiag" BO_ 2620915713 1;
BA_ "GenMsgDiag" BO_ 2620915714 1;
BA_ "GenMsgDiag" BO_ 2620915715 1;
BA_ "GenMsgDiag" BO_ 2620915716 1;
BA_ "GenMsgDiag" BO_ 2620915717 1;
BA_ "GenMsgDiag" BO_ 2620915718 1;
BA_ "GenMsgDiag" BO_ 2620915719 1;
BA_ "GenMsgDiag" BO_ 2620915720 1;
BA_ "GenMsgDiag" BO_ 2620915721 1;
BA_ "GenMsgDiag" BO_ 2620915722 1;
BA_ "GenMsgDiag" BO_ 2620915723 1;
BA_ "GenMsgDiag" BO_ 2621440000 1;
BA_ "GenMsgDiag" BO_ 2621440001 1;
BA_ "GenMsgDiag" BO_ 2621440002 1;
BA_ "GenMsgDiag" BO_ 2621440003 1;
BA_ "GenMsgDiag" BO_ 2621440004 1;
BA_ "GenMsgDiag" BO_ 2621440005 1;
BA_ "GenMsgDiag" BO_ 2621440006 1;
BA_ "GenMsgDiag" BO_ 2621440007 1;
BA_ "GenMsgDiag" BO_ 2621440008 1;
BA_ "GenMsgDiag" BO_ 2621440009 1;
BA_ "GenMsgDiag" BO_ 2621440010 1;
BA_ "GenMsgDiag" BO_ 2621440011 1;
BA_ "GenMsgDiag" BO_ 2621702144 1;
BA_ "GenMsgDiag" BO_ 2621702145 1;
BA_ "GenMsgDiag" BO_ 2621702146 1;
BA_ "GenMsgDiag" BO_ 2621702147 1;
BA_ "GenMsgDiag" BO_ 2621702148 1;
BA_ "GenMsgDiag" BO_ 2621702149 1;
BA_ "GenMsgDiag" BO_ 2621702150 1;
BA_ "GenMsgInstanced" BO_ 2571108363 "False";
BA_ "GenMsgInstanced" BO_ 2572156928 "False";
BA_ "GenMsgInstanced" BO_ 2572156929 "False";
BA_ "GenMsgInstanced" BO_ 2572156930 "False";
BA_ "GenMsgInstanced" BO_ 2572156931 "False";
BA_ "GenMsgInstanced" BO_ 2572156932 "False";
BA_ "GenMsgInstanced" BO_ 2572156933 "False";
BA_ "GenMsgInstanced" BO_ 2572156934 "False";
BA_ "GenMsgInstanced" BO_ 2572156935 "False";
BA_ "GenMsgInstanced" BO_ 2572156936 "False";
BA_ "GenMsgInstanced" BO_ 2572156937 "False";
BA_ "GenMsgInstanced" BO_ 2572156938 "False";
BA_ "GenMsgInstanced" BO_ 2572156939 "False";
BA_ "GenMsgInstanced" BO_ 2617245696 "False";
BA_ "GenMsgInstanced" BO_ 2617245697 "False";
BA_ "GenMsgInstanced" BO_ 2617245698 "False";
BA_ "GenMsgInstanced" BO_ 2617245699 "False";
BA_ "GenMsgInstanced" BO_ 2617245700 "False";
BA_ "GenMsgInstanced" BO_ 2617245701 "False";
BA_ "GenMsgInstanced" BO_ 2617245702 "False";
BA_ "GenMsgInstanced" BO_ 2617245703 "False";
BA_ "GenMsgInstanced" BO_ 2617245704 "False";
BA_ "GenMsgInstanced" BO_ 2617245705 "False";
BA_ "GenMsgInstanced" BO_ 2617245706 "False";
BA_ "GenMsgInstanced" BO_ 2617245707 "False";
BA_ "GenMsgInstanced" BO_ 2618556416 "False";
BA_ "GenMsgInstanced" BO_ 2618556417 "False";
BA_ "GenMsgInstanced" BO_ 2618556418 "False";
BA_ "GenMsgInstanced" BO_ 2618556419 "False";
BA_ "GenMsgInstanced" BO_ 2618556420 "False";
BA_ "GenMsgInstanced" BO_ 2618556421 "False";
BA_ "GenMsgInstanced" BO_ 2618556422 "False";
BA_ "GenMsgInstanced" BO_ 2618556423 "False";
BA_ "GenMsgInstanced" BO_ 2618556424 "False";
BA_ "GenMsgInstanced" BO_ 2618556425 "False";
BA_ "GenMsgInstanced" BO_ 2618556426 "False";
BA_ "GenMsgInstanced" BO_ 2618556427 "False";
BA_ "GenMsgInstanced" BO_ 2618818560 "False";
BA_ "GenMsgInstanced" BO_ 2618818561 "False";
BA_ "GenMsgInstanced" BO_ 2618818562 "False";
BA_ "GenMsgInstanced" BO_ 2618818563 "False";
BA_ "GenMsgInstanced" BO_ 2618818564 "False";
BA_ "GenMsgInstanced" BO_ 2618818565 "False";
BA_ "GenMsgInstanced" BO_ 2618818566 "False";
BA_ "GenMsgInstanced" BO_ 2618818567 "False";
BA_ "GenMsgInstanced" BO_ 2618818568 "False";
BA_ "GenMsgInstanced" BO_ 2618818569 "False";
BA_ "GenMsgInstanced" BO_ 2618818570 "False";
BA_ "GenMsgInstanced" BO_ 2618818571 "False";
BA_ "GenMsgInstanced" BO_ 2619080704 "False";
BA_ "GenMsgInstanced" BO_ 2619080705 "False";
BA_ "GenMsgInstanced" BO_ 2619080706 "False";
BA_ "GenMsgInstanced" BO_ 2619080707 "False";
BA_ "GenMsgInstanced" BO_ 2619080708 "False";
BA_ "GenMsgInstanced" BO_ 2619080709 "False";
BA_ "GenMsgInstanced" BO_ 2619080710 "False";
BA_ "GenMsgInstanced" BO_ 2619080711 "False";
BA_ "GenMsgInstanced" BO_ 2619080712 "False";
BA_ "GenMsgInstanced" BO_ 2619080713 "False";
BA_ "GenMsgInstanced" BO_ 2619080714 "False";
BA_ "GenMsgInstanced" BO_ 2619080715 "False";
BA_ "GenMsgInstanced" BO_ 2619342848 "False";
BA_ "GenMsgInstanced" BO_ 2619342849 "False";
BA_ "GenMsgInstanced" BO_ 2619342850 "False";
BA_ "GenMsgInstanced" BO_ 2619342851 "False";
BA_ "GenMsgInstanced" BO_ 2619342852 "False";
BA_ "GenMsgInstanced" BO_ 2619342853 "False";
BA_ "GenMsgInstanced" BO_ 2619342854 "False";
BA_ "GenMsgInstanced" BO_ 2619342855 "False";
BA_ "GenMsgInstanced" BO_ 2619342856 "False";
BA_ "GenMsgInstanced" BO_ 2619342857 "False";
BA_ "GenMsgInstanced" BO_ 2619342858 "False";
BA_ "GenMsgInstanced" BO_ 2619342859 "False";
BA_ "GenMsgInstanced" BO_ 2619604992 "False";
BA_ "GenMsgInstanced" BO_ 2619604993 "False";
BA_ "GenMsgInstanced" BO_ 2619604994 "False";
BA_ "GenMsgInstanced" BO_ 2619604995 "False";
BA_ "GenMsgInstanced" BO_ 2619604996 "False";
BA_ "GenMsgInstanced" BO_ 2619604997 "False";
BA_ "GenMsgInstanced" BO_ 2619604998 "False";
BA_ "GenMsgInstanced" BO_ 2619604999 "False";
BA_ "GenMsgInstanced" BO_ 2619605000 "False";
BA_ "GenMsgInstanced" BO_ 2619605001 "False";
BA_ "GenMsgInstanced" BO_ 2619605002 "False";
BA_ "GenMsgInstanced" BO_ 2619605003 "False";
BA_ "GenMsgInstanced" BO_ 2620653568 "False";
BA_ "GenMsgInstanced" BO_ 2620653569 "False";
BA_ "GenMsgInstanced" BO_ 2620653570 "False";
BA_ "GenMsgInstanced" BO_ 2620653571 "False";
BA_ "GenMsgInstanced" BO_ 2620653572 "False";
BA_ "GenMsgInstanced" BO_ 2620653573 "False";
BA_ "GenMsgInstanced" BO_ 2620653574 "False";
BA_ "GenMsgInstanced" BO_ 2620653575 "False";
BA_ "GenMsgInstanced" BO_ 2620653576 "False";
BA_ "GenMsgInstanced" BO_ 2620653577 "False";
BA_ "GenMsgInstanced" BO_ 2620653578 "False";
BA_ "GenMsgInstanced" BO_ 2620653579 "False";
BA_ "GenMsgInstanced" BO_ 2620915712 "False";
BA_ "GenMsgInstanced" BO_ 2620915713 "False";
BA_ "GenMsgInstanced" BO_ 2620915714 "False";
BA_ "GenMsgInstanced" BO_ 2620915715 "False";
BA_ "GenMsgInstanced" BO_ 2620915716 "False";
BA_ "GenMsgInstanced" BO_ 2620915717 "False";
BA_ "GenMsgInstanced" BO_ 2620915718 "False";
BA_ "GenMsgInstanced" BO_ 2620915719 "False";
BA_ "GenMsgInstanced" BO_ 2620915720 "False";
BA_ "GenMsgInstanced" BO_ 2620915721 "False";
BA_ "GenMsgInstanced" BO_ 2620915722 "False";
BA_ "GenMsgInstanced" BO_ 2620915723 "False";
BA_ "GenMsgInstanced" BO_ 2621440000 "False";
BA_ "GenMsgInstanced" BO_ 2621440001 "False";
BA_ "GenMsgInstanced" BO_ 2621440002 "False";
BA_ "GenMsgInstanced" BO_ 2621440003 "False";
BA_ "GenMsgInstanced" BO_ 2621440004 "False";
BA_ "GenMsgInstanced" BO_ 2621440005 "False";
BA_ "GenMsgInstanced" BO_ 2621440006 "False";
BA_ "GenMsgInstanced" BO_ 2621440007 "False";
BA_ "GenMsgInstanced" BO_ 2621440008 "False";
BA_ "GenMsgInstanced" BO_ 2621440009 "False";
BA_ "GenMsgInstanced" BO_ 2621440010 "False";
BA_ "GenMsgInstanced" BO_ 2621440011 "False";
BA_ "GenMsgInstanced" BO_ 2621702144 "False";
BA_ "GenMsgInstanced" BO_ 2621702145 "False";
BA_ "GenMsgInstanced" BO_ 2621702146 "False";
BA_ "GenMsgInstanced" BO_ 2621702147 "False";
BA_ "GenMsgInstanced" BO_ 2621702148 "False";
BA_ "GenMsgInstanced" BO_ 2621702149 "False";
BA_ "GenMsgInstanced" BO_ 2621702150 "False";
BA_ "GenMsgCycleTime" BO_ 2618556416 1000;
BA_ "GenMsgCycleTime" BO_ 2618556417 1000;
BA_ "GenMsgCycleTime" BO_ 2618556418 1000;
BA_ "GenMsgCycleTime" BO_ 2618556419 1000;
BA_ "GenMsgCycleTime" BO_ 2618556420 1000;
BA_ "GenMsgCycleTime" BO_ 2618556421 1000;
BA_ "GenMsgCycleTime" BO_ 2618556422 1000;
BA_ "GenMsgCycleTime" BO_ 2618556423 1000;
BA_ "GenMsgCycleTime" BO_ 2618556424 1000;
BA_ "GenMsgCycleTime" BO_ 2618556425 1000;
BA_ "GenMsgCycleTime" BO_ 2618556426 1000;
BA_ "GenMsgCycleTime" BO_ 2618556427 1000;
BA_ "GenMsgCycleTime" BO_ 2618818560 1000;
BA_ "GenMsgCycleTime" BO_ 2618818561 1000;
BA_ "GenMsgCycleTime" BO_ 2618818562 1000;
BA_ "GenMsgCycleTime" BO_ 2618818563 1000;
BA_ "GenMsgCycleTime" BO_ 2618818564 1000;
BA_ "GenMsgCycleTime" BO_ 2618818565 1000;
BA_ "GenMsgCycleTime" BO_ 2618818566 1000;
BA_ "GenMsgCycleTime" BO_ 2618818567 1000;
BA_ "GenMsgCycleTime" BO_ 2618818568 1000;
BA_ "GenMsgCycleTime" BO_ 2618818569 1000;
BA_ "GenMsgCycleTime" BO_ 2618818570 1000;
BA_ "GenMsgCycleTime" BO_ 2618818571 1000;
BA_ "GenSigType" SG_ 2571108363 BATT_packModIdFault_11 1;
BA_ "GenSigType" SG_ 2571108363 BATT_packModExitedFromBus_11 1;
BA_ "GenSigType" SG_ 2571108363 BATT_packFetChgWelded_11 1;
BA_ "GenSigType" SG_ 2571108363 BATT_packFetDsgWelded_11 1;
BA_ "GenSigType" SG_ 2571108363 BATT_fetDsgShortedAux_11 1;
BA_ "GenSigType" SG_ 2571108363 BATT_fetChgShortedAux_11 1;
BA_ "GenSigType" SG_ 2571108363 BATT_prechargeFetFail_11 1;
BA_ "GenSigType" SG_ 2571108363 BATT_abnormalResetReason_11 1;
BA_ "GenSigType" SG_ 2571108363 BATT_prechargeTooSlow_11 1;
BA_ "GenSigType" SG_ 2571108363 BATT_prechargeTooFast_11 1;
BA_ "GenSigType" SG_ 2571108363 BATT_prechargeTimeout_11 1;
BA_ "GenSigType" SG_ 2571108363 BATT_fetChgShorted_11 1;
BA_ "GenSigType" SG_ 2571108363 BATT_fetChgFailToClose_11 1;
BA_ "GenSigType" SG_ 2571108363 BATT_packModSelectFault_11 1;
BA_ "GenSigType" SG_ 2571108363 BATT_packModConnectFault_11 1;
BA_ "GenSigType" SG_ 2571108363 BATT_packModMIA_11 1;
BA_ "GenSigType" SG_ 2571108363 BATT_packModImbalance_11 1;
BA_ "GenSigType" SG_ 2571108363 BATT_afeFault_11 1;
BA_ "GenSigType" SG_ 2571108363 BATT_chargerMIA_11 1;
BA_ "GenSigType" SG_ 2571108363 BATT_chargerError_11 1;
BA_ "GenSigType" SG_ 2571108363 BATT_vBrickUnderWar_11 1;
BA_ "GenSigType" SG_ 2571108363 BATT_vBrickUnderSev_11 1;
BA_ "GenSigType" SG_ 2571108363 BATT_vBrickUnderMod_11 1;
BA_ "GenSigType" SG_ 2571108363 BATT_vBrickOverWar_11 1;
BA_ "GenSigType" SG_ 2571108363 BATT_vBrickOverSev_11 1;
BA_ "GenSigType" SG_ 2571108363 BATT_vBrickOverMod_11 1;
BA_ "GenSigType" SG_ 2571108363 BATT_vBrickImbalance_11 1;
BA_ "GenSigType" SG_ 2571108363 BATT_loggerAlmostFull_11 1;
BA_ "GenSigType" SG_ 2571108363 BATT_tempModuleUnderWar_11 1;
BA_ "GenSigType" SG_ 2571108363 BATT_tempModuleUnderSev_11 1;
BA_ "GenSigType" SG_ 2571108363 BATT_tempModuleUnderMod_11 1;
BA_ "GenSigType" SG_ 2571108363 BATT_tempModuleOverWar_11 1;
BA_ "GenSigType" SG_ 2571108363 BATT_tempModuleOverSev_11 1;
BA_ "GenSigType" SG_ 2571108363 BATT_tempModuleOverMod_11 1;
BA_ "GenSigType" SG_ 2571108363 BATT_tempBrickImbalance_11 1;
BA_ "GenSigType" SG_ 2571108363 BATT_taskLockupError_11 1;
BA_ "GenSigType" SG_ 2571108363 BATT_tempAmbientOverWar_11 1;
BA_ "GenSigType" SG_ 2571108363 BATT_tempAmbientOverSev_11 1;
BA_ "GenSigType" SG_ 2571108363 BATT_tempAmbientOverMod_11 1;
BA_ "GenSigType" SG_ 2571108363 BATT_sensePackVoltError_11 1;
BA_ "GenSigType" SG_ 2571108363 BATT_senseLoadVoltError_11 1;
BA_ "GenSigType" SG_ 2571108363 BATT_loggerFull_11 1;
BA_ "GenSigType" SG_ 2571108363 BATT_senseCurrentError_11 1;
BA_ "GenSigType" SG_ 2571108363 BATT_senseBrickTempError_11 1;
BA_ "GenSigType" SG_ 2571108363 BATT_resPackHigh_11 1;
BA_ "GenSigType" SG_ 2571108363 BATT_ramOverUtilError_11 1;
BA_ "GenSigType" SG_ 2571108363 BATT_powerPackInsufficient_11 1;
BA_ "GenSigType" SG_ 2571108363 BATT_packCellSoftShort_11 1;
BA_ "GenSigType" SG_ 2571108363 BATT_iOverHardware_11 1;
BA_ "GenSigType" SG_ 2571108363 BATT_fetOverTemp_11 1;
BA_ "GenSigType" SG_ 2571108363 BATT_iOverDischarge_11 1;
BA_ "GenSigType" SG_ 2571108363 BATT_iOverCharge_11 1;
BA_ "GenSigType" SG_ 2571108363 BATT_inverterDriveMIA_11 1;
BA_ "GenSigType" SG_ 2571108363 BATT_iUnderCharge_11 1;
BA_ "GenSigType" SG_ 2571108363 BATT_hostMIA_11 1;
BA_ "GenSigType" SG_ 2571108363 BATT_fetDsgShorted_11 1;
BA_ "GenSigType" SG_ 2571108363 BATT_fetDsgFailToClose_11 1;
BA_ "GenSigType" SG_ 2571108363 BATT_capLow_11 1;
BA_ "GenSigType" SG_ 2571108363 BATT_brickOverDischarge_11 1;
BA_ "GenSigType" SG_ 2571108363 BATT_brickOverCharge_11 1;
BA_ "GenSigType" SG_ 2571108363 BATT_bmsProcessorError_11 1;
BA_ "GenSigType" SG_ 2571108363 BATT_bmsMemoryError_11 1;
BA_ "GenSigType" SG_ 2571108363 BATT_afeError_11 1;
BA_ "GenSigType" SG_ 2572156928 BATT_harnessImpedanceFault_0 1;
BA_ "GenSigType" SG_ 2572156928 BATT_flashAppCRCError_0 1;
BA_ "GenSigType" SG_ 2572156928 BATT_cellOpenWire_0 1;
BA_ "GenSigType" SG_ 2572156928 BATT_packModCurrImbalance_0 1;
BA_ "GenSigType" SG_ 2572156928 BATT_flashBootCRCError_0 1;
BA_ "GenSigType" SG_ 2572156928 BATT_chargeNotNeeded_0 1;
BA_ "GenSigType" SG_ 2572156928 BATT_packModTempImbalance_0 1;
BA_ "GenSigType" SG_ 2572156928 BATT_modThermistorShorted_0 1;
BA_ "GenSigType" SG_ 2572156928 BATT_modThermistorOpenWire_0 1;
BA_ "GenSigType" SG_ 2572156928 BATT_multiIgnLoFault_0 1;
BA_ "GenSigType" SG_ 2572156928 BATT_packLevelArbitrationFault_0 1;
BA_ "GenSigType" SG_ 2572156929 BATT_modThermistorOpenWire_1 1;
BA_ "GenSigType" SG_ 2572156929 BATT_flashAppCRCError_1 1;
BA_ "GenSigType" SG_ 2572156929 BATT_cellOpenWire_1 1;
BA_ "GenSigType" SG_ 2572156929 BATT_packModCurrImbalance_1 1;
BA_ "GenSigType" SG_ 2572156929 BATT_multiIgnLoFault_1 1;
BA_ "GenSigType" SG_ 2572156929 BATT_flashBootCRCError_1 1;
BA_ "GenSigType" SG_ 2572156929 BATT_modThermistorShorted_1 1;
BA_ "GenSigType" SG_ 2572156929 BATT_packLevelArbitrationFault_1 1;
BA_ "GenSigType" SG_ 2572156929 BATT_chargeNotNeeded_1 1;
BA_ "GenSigType" SG_ 2572156929 BATT_packModTempImbalance_1 1;
BA_ "GenSigType" SG_ 2572156929 BATT_harnessImpedanceFault_1 1;
BA_ "GenSigType" SG_ 2572156930 BATT_packModCurrImbalance_2 1;
BA_ "GenSigType" SG_ 2572156930 BATT_modThermistorOpenWire_2 1;
BA_ "GenSigType" SG_ 2572156930 BATT_chargeNotNeeded_2 1;
BA_ "GenSigType" SG_ 2572156930 BATT_harnessImpedanceFault_2 1;
BA_ "GenSigType" SG_ 2572156930 BATT_packLevelArbitrationFault_2 1;
BA_ "GenSigType" SG_ 2572156930 BATT_flashAppCRCError_2 1;
BA_ "GenSigType" SG_ 2572156930 BATT_packModTempImbalance_2 1;
BA_ "GenSigType" SG_ 2572156930 BATT_cellOpenWire_2 1;
BA_ "GenSigType" SG_ 2572156930 BATT_flashBootCRCError_2 1;
BA_ "GenSigType" SG_ 2572156930 BATT_multiIgnLoFault_2 1;
BA_ "GenSigType" SG_ 2572156930 BATT_modThermistorShorted_2 1;
BA_ "GenSigType" SG_ 2572156931 BATT_flashBootCRCError_3 1;
BA_ "GenSigType" SG_ 2572156931 BATT_flashAppCRCError_3 1;
BA_ "GenSigType" SG_ 2572156931 BATT_harnessImpedanceFault_3 1;
BA_ "GenSigType" SG_ 2572156931 BATT_cellOpenWire_3 1;
BA_ "GenSigType" SG_ 2572156931 BATT_packLevelArbitrationFault_3 1;
BA_ "GenSigType" SG_ 2572156931 BATT_packModTempImbalance_3 1;
BA_ "GenSigType" SG_ 2572156931 BATT_packModCurrImbalance_3 1;
BA_ "GenSigType" SG_ 2572156931 BATT_modThermistorOpenWire_3 1;
BA_ "GenSigType" SG_ 2572156931 BATT_chargeNotNeeded_3 1;
BA_ "GenSigType" SG_ 2572156931 BATT_multiIgnLoFault_3 1;
BA_ "GenSigType" SG_ 2572156931 BATT_modThermistorShorted_3 1;
BA_ "GenSigType" SG_ 2572156932 BATT_flashAppCRCError_4 1;
BA_ "GenSigType" SG_ 2572156932 BATT_packModTempImbalance_4 1;
BA_ "GenSigType" SG_ 2572156932 BATT_cellOpenWire_4 1;
BA_ "GenSigType" SG_ 2572156932 BATT_packModCurrImbalance_4 1;
BA_ "GenSigType" SG_ 2572156932 BATT_flashBootCRCError_4 1;
BA_ "GenSigType" SG_ 2572156932 BATT_modThermistorOpenWire_4 1;
BA_ "GenSigType" SG_ 2572156932 BATT_multiIgnLoFault_4 1;
BA_ "GenSigType" SG_ 2572156932 BATT_harnessImpedanceFault_4 1;
BA_ "GenSigType" SG_ 2572156932 BATT_chargeNotNeeded_4 1;
BA_ "GenSigType" SG_ 2572156932 BATT_modThermistorShorted_4 1;
BA_ "GenSigType" SG_ 2572156932 BATT_packLevelArbitrationFault_4 1;
BA_ "GenSigType" SG_ 2572156933 BATT_packLevelArbitrationFault_5 1;
BA_ "GenSigType" SG_ 2572156933 BATT_modThermistorShorted_5 1;
BA_ "GenSigType" SG_ 2572156933 BATT_packModCurrImbalance_5 1;
BA_ "GenSigType" SG_ 2572156933 BATT_multiIgnLoFault_5 1;
BA_ "GenSigType" SG_ 2572156933 BATT_modThermistorOpenWire_5 1;
BA_ "GenSigType" SG_ 2572156933 BATT_harnessImpedanceFault_5 1;
BA_ "GenSigType" SG_ 2572156933 BATT_cellOpenWire_5 1;
BA_ "GenSigType" SG_ 2572156933 BATT_flashBootCRCError_5 1;
BA_ "GenSigType" SG_ 2572156933 BATT_flashAppCRCError_5 1;
BA_ "GenSigType" SG_ 2572156933 BATT_chargeNotNeeded_5 1;
BA_ "GenSigType" SG_ 2572156933 BATT_packModTempImbalance_5 1;
BA_ "GenSigType" SG_ 2572156934 BATT_modThermistorOpenWire_6 1;
BA_ "GenSigType" SG_ 2572156934 BATT_packModCurrImbalance_6 1;
BA_ "GenSigType" SG_ 2572156934 BATT_chargeNotNeeded_6 1;
BA_ "GenSigType" SG_ 2572156934 BATT_modThermistorShorted_6 1;
BA_ "GenSigType" SG_ 2572156934 BATT_packModTempImbalance_6 1;
BA_ "GenSigType" SG_ 2572156934 BATT_cellOpenWire_6 1;
BA_ "GenSigType" SG_ 2572156934 BATT_flashAppCRCError_6 1;
BA_ "GenSigType" SG_ 2572156934 BATT_packLevelArbitrationFault_6 1;
BA_ "GenSigType" SG_ 2572156934 BATT_multiIgnLoFault_6 1;
BA_ "GenSigType" SG_ 2572156934 BATT_harnessImpedanceFault_6 1;
BA_ "GenSigType" SG_ 2572156934 BATT_flashBootCRCError_6 1;
BA_ "GenSigType" SG_ 2572156935 BATT_cellOpenWire_7 1;
BA_ "GenSigType" SG_ 2572156935 BATT_modThermistorOpenWire_7 1;
BA_ "GenSigType" SG_ 2572156935 BATT_multiIgnLoFault_7 1;
BA_ "GenSigType" SG_ 2572156935 BATT_flashBootCRCError_7 1;
BA_ "GenSigType" SG_ 2572156935 BATT_modThermistorShorted_7 1;
BA_ "GenSigType" SG_ 2572156935 BATT_flashAppCRCError_7 1;
BA_ "GenSigType" SG_ 2572156935 BATT_packLevelArbitrationFault_7 1;
BA_ "GenSigType" SG_ 2572156935 BATT_chargeNotNeeded_7 1;
BA_ "GenSigType" SG_ 2572156935 BATT_packModTempImbalance_7 1;
BA_ "GenSigType" SG_ 2572156935 BATT_harnessImpedanceFault_7 1;
BA_ "GenSigType" SG_ 2572156935 BATT_packModCurrImbalance_7 1;
BA_ "GenSigType" SG_ 2572156936 BATT_modThermistorShorted_8 1;
BA_ "GenSigType" SG_ 2572156936 BATT_multiIgnLoFault_8 1;
BA_ "GenSigType" SG_ 2572156936 BATT_harnessImpedanceFault_8 1;
BA_ "GenSigType" SG_ 2572156936 BATT_packModTempImbalance_8 1;
BA_ "GenSigType" SG_ 2572156936 BATT_packModCurrImbalance_8 1;
BA_ "GenSigType" SG_ 2572156936 BATT_flashBootCRCError_8 1;
BA_ "GenSigType" SG_ 2572156936 BATT_flashAppCRCError_8 1;
BA_ "GenSigType" SG_ 2572156936 BATT_cellOpenWire_8 1;
BA_ "GenSigType" SG_ 2572156936 BATT_packLevelArbitrationFault_8 1;
BA_ "GenSigType" SG_ 2572156936 BATT_modThermistorOpenWire_8 1;
BA_ "GenSigType" SG_ 2572156936 BATT_chargeNotNeeded_8 1;
BA_ "GenSigType" SG_ 2572156937 BATT_chargeNotNeeded_9 1;
BA_ "GenSigType" SG_ 2572156937 BATT_flashBootCRCError_9 1;
BA_ "GenSigType" SG_ 2572156937 BATT_packModTempImbalance_9 1;
BA_ "GenSigType" SG_ 2572156937 BATT_packModCurrImbalance_9 1;
BA_ "GenSigType" SG_ 2572156937 BATT_flashAppCRCError_9 1;
BA_ "GenSigType" SG_ 2572156937 BATT_modThermistorShorted_9 1;
BA_ "GenSigType" SG_ 2572156937 BATT_packLevelArbitrationFault_9 1;
BA_ "GenSigType" SG_ 2572156937 BATT_multiIgnLoFault_9 1;
BA_ "GenSigType" SG_ 2572156937 BATT_modThermistorOpenWire_9 1;
BA_ "GenSigType" SG_ 2572156937 BATT_harnessImpedanceFault_9 1;
BA_ "GenSigType" SG_ 2572156937 BATT_cellOpenWire_9 1;
BA_ "GenSigType" SG_ 2572156938 BATT_cellOpenWire_10 1;
BA_ "GenSigType" SG_ 2572156938 BATT_modThermistorShorted_10 1;
BA_ "GenSigType" SG_ 2572156938 BATT_multiIgnLoFault_10 1;
BA_ "GenSigType" SG_ 2572156938 BATT_packLevelArbitrationFault_10 1;
BA_ "GenSigType" SG_ 2572156938 BATT_harnessImpedanceFault_10 1;
BA_ "GenSigType" SG_ 2572156938 BATT_chargeNotNeeded_10 1;
BA_ "GenSigType" SG_ 2572156938 BATT_modThermistorOpenWire_10 1;
BA_ "GenSigType" SG_ 2572156938 BATT_packModCurrImbalance_10 1;
BA_ "GenSigType" SG_ 2572156938 BATT_packModTempImbalance_10 1;
BA_ "GenSigType" SG_ 2572156938 BATT_flashAppCRCError_10 1;
BA_ "GenSigType" SG_ 2572156938 BATT_flashBootCRCError_10 1;
BA_ "GenSigType" SG_ 2572156939 BATT_modThermistorOpenWire_11 1;
BA_ "GenSigType" SG_ 2572156939 BATT_modThermistorShorted_11 1;
BA_ "GenSigType" SG_ 2572156939 BATT_flashBootCRCError_11 1;
BA_ "GenSigType" SG_ 2572156939 BATT_multiIgnLoFault_11 1;
BA_ "GenSigType" SG_ 2572156939 BATT_packModCurrImbalance_11 1;
BA_ "GenSigType" SG_ 2572156939 BATT_packLevelArbitrationFault_11 1;
BA_ "GenSigType" SG_ 2572156939 BATT_packModTempImbalance_11 1;
BA_ "GenSigType" SG_ 2572156939 BATT_chargeNotNeeded_11 1;
BA_ "GenSigType" SG_ 2572156939 BATT_harnessImpedanceFault_11 1;
BA_ "GenSigType" SG_ 2572156939 BATT_cellOpenWire_11 1;
BA_ "GenSigType" SG_ 2572156939 BATT_flashAppCRCError_11 1;
BA_ "GenSigType" SG_ 2617245696 BATT_totalRunTime_0 1;
BA_ "GenSigType" SG_ 2617245697 BATT_totalRunTime_1 1;
BA_ "GenSigType" SG_ 2617245698 BATT_totalRunTime_2 1;
BA_ "GenSigType" SG_ 2617245699 BATT_totalRunTime_3 1;
BA_ "GenSigType" SG_ 2617245700 BATT_totalRunTime_4 1;
BA_ "GenSigType" SG_ 2617245701 BATT_totalRunTime_5 1;
BA_ "GenSigType" SG_ 2617245702 BATT_totalRunTime_6 1;
BA_ "GenSigType" SG_ 2617245703 BATT_totalRunTime_7 1;
BA_ "GenSigType" SG_ 2617245704 BATT_totalRunTime_8 1;
BA_ "GenSigType" SG_ 2617245705 BATT_totalRunTime_9 1;
BA_ "GenSigType" SG_ 2617245706 BATT_totalRunTime_10 1;
BA_ "GenSigType" SG_ 2617245707 BATT_totalRunTime_11 1;
BA_ "GenSigType" SG_ 2618556416 BATT_fetChgDiagState_0 0;
BA_ "GenSigType" SG_ 2618556416 BATT_fetChgDiagIMeas_0 0;
BA_ "GenSigType" SG_ 2618556416 BATT_fetChgDiagClosedResult_0 0;
BA_ "GenSigType" SG_ 2618556416 BATT_fetChgDiagOpenResult_0 0;
BA_ "GenSigType" SG_ 2618556416 BATT_fetChgDiagVMeasPrime_0 0;
BA_ "GenSigType" SG_ 2618556416 BATT_fetChgDiagVMeas_0 0;
BA_ "GenSigType" SG_ 2618556417 BATT_fetChgDiagVMeas_1 0;
BA_ "GenSigType" SG_ 2618556417 BATT_fetChgDiagOpenResult_1 0;
BA_ "GenSigType" SG_ 2618556417 BATT_fetChgDiagClosedResult_1 0;
BA_ "GenSigType" SG_ 2618556417 BATT_fetChgDiagVMeasPrime_1 0;
BA_ "GenSigType" SG_ 2618556417 BATT_fetChgDiagIMeas_1 0;
BA_ "GenSigType" SG_ 2618556417 BATT_fetChgDiagState_1 0;
BA_ "GenSigType" SG_ 2618556418 BATT_fetChgDiagState_2 0;
BA_ "GenSigType" SG_ 2618556418 BATT_fetChgDiagVMeasPrime_2 0;
BA_ "GenSigType" SG_ 2618556418 BATT_fetChgDiagIMeas_2 0;
BA_ "GenSigType" SG_ 2618556418 BATT_fetChgDiagVMeas_2 0;
BA_ "GenSigType" SG_ 2618556418 BATT_fetChgDiagClosedResult_2 0;
BA_ "GenSigType" SG_ 2618556418 BATT_fetChgDiagOpenResult_2 0;
BA_ "GenSigType" SG_ 2618556419 BATT_fetChgDiagClosedResult_3 0;
BA_ "GenSigType" SG_ 2618556419 BATT_fetChgDiagIMeas_3 0;
BA_ "GenSigType" SG_ 2618556419 BATT_fetChgDiagVMeas_3 0;
BA_ "GenSigType" SG_ 2618556419 BATT_fetChgDiagOpenResult_3 0;
BA_ "GenSigType" SG_ 2618556419 BATT_fetChgDiagState_3 0;
BA_ "GenSigType" SG_ 2618556419 BATT_fetChgDiagVMeasPrime_3 0;
BA_ "GenSigType" SG_ 2618556420 BATT_fetChgDiagIMeas_4 0;
BA_ "GenSigType" SG_ 2618556420 BATT_fetChgDiagState_4 0;
BA_ "GenSigType" SG_ 2618556420 BATT_fetChgDiagVMeas_4 0;
BA_ "GenSigType" SG_ 2618556420 BATT_fetChgDiagVMeasPrime_4 0;
BA_ "GenSigType" SG_ 2618556420 BATT_fetChgDiagClosedResult_4 0;
BA_ "GenSigType" SG_ 2618556420 BATT_fetChgDiagOpenResult_4 0;
BA_ "GenSigType" SG_ 2618556421 BATT_fetChgDiagOpenResult_5 0;
BA_ "GenSigType" SG_ 2618556421 BATT_fetChgDiagVMeas_5 0;
BA_ "GenSigType" SG_ 2618556421 BATT_fetChgDiagClosedResult_5 0;
BA_ "GenSigType" SG_ 2618556421 BATT_fetChgDiagIMeas_5 0;
BA_ "GenSigType" SG_ 2618556421 BATT_fetChgDiagState_5 0;
BA_ "GenSigType" SG_ 2618556421 BATT_fetChgDiagVMeasPrime_5 0;
BA_ "GenSigType" SG_ 2618556422 BATT_fetChgDiagOpenResult_6 0;
BA_ "GenSigType" SG_ 2618556422 BATT_fetChgDiagVMeas_6 0;
BA_ "GenSigType" SG_ 2618556422 BATT_fetChgDiagIMeas_6 0;
BA_ "GenSigType" SG_ 2618556422 BATT_fetChgDiagState_6 0;
BA_ "GenSigType" SG_ 2618556422 BATT_fetChgDiagClosedResult_6 0;
BA_ "GenSigType" SG_ 2618556422 BATT_fetChgDiagVMeasPrime_6 0;
BA_ "GenSigType" SG_ 2618556423 BATT_fetChgDiagState_7 0;
BA_ "GenSigType" SG_ 2618556423 BATT_fetChgDiagClosedResult_7 0;
BA_ "GenSigType" SG_ 2618556423 BATT_fetChgDiagIMeas_7 0;
BA_ "GenSigType" SG_ 2618556423 BATT_fetChgDiagVMeasPrime_7 0;
BA_ "GenSigType" SG_ 2618556423 BATT_fetChgDiagVMeas_7 0;
BA_ "GenSigType" SG_ 2618556423 BATT_fetChgDiagOpenResult_7 0;
BA_ "GenSigType" SG_ 2618556424 BATT_fetChgDiagClosedResult_8 0;
BA_ "GenSigType" SG_ 2618556424 BATT_fetChgDiagOpenResult_8 0;
BA_ "GenSigType" SG_ 2618556424 BATT_fetChgDiagVMeasPrime_8 0;
BA_ "GenSigType" SG_ 2618556424 BATT_fetChgDiagVMeas_8 0;
BA_ "GenSigType" SG_ 2618556424 BATT_fetChgDiagIMeas_8 0;
BA_ "GenSigType" SG_ 2618556424 BATT_fetChgDiagState_8 0;
BA_ "GenSigType" SG_ 2618556425 BATT_fetChgDiagState_9 0;
BA_ "GenSigType" SG_ 2618556425 BATT_fetChgDiagIMeas_9 0;
BA_ "GenSigType" SG_ 2618556425 BATT_fetChgDiagVMeasPrime_9 0;
BA_ "GenSigType" SG_ 2618556425 BATT_fetChgDiagVMeas_9 0;
BA_ "GenSigType" SG_ 2618556425 BATT_fetChgDiagClosedResult_9 0;
BA_ "GenSigType" SG_ 2618556425 BATT_fetChgDiagOpenResult_9 0;
BA_ "GenSigType" SG_ 2618556426 BATT_fetChgDiagIMeas_10 0;
BA_ "GenSigType" SG_ 2618556426 BATT_fetChgDiagState_10 0;
BA_ "GenSigType" SG_ 2618556426 BATT_fetChgDiagVMeasPrime_10 0;
BA_ "GenSigType" SG_ 2618556426 BATT_fetChgDiagClosedResult_10 0;
BA_ "GenSigType" SG_ 2618556426 BATT_fetChgDiagOpenResult_10 0;
BA_ "GenSigType" SG_ 2618556426 BATT_fetChgDiagVMeas_10 0;
BA_ "GenSigType" SG_ 2618556427 BATT_fetChgDiagVMeasPrime_11 0;
BA_ "GenSigType" SG_ 2618556427 BATT_fetChgDiagIMeas_11 0;
BA_ "GenSigType" SG_ 2618556427 BATT_fetChgDiagOpenResult_11 0;
BA_ "GenSigType" SG_ 2618556427 BATT_fetChgDiagClosedResult_11 0;
BA_ "GenSigType" SG_ 2618556427 BATT_fetChgDiagVMeas_11 0;
BA_ "GenSigType" SG_ 2618556427 BATT_fetChgDiagState_11 0;
BA_ "GenSigType" SG_ 2618818560 BATT_fetDsgDiagClosedResult_0 0;
BA_ "GenSigType" SG_ 2618818560 BATT_fetDsgDiagVMeasPrime_0 0;
BA_ "GenSigType" SG_ 2618818560 BATT_fetDsgDiagIMeas_0 0;
BA_ "GenSigType" SG_ 2618818560 BATT_fetDsgDiagVMeas_0 0;
BA_ "GenSigType" SG_ 2618818560 BATT_fetDsgDiagState_0 0;
BA_ "GenSigType" SG_ 2618818560 BATT_fetDsgDiagOpenResult_0 0;
BA_ "GenSigType" SG_ 2618818561 BATT_fetDsgDiagState_1 0;
BA_ "GenSigType" SG_ 2618818561 BATT_fetDsgDiagClosedResult_1 0;
BA_ "GenSigType" SG_ 2618818561 BATT_fetDsgDiagIMeas_1 0;
BA_ "GenSigType" SG_ 2618818561 BATT_fetDsgDiagVMeas_1 0;
BA_ "GenSigType" SG_ 2618818561 BATT_fetDsgDiagOpenResult_1 0;
BA_ "GenSigType" SG_ 2618818561 BATT_fetDsgDiagVMeasPrime_1 0;
BA_ "GenSigType" SG_ 2618818562 BATT_fetDsgDiagVMeas_2 0;
BA_ "GenSigType" SG_ 2618818562 BATT_fetDsgDiagVMeasPrime_2 0;
BA_ "GenSigType" SG_ 2618818562 BATT_fetDsgDiagOpenResult_2 0;
BA_ "GenSigType" SG_ 2618818562 BATT_fetDsgDiagClosedResult_2 0;
BA_ "GenSigType" SG_ 2618818562 BATT_fetDsgDiagIMeas_2 0;
BA_ "GenSigType" SG_ 2618818562 BATT_fetDsgDiagState_2 0;
BA_ "GenSigType" SG_ 2618818563 BATT_fetDsgDiagState_3 0;
BA_ "GenSigType" SG_ 2618818563 BATT_fetDsgDiagVMeas_3 0;
BA_ "GenSigType" SG_ 2618818563 BATT_fetDsgDiagOpenResult_3 0;
BA_ "GenSigType" SG_ 2618818563 BATT_fetDsgDiagClosedResult_3 0;
BA_ "GenSigType" SG_ 2618818563 BATT_fetDsgDiagVMeasPrime_3 0;
BA_ "GenSigType" SG_ 2618818563 BATT_fetDsgDiagIMeas_3 0;
BA_ "GenSigType" SG_ 2618818564 BATT_fetDsgDiagOpenResult_4 0;
BA_ "GenSigType" SG_ 2618818564 BATT_fetDsgDiagState_4 0;
BA_ "GenSigType" SG_ 2618818564 BATT_fetDsgDiagIMeas_4 0;
BA_ "GenSigType" SG_ 2618818564 BATT_fetDsgDiagVMeas_4 0;
BA_ "GenSigType" SG_ 2618818564 BATT_fetDsgDiagVMeasPrime_4 0;
BA_ "GenSigType" SG_ 2618818564 BATT_fetDsgDiagClosedResult_4 0;
BA_ "GenSigType" SG_ 2618818565 BATT_fetDsgDiagClosedResult_5 0;
BA_ "GenSigType" SG_ 2618818565 BATT_fetDsgDiagState_5 0;
BA_ "GenSigType" SG_ 2618818565 BATT_fetDsgDiagVMeas_5 0;
BA_ "GenSigType" SG_ 2618818565 BATT_fetDsgDiagVMeasPrime_5 0;
BA_ "GenSigType" SG_ 2618818565 BATT_fetDsgDiagOpenResult_5 0;
BA_ "GenSigType" SG_ 2618818565 BATT_fetDsgDiagIMeas_5 0;
BA_ "GenSigType" SG_ 2618818566 BATT_fetDsgDiagClosedResult_6 0;
BA_ "GenSigType" SG_ 2618818566 BATT_fetDsgDiagState_6 0;
BA_ "GenSigType" SG_ 2618818566 BATT_fetDsgDiagIMeas_6 0;
BA_ "GenSigType" SG_ 2618818566 BATT_fetDsgDiagVMeasPrime_6 0;
BA_ "GenSigType" SG_ 2618818566 BATT_fetDsgDiagVMeas_6 0;
BA_ "GenSigType" SG_ 2618818566 BATT_fetDsgDiagOpenResult_6 0;
BA_ "GenSigType" SG_ 2618818567 BATT_fetDsgDiagClosedResult_7 0;
BA_ "GenSigType" SG_ 2618818567 BATT_fetDsgDiagState_7 0;
BA_ "GenSigType" SG_ 2618818567 BATT_fetDsgDiagVMeasPrime_7 0;
BA_ "GenSigType" SG_ 2618818567 BATT_fetDsgDiagVMeas_7 0;
BA_ "GenSigType" SG_ 2618818567 BATT_fetDsgDiagOpenResult_7 0;
BA_ "GenSigType" SG_ 2618818567 BATT_fetDsgDiagIMeas_7 0;
BA_ "GenSigType" SG_ 2618818568 BATT_fetDsgDiagIMeas_8 0;
BA_ "GenSigType" SG_ 2618818568 BATT_fetDsgDiagState_8 0;
BA_ "GenSigType" SG_ 2618818568 BATT_fetDsgDiagOpenResult_8 0;
BA_ "GenSigType" SG_ 2618818568 BATT_fetDsgDiagClosedResult_8 0;
BA_ "GenSigType" SG_ 2618818568 BATT_fetDsgDiagVMeas_8 0;
BA_ "GenSigType" SG_ 2618818568 BATT_fetDsgDiagVMeasPrime_8 0;
BA_ "GenSigType" SG_ 2618818569 BATT_fetDsgDiagClosedResult_9 0;
BA_ "GenSigType" SG_ 2618818569 BATT_fetDsgDiagState_9 0;
BA_ "GenSigType" SG_ 2618818569 BATT_fetDsgDiagVMeas_9 0;
BA_ "GenSigType" SG_ 2618818569 BATT_fetDsgDiagOpenResult_9 0;
BA_ "GenSigType" SG_ 2618818569 BATT_fetDsgDiagVMeasPrime_9 0;
BA_ "GenSigType" SG_ 2618818569 BATT_fetDsgDiagIMeas_9 0;
BA_ "GenSigType" SG_ 2618818570 BATT_fetDsgDiagOpenResult_10 0;
BA_ "GenSigType" SG_ 2618818570 BATT_fetDsgDiagIMeas_10 0;
BA_ "GenSigType" SG_ 2618818570 BATT_fetDsgDiagVMeas_10 0;
BA_ "GenSigType" SG_ 2618818570 BATT_fetDsgDiagState_10 0;
BA_ "GenSigType" SG_ 2618818570 BATT_fetDsgDiagClosedResult_10 0;
BA_ "GenSigType" SG_ 2618818570 BATT_fetDsgDiagVMeasPrime_10 0;
BA_ "GenSigType" SG_ 2618818571 BATT_fetDsgDiagOpenResult_11 0;
BA_ "GenSigType" SG_ 2618818571 BATT_fetDsgDiagClosedResult_11 0;
BA_ "GenSigType" SG_ 2618818571 BATT_fetDsgDiagVMeasPrime_11 0;
BA_ "GenSigType" SG_ 2618818571 BATT_fetDsgDiagIMeas_11 0;
BA_ "GenSigType" SG_ 2618818571 BATT_fetDsgDiagState_11 0;
BA_ "GenSigType" SG_ 2618818571 BATT_fetDsgDiagVMeas_11 0;
BA_ "GenSigType" SG_ 2619080704 BATT_resBrick04_0 1;
BA_ "GenSigType" SG_ 2619080704 BATT_resBrick03_0 1;
BA_ "GenSigType" SG_ 2619080704 BATT_resBrick01_0 1;
BA_ "GenSigType" SG_ 2619080705 BATT_resBrick04_1 1;
BA_ "GenSigType" SG_ 2619080705 BATT_resBrick03_1 1;
BA_ "GenSigType" SG_ 2619080705 BATT_resBrick01_1 1;
BA_ "GenSigType" SG_ 2619080706 BATT_resBrick04_2 1;
BA_ "GenSigType" SG_ 2619080706 BATT_resBrick03_2 1;
BA_ "GenSigType" SG_ 2619080706 BATT_resBrick01_2 1;
BA_ "GenSigType" SG_ 2619080707 BATT_resBrick04_3 1;
BA_ "GenSigType" SG_ 2619080707 BATT_resBrick03_3 1;
BA_ "GenSigType" SG_ 2619080707 BATT_resBrick01_3 1;
BA_ "GenSigType" SG_ 2619080708 BATT_resBrick04_4 1;
BA_ "GenSigType" SG_ 2619080708 BATT_resBrick03_4 1;
BA_ "GenSigType" SG_ 2619080708 BATT_resBrick01_4 1;
BA_ "GenSigType" SG_ 2619080709 BATT_resBrick04_5 1;
BA_ "GenSigType" SG_ 2619080709 BATT_resBrick03_5 1;
BA_ "GenSigType" SG_ 2619080709 BATT_resBrick01_5 1;
BA_ "GenSigType" SG_ 2619080710 BATT_resBrick04_6 1;
BA_ "GenSigType" SG_ 2619080710 BATT_resBrick03_6 1;
BA_ "GenSigType" SG_ 2619080710 BATT_resBrick01_6 1;
BA_ "GenSigType" SG_ 2619080711 BATT_resBrick04_7 1;
BA_ "GenSigType" SG_ 2619080711 BATT_resBrick03_7 1;
BA_ "GenSigType" SG_ 2619080711 BATT_resBrick01_7 1;
BA_ "GenSigType" SG_ 2619080712 BATT_resBrick04_8 1;
BA_ "GenSigType" SG_ 2619080712 BATT_resBrick03_8 1;
BA_ "GenSigType" SG_ 2619080712 BATT_resBrick01_8 1;
BA_ "GenSigType" SG_ 2619080713 BATT_resBrick04_9 1;
BA_ "GenSigType" SG_ 2619080713 BATT_resBrick03_9 1;
BA_ "GenSigType" SG_ 2619080713 BATT_resBrick01_9 1;
BA_ "GenSigType" SG_ 2619080714 BATT_resBrick04_10 1;
BA_ "GenSigType" SG_ 2619080714 BATT_resBrick03_10 1;
BA_ "GenSigType" SG_ 2619080714 BATT_resBrick01_10 1;
BA_ "GenSigType" SG_ 2619080715 BATT_resBrick04_11 1;
BA_ "GenSigType" SG_ 2619080715 BATT_resBrick03_11 1;
BA_ "GenSigType" SG_ 2619080715 BATT_resBrick01_11 1;
BA_ "GenSigType" SG_ 2619342848 BATT_resBrick08_0 1;
BA_ "GenSigType" SG_ 2619342848 BATT_resBrick07_0 1;
BA_ "GenSigType" SG_ 2619342848 BATT_resBrick06_0 1;
BA_ "GenSigType" SG_ 2619342848 BATT_resBrick05_0 1;
BA_ "GenSigType" SG_ 2619342849 BATT_resBrick08_1 1;
BA_ "GenSigType" SG_ 2619342849 BATT_resBrick07_1 1;
BA_ "GenSigType" SG_ 2619342849 BATT_resBrick06_1 1;
BA_ "GenSigType" SG_ 2619342849 BATT_resBrick05_1 1;
BA_ "GenSigType" SG_ 2619342850 BATT_resBrick08_2 1;
BA_ "GenSigType" SG_ 2619342850 BATT_resBrick07_2 1;
BA_ "GenSigType" SG_ 2619342850 BATT_resBrick06_2 1;
BA_ "GenSigType" SG_ 2619342850 BATT_resBrick05_2 1;
BA_ "GenSigType" SG_ 2619342851 BATT_resBrick08_3 1;
BA_ "GenSigType" SG_ 2619342851 BATT_resBrick07_3 1;
BA_ "GenSigType" SG_ 2619342851 BATT_resBrick06_3 1;
BA_ "GenSigType" SG_ 2619342851 BATT_resBrick05_3 1;
BA_ "GenSigType" SG_ 2619342852 BATT_resBrick08_4 1;
BA_ "GenSigType" SG_ 2619342852 BATT_resBrick07_4 1;
BA_ "GenSigType" SG_ 2619342852 BATT_resBrick06_4 1;
BA_ "GenSigType" SG_ 2619342852 BATT_resBrick05_4 1;
BA_ "GenSigType" SG_ 2619342853 BATT_resBrick08_5 1;
BA_ "GenSigType" SG_ 2619342853 BATT_resBrick07_5 1;
BA_ "GenSigType" SG_ 2619342853 BATT_resBrick06_5 1;
BA_ "GenSigType" SG_ 2619342853 BATT_resBrick05_5 1;
BA_ "GenSigType" SG_ 2619342854 BATT_resBrick08_6 1;
BA_ "GenSigType" SG_ 2619342854 BATT_resBrick07_6 1;
BA_ "GenSigType" SG_ 2619342854 BATT_resBrick06_6 1;
BA_ "GenSigType" SG_ 2619342854 BATT_resBrick05_6 1;
BA_ "GenSigType" SG_ 2619342855 BATT_resBrick08_7 1;
BA_ "GenSigType" SG_ 2619342855 BATT_resBrick07_7 1;
BA_ "GenSigType" SG_ 2619342855 BATT_resBrick06_7 1;
BA_ "GenSigType" SG_ 2619342855 BATT_resBrick05_7 1;
BA_ "GenSigType" SG_ 2619342856 BATT_resBrick08_8 1;
BA_ "GenSigType" SG_ 2619342856 BATT_resBrick07_8 1;
BA_ "GenSigType" SG_ 2619342856 BATT_resBrick06_8 1;
BA_ "GenSigType" SG_ 2619342856 BATT_resBrick05_8 1;
BA_ "GenSigType" SG_ 2619342857 BATT_resBrick08_9 1;
BA_ "GenSigType" SG_ 2619342857 BATT_resBrick07_9 1;
BA_ "GenSigType" SG_ 2619342857 BATT_resBrick06_9 1;
BA_ "GenSigType" SG_ 2619342857 BATT_resBrick05_9 1;
BA_ "GenSigType" SG_ 2619342858 BATT_resBrick08_10 1;
BA_ "GenSigType" SG_ 2619342858 BATT_resBrick07_10 1;
BA_ "GenSigType" SG_ 2619342858 BATT_resBrick06_10 1;
BA_ "GenSigType" SG_ 2619342858 BATT_resBrick05_10 1;
BA_ "GenSigType" SG_ 2619342859 BATT_resBrick08_11 1;
BA_ "GenSigType" SG_ 2619342859 BATT_resBrick07_11 1;
BA_ "GenSigType" SG_ 2619342859 BATT_resBrick06_11 1;
BA_ "GenSigType" SG_ 2619342859 BATT_resBrick05_11 1;
BA_ "GenSigType" SG_ 2619604992 BATT_resBrick12_0 1;
BA_ "GenSigType" SG_ 2619604992 BATT_resBrick11_0 1;
BA_ "GenSigType" SG_ 2619604992 BATT_resBrick09_0 1;
BA_ "GenSigType" SG_ 2619604992 BATT_resBrick10_0 1;
BA_ "GenSigType" SG_ 2619604993 BATT_resBrick12_1 1;
BA_ "GenSigType" SG_ 2619604993 BATT_resBrick11_1 1;
BA_ "GenSigType" SG_ 2619604993 BATT_resBrick09_1 1;
BA_ "GenSigType" SG_ 2619604993 BATT_resBrick10_1 1;
BA_ "GenSigType" SG_ 2619604994 BATT_resBrick12_2 1;
BA_ "GenSigType" SG_ 2619604994 BATT_resBrick11_2 1;
BA_ "GenSigType" SG_ 2619604994 BATT_resBrick09_2 1;
BA_ "GenSigType" SG_ 2619604994 BATT_resBrick10_2 1;
BA_ "GenSigType" SG_ 2619604995 BATT_resBrick12_3 1;
BA_ "GenSigType" SG_ 2619604995 BATT_resBrick11_3 1;
BA_ "GenSigType" SG_ 2619604995 BATT_resBrick09_3 1;
BA_ "GenSigType" SG_ 2619604995 BATT_resBrick10_3 1;
BA_ "GenSigType" SG_ 2619604996 BATT_resBrick12_4 1;
BA_ "GenSigType" SG_ 2619604996 BATT_resBrick11_4 1;
BA_ "GenSigType" SG_ 2619604996 BATT_resBrick09_4 1;
BA_ "GenSigType" SG_ 2619604996 BATT_resBrick10_4 1;
BA_ "GenSigType" SG_ 2619604997 BATT_resBrick12_5 1;
BA_ "GenSigType" SG_ 2619604997 BATT_resBrick11_5 1;
BA_ "GenSigType" SG_ 2619604997 BATT_resBrick09_5 1;
BA_ "GenSigType" SG_ 2619604997 BATT_resBrick10_5 1;
BA_ "GenSigType" SG_ 2619604998 BATT_resBrick12_6 1;
BA_ "GenSigType" SG_ 2619604998 BATT_resBrick11_6 1;
BA_ "GenSigType" SG_ 2619604998 BATT_resBrick09_6 1;
BA_ "GenSigType" SG_ 2619604998 BATT_resBrick10_6 1;
BA_ "GenSigType" SG_ 2619604999 BATT_resBrick12_7 1;
BA_ "GenSigType" SG_ 2619604999 BATT_resBrick11_7 1;
BA_ "GenSigType" SG_ 2619604999 BATT_resBrick09_7 1;
BA_ "GenSigType" SG_ 2619604999 BATT_resBrick10_7 1;
BA_ "GenSigType" SG_ 2619605000 BATT_resBrick12_8 1;
BA_ "GenSigType" SG_ 2619605000 BATT_resBrick11_8 1;
BA_ "GenSigType" SG_ 2619605000 BATT_resBrick09_8 1;
BA_ "GenSigType" SG_ 2619605000 BATT_resBrick10_8 1;
BA_ "GenSigType" SG_ 2619605001 BATT_resBrick12_9 1;
BA_ "GenSigType" SG_ 2619605001 BATT_resBrick11_9 1;
BA_ "GenSigType" SG_ 2619605001 BATT_resBrick09_9 1;
BA_ "GenSigType" SG_ 2619605001 BATT_resBrick10_9 1;
BA_ "GenSigType" SG_ 2619605002 BATT_resBrick12_10 1;
BA_ "GenSigType" SG_ 2619605002 BATT_resBrick11_10 1;
BA_ "GenSigType" SG_ 2619605002 BATT_resBrick09_10 1;
BA_ "GenSigType" SG_ 2619605002 BATT_resBrick10_10 1;
BA_ "GenSigType" SG_ 2619605003 BATT_resBrick12_11 1;
BA_ "GenSigType" SG_ 2619605003 BATT_resBrick11_11 1;
BA_ "GenSigType" SG_ 2619605003 BATT_resBrick09_11 1;
BA_ "GenSigType" SG_ 2619605003 BATT_resBrick10_11 1;
BA_ "GenSigType" SG_ 2621440000 BATT_resBrick14_0 1;
BA_ "GenSigType" SG_ 2621440000 BATT_resBrick13_0 1;
BA_ "GenSigType" SG_ 2621440001 BATT_resBrick14_1 1;
BA_ "GenSigType" SG_ 2621440001 BATT_resBrick13_1 1;
BA_ "GenSigType" SG_ 2621440002 BATT_resBrick14_2 1;
BA_ "GenSigType" SG_ 2621440002 BATT_resBrick13_2 1;
BA_ "GenSigType" SG_ 2621440003 BATT_resBrick14_3 1;
BA_ "GenSigType" SG_ 2621440003 BATT_resBrick13_3 1;
BA_ "GenSigType" SG_ 2621440004 BATT_resBrick14_4 1;
BA_ "GenSigType" SG_ 2621440004 BATT_resBrick13_4 1;
BA_ "GenSigType" SG_ 2621440005 BATT_resBrick14_5 1;
BA_ "GenSigType" SG_ 2621440005 BATT_resBrick13_5 1;
BA_ "GenSigType" SG_ 2621440006 BATT_resBrick14_6 1;
BA_ "GenSigType" SG_ 2621440006 BATT_resBrick13_6 1;
BA_ "GenSigType" SG_ 2621440007 BATT_resBrick14_7 1;
BA_ "GenSigType" SG_ 2621440007 BATT_resBrick13_7 1;
BA_ "GenSigType" SG_ 2621440008 BATT_resBrick14_8 1;
BA_ "GenSigType" SG_ 2621440008 BATT_resBrick13_8 1;
BA_ "GenSigType" SG_ 2621440009 BATT_resBrick14_9 1;
BA_ "GenSigType" SG_ 2621440009 BATT_resBrick13_9 1;
BA_ "GenSigType" SG_ 2621440010 BATT_resBrick14_10 1;
BA_ "GenSigType" SG_ 2621440010 BATT_resBrick13_10 1;
BA_ "GenSigType" SG_ 2621440011 BATT_resBrick14_11 1;
BA_ "GenSigType" SG_ 2621440011 BATT_resBrick13_11 1;
BA_ "GenSigType" SG_ 2621702144 BATT_capBrick04_0 1;
BA_ "GenSigType" SG_ 2621702144 BATT_capBrick03_0 1;
BA_ "GenSigType" SG_ 2621702144 BATT_capBrick02_0 1;
BA_ "GenSigType" SG_ 2621702144 BATT_capBrick01_0 1;
BA_ "GenSigType" SG_ 2621702145 BATT_capBrick04_1 1;
BA_ "GenSigType" SG_ 2621702145 BATT_capBrick03_1 1;
BA_ "GenSigType" SG_ 2621702145 BATT_capBrick02_1 1;
BA_ "GenSigType" SG_ 2621702145 BATT_capBrick01_1 1;
BA_ "GenSigType" SG_ 2621702146 BATT_capBrick04_2 1;
BA_ "GenSigType" SG_ 2621702146 BATT_capBrick03_2 1;
BA_ "GenSigType" SG_ 2621702146 BATT_capBrick02_2 1;
BA_ "GenSigType" SG_ 2621702146 BATT_capBrick01_2 1;
BA_ "GenSigType" SG_ 2621702147 BATT_capBrick04_3 1;
BA_ "GenSigType" SG_ 2621702147 BATT_capBrick03_3 1;
BA_ "GenSigType" SG_ 2621702147 BATT_capBrick02_3 1;
BA_ "GenSigType" SG_ 2621702147 BATT_capBrick01_3 1;
BA_ "GenSigType" SG_ 2621702148 BATT_capBrick04_4 1;
BA_ "GenSigType" SG_ 2621702148 BATT_capBrick03_4 1;
BA_ "GenSigType" SG_ 2621702148 BATT_capBrick02_4 1;
BA_ "GenSigType" SG_ 2621702148 BATT_capBrick01_4 1;
BA_ "GenSigType" SG_ 2621702149 BATT_capBrick04_5 1;
BA_ "GenSigType" SG_ 2621702149 BATT_capBrick03_5 1;
BA_ "GenSigType" SG_ 2621702149 BATT_capBrick02_5 1;
BA_ "GenSigType" SG_ 2621702149 BATT_capBrick01_5 1;
BA_ "GenSigType" SG_ 2621702150 BATT_capBrick04_6 1;
BA_ "GenSigType" SG_ 2621702150 BATT_capBrick03_6 1;
BA_ "GenSigType" SG_ 2621702150 BATT_capBrick02_6 1;
BA_ "GenSigType" SG_ 2621702150 BATT_capBrick01_6 1;
BA_ "GenSigSNA" SG_ 2572156928 BATT_harnessImpedanceFault_0 65535;
BA_ "GenSigSNA" SG_ 2572156929 BATT_harnessImpedanceFault_1 65535;
BA_ "GenSigSNA" SG_ 2572156930 BATT_harnessImpedanceFault_2 65535;
BA_ "GenSigSNA" SG_ 2572156931 BATT_harnessImpedanceFault_3 65535;
BA_ "GenSigSNA" SG_ 2572156932 BATT_harnessImpedanceFault_4 65535;
BA_ "GenSigSNA" SG_ 2572156933 BATT_harnessImpedanceFault_5 65535;
BA_ "GenSigSNA" SG_ 2572156934 BATT_harnessImpedanceFault_6 65535;
BA_ "GenSigSNA" SG_ 2572156935 BATT_harnessImpedanceFault_7 65535;
BA_ "GenSigSNA" SG_ 2572156936 BATT_harnessImpedanceFault_8 65535;
BA_ "GenSigSNA" SG_ 2572156937 BATT_harnessImpedanceFault_9 65535;
BA_ "GenSigSNA" SG_ 2572156938 BATT_harnessImpedanceFault_10 65535;
BA_ "GenSigSNA" SG_ 2572156939 BATT_harnessImpedanceFault_11 65535;
BA_ "GenSigSNA" SG_ 2619080704 BATT_resBrick04_0 65535;
BA_ "GenSigSNA" SG_ 2619080704 BATT_resBrick03_0 65535;
BA_ "GenSigSNA" SG_ 2619080704 BATT_resBrick02_0 65535;
BA_ "GenSigSNA" SG_ 2619080705 BATT_resBrick04_1 65535;
BA_ "GenSigSNA" SG_ 2619080705 BATT_resBrick03_1 65535;
BA_ "GenSigSNA" SG_ 2619080705 BATT_resBrick02_1 65535;
BA_ "GenSigSNA" SG_ 2619080706 BATT_resBrick04_2 65535;
BA_ "GenSigSNA" SG_ 2619080706 BATT_resBrick03_2 65535;
BA_ "GenSigSNA" SG_ 2619080706 BATT_resBrick02_2 65535;
BA_ "GenSigSNA" SG_ 2619080707 BATT_resBrick04_3 65535;
BA_ "GenSigSNA" SG_ 2619080707 BATT_resBrick03_3 65535;
BA_ "GenSigSNA" SG_ 2619080707 BATT_resBrick02_3 65535;
BA_ "GenSigSNA" SG_ 2619080708 BATT_resBrick04_4 65535;
BA_ "GenSigSNA" SG_ 2619080708 BATT_resBrick03_4 65535;
BA_ "GenSigSNA" SG_ 2619080708 BATT_resBrick02_4 65535;
BA_ "GenSigSNA" SG_ 2619080709 BATT_resBrick04_5 65535;
BA_ "GenSigSNA" SG_ 2619080709 BATT_resBrick03_5 65535;
BA_ "GenSigSNA" SG_ 2619080709 BATT_resBrick02_5 65535;
BA_ "GenSigSNA" SG_ 2619080710 BATT_resBrick04_6 65535;
BA_ "GenSigSNA" SG_ 2619080710 BATT_resBrick03_6 65535;
BA_ "GenSigSNA" SG_ 2619080710 BATT_resBrick02_6 65535;
BA_ "GenSigSNA" SG_ 2619080711 BATT_resBrick04_7 65535;
BA_ "GenSigSNA" SG_ 2619080711 BATT_resBrick03_7 65535;
BA_ "GenSigSNA" SG_ 2619080711 BATT_resBrick02_7 65535;
BA_ "GenSigSNA" SG_ 2619080712 BATT_resBrick04_8 65535;
BA_ "GenSigSNA" SG_ 2619080712 BATT_resBrick03_8 65535;
BA_ "GenSigSNA" SG_ 2619080712 BATT_resBrick02_8 65535;
BA_ "GenSigSNA" SG_ 2619080713 BATT_resBrick04_9 65535;
BA_ "GenSigSNA" SG_ 2619080713 BATT_resBrick03_9 65535;
BA_ "GenSigSNA" SG_ 2619080713 BATT_resBrick02_9 65535;
BA_ "GenSigSNA" SG_ 2619080714 BATT_resBrick04_10 65535;
BA_ "GenSigSNA" SG_ 2619080714 BATT_resBrick03_10 65535;
BA_ "GenSigSNA" SG_ 2619080714 BATT_resBrick02_10 65535;
BA_ "GenSigSNA" SG_ 2619080715 BATT_resBrick04_11 65535;
BA_ "GenSigSNA" SG_ 2619080715 BATT_resBrick03_11 65535;
BA_ "GenSigSNA" SG_ 2619080715 BATT_resBrick02_11 65535;
BA_ "GenSigSNA" SG_ 2619342848 BATT_resBrick08_0 65535;
BA_ "GenSigSNA" SG_ 2619342848 BATT_resBrick07_0 65535;
BA_ "GenSigSNA" SG_ 2619342848 BATT_resBrick06_0 65535;
BA_ "GenSigSNA" SG_ 2619342848 BATT_resBrick05_0 65535;
BA_ "GenSigSNA" SG_ 2619342849 BATT_resBrick08_1 65535;
BA_ "GenSigSNA" SG_ 2619342849 BATT_resBrick07_1 65535;
BA_ "GenSigSNA" SG_ 2619342849 BATT_resBrick06_1 65535;
BA_ "GenSigSNA" SG_ 2619342849 BATT_resBrick05_1 65535;
BA_ "GenSigSNA" SG_ 2619342850 BATT_resBrick08_2 65535;
BA_ "GenSigSNA" SG_ 2619342850 BATT_resBrick07_2 65535;
BA_ "GenSigSNA" SG_ 2619342850 BATT_resBrick06_2 65535;
BA_ "GenSigSNA" SG_ 2619342850 BATT_resBrick05_2 65535;
BA_ "GenSigSNA" SG_ 2619342851 BATT_resBrick08_3 65535;
BA_ "GenSigSNA" SG_ 2619342851 BATT_resBrick07_3 65535;
BA_ "GenSigSNA" SG_ 2619342851 BATT_resBrick06_3 65535;
BA_ "GenSigSNA" SG_ 2619342851 BATT_resBrick05_3 65535;
BA_ "GenSigSNA" SG_ 2619342852 BATT_resBrick08_4 65535;
BA_ "GenSigSNA" SG_ 2619342852 BATT_resBrick07_4 65535;
BA_ "GenSigSNA" SG_ 2619342852 BATT_resBrick06_4 65535;
BA_ "GenSigSNA" SG_ 2619342852 BATT_resBrick05_4 65535;
BA_ "GenSigSNA" SG_ 2619342853 BATT_resBrick08_5 65535;
BA_ "GenSigSNA" SG_ 2619342853 BATT_resBrick07_5 65535;
BA_ "GenSigSNA" SG_ 2619342853 BATT_resBrick06_5 65535;
BA_ "GenSigSNA" SG_ 2619342853 BATT_resBrick05_5 65535;
BA_ "GenSigSNA" SG_ 2619342854 BATT_resBrick08_6 65535;
BA_ "GenSigSNA" SG_ 2619342854 BATT_resBrick07_6 65535;
BA_ "GenSigSNA" SG_ 2619342854 BATT_resBrick06_6 65535;
BA_ "GenSigSNA" SG_ 2619342854 BATT_resBrick05_6 65535;
BA_ "GenSigSNA" SG_ 2619342855 BATT_resBrick08_7 65535;
BA_ "GenSigSNA" SG_ 2619342855 BATT_resBrick07_7 65535;
BA_ "GenSigSNA" SG_ 2619342855 BATT_resBrick06_7 65535;
BA_ "GenSigSNA" SG_ 2619342855 BATT_resBrick05_7 65535;
BA_ "GenSigSNA" SG_ 2619342856 BATT_resBrick08_8 65535;
BA_ "GenSigSNA" SG_ 2619342856 BATT_resBrick07_8 65535;
BA_ "GenSigSNA" SG_ 2619342856 BATT_resBrick06_8 65535;
BA_ "GenSigSNA" SG_ 2619342856 BATT_resBrick05_8 65535;
BA_ "GenSigSNA" SG_ 2619342857 BATT_resBrick08_9 65535;
BA_ "GenSigSNA" SG_ 2619342857 BATT_resBrick07_9 65535;
BA_ "GenSigSNA" SG_ 2619342857 BATT_resBrick06_9 65535;
BA_ "GenSigSNA" SG_ 2619342857 BATT_resBrick05_9 65535;
BA_ "GenSigSNA" SG_ 2619342858 BATT_resBrick08_10 65535;
BA_ "GenSigSNA" SG_ 2619342858 BATT_resBrick07_10 65535;
BA_ "GenSigSNA" SG_ 2619342858 BATT_resBrick06_10 65535;
BA_ "GenSigSNA" SG_ 2619342858 BATT_resBrick05_10 65535;
BA_ "GenSigSNA" SG_ 2619342859 BATT_resBrick08_11 65535;
BA_ "GenSigSNA" SG_ 2619342859 BATT_resBrick07_11 65535;
BA_ "GenSigSNA" SG_ 2619342859 BATT_resBrick06_11 65535;
BA_ "GenSigSNA" SG_ 2619342859 BATT_resBrick05_11 65535;
BA_ "GenSigSNA" SG_ 2619604992 BATT_resBrick12_0 65535;
BA_ "GenSigSNA" SG_ 2619604992 BATT_resBrick11_0 65535;
BA_ "GenSigSNA" SG_ 2619604992 BATT_resBrick09_0 65535;
BA_ "GenSigSNA" SG_ 2619604992 BATT_resBrick10_0 65535;
BA_ "GenSigSNA" SG_ 2619604993 BATT_resBrick12_1 65535;
BA_ "GenSigSNA" SG_ 2619604993 BATT_resBrick11_1 65535;
BA_ "GenSigSNA" SG_ 2619604993 BATT_resBrick09_1 65535;
BA_ "GenSigSNA" SG_ 2619604993 BATT_resBrick10_1 65535;
BA_ "GenSigSNA" SG_ 2619604994 BATT_resBrick12_2 65535;
BA_ "GenSigSNA" SG_ 2619604994 BATT_resBrick11_2 65535;
BA_ "GenSigSNA" SG_ 2619604994 BATT_resBrick09_2 65535;
BA_ "GenSigSNA" SG_ 2619604994 BATT_resBrick10_2 65535;
BA_ "GenSigSNA" SG_ 2619604995 BATT_resBrick12_3 65535;
BA_ "GenSigSNA" SG_ 2619604995 BATT_resBrick11_3 65535;
BA_ "GenSigSNA" SG_ 2619604995 BATT_resBrick09_3 65535;
BA_ "GenSigSNA" SG_ 2619604995 BATT_resBrick10_3 65535;
BA_ "GenSigSNA" SG_ 2619604996 BATT_resBrick12_4 65535;
BA_ "GenSigSNA" SG_ 2619604996 BATT_resBrick11_4 65535;
BA_ "GenSigSNA" SG_ 2619604996 BATT_resBrick09_4 65535;
BA_ "GenSigSNA" SG_ 2619604996 BATT_resBrick10_4 65535;
BA_ "GenSigSNA" SG_ 2619604997 BATT_resBrick12_5 65535;
BA_ "GenSigSNA" SG_ 2619604997 BATT_resBrick11_5 65535;
BA_ "GenSigSNA" SG_ 2619604997 BATT_resBrick09_5 65535;
BA_ "GenSigSNA" SG_ 2619604997 BATT_resBrick10_5 65535;
BA_ "GenSigSNA" SG_ 2619604998 BATT_resBrick12_6 65535;
BA_ "GenSigSNA" SG_ 2619604998 BATT_resBrick11_6 65535;
BA_ "GenSigSNA" SG_ 2619604998 BATT_resBrick09_6 65535;
BA_ "GenSigSNA" SG_ 2619604998 BATT_resBrick10_6 65535;
BA_ "GenSigSNA" SG_ 2619604999 BATT_resBrick12_7 65535;
BA_ "GenSigSNA" SG_ 2619604999 BATT_resBrick11_7 65535;
BA_ "GenSigSNA" SG_ 2619604999 BATT_resBrick09_7 65535;
BA_ "GenSigSNA" SG_ 2619604999 BATT_resBrick10_7 65535;
BA_ "GenSigSNA" SG_ 2619605000 BATT_resBrick12_8 65535;
BA_ "GenSigSNA" SG_ 2619605000 BATT_resBrick11_8 65535;
BA_ "GenSigSNA" SG_ 2619605000 BATT_resBrick09_8 65535;
BA_ "GenSigSNA" SG_ 2619605000 BATT_resBrick10_8 65535;
BA_ "GenSigSNA" SG_ 2619605001 BATT_resBrick12_9 65535;
BA_ "GenSigSNA" SG_ 2619605001 BATT_resBrick11_9 65535;
BA_ "GenSigSNA" SG_ 2619605001 BATT_resBrick09_9 65535;
BA_ "GenSigSNA" SG_ 2619605001 BATT_resBrick10_9 65535;
BA_ "GenSigSNA" SG_ 2619605002 BATT_resBrick12_10 65535;
BA_ "GenSigSNA" SG_ 2619605002 BATT_resBrick11_10 65535;
BA_ "GenSigSNA" SG_ 2619605002 BATT_resBrick09_10 65535;
BA_ "GenSigSNA" SG_ 2619605002 BATT_resBrick10_10 65535;
BA_ "GenSigSNA" SG_ 2619605003 BATT_resBrick12_11 65535;
BA_ "GenSigSNA" SG_ 2619605003 BATT_resBrick11_11 65535;
BA_ "GenSigSNA" SG_ 2619605003 BATT_resBrick09_11 65535;
BA_ "GenSigSNA" SG_ 2619605003 BATT_resBrick10_11 65535;
BA_ "GenSigSNA" SG_ 2621440000 BATT_resBrick14_0 65535;
BA_ "GenSigSNA" SG_ 2621440000 BATT_resBrick13_0 65535;
BA_ "GenSigSNA" SG_ 2621440001 BATT_resBrick14_1 65535;
BA_ "GenSigSNA" SG_ 2621440001 BATT_resBrick13_1 65535;
BA_ "GenSigSNA" SG_ 2621440002 BATT_resBrick14_2 65535;
BA_ "GenSigSNA" SG_ 2621440002 BATT_resBrick13_2 65535;
BA_ "GenSigSNA" SG_ 2621440003 BATT_resBrick14_3 65535;
BA_ "GenSigSNA" SG_ 2621440003 BATT_resBrick13_3 65535;
BA_ "GenSigSNA" SG_ 2621440004 BATT_resBrick14_4 65535;
BA_ "GenSigSNA" SG_ 2621440004 BATT_resBrick13_4 65535;
BA_ "GenSigSNA" SG_ 2621440005 BATT_resBrick14_5 65535;
BA_ "GenSigSNA" SG_ 2621440005 BATT_resBrick13_5 65535;
BA_ "GenSigSNA" SG_ 2621440006 BATT_resBrick14_6 65535;
BA_ "GenSigSNA" SG_ 2621440006 BATT_resBrick13_6 65535;
BA_ "GenSigSNA" SG_ 2621440007 BATT_resBrick14_7 65535;
BA_ "GenSigSNA" SG_ 2621440007 BATT_resBrick13_7 65535;
BA_ "GenSigSNA" SG_ 2621440008 BATT_resBrick14_8 65535;
BA_ "GenSigSNA" SG_ 2621440008 BATT_resBrick13_8 65535;
BA_ "GenSigSNA" SG_ 2621440009 BATT_resBrick14_9 65535;
BA_ "GenSigSNA" SG_ 2621440009 BATT_resBrick13_9 65535;
BA_ "GenSigSNA" SG_ 2621440010 BATT_resBrick14_10 65535;
BA_ "GenSigSNA" SG_ 2621440010 BATT_resBrick13_10 65535;
BA_ "GenSigSNA" SG_ 2621440011 BATT_resBrick14_11 65535;
BA_ "GenSigSNA" SG_ 2621440011 BATT_resBrick13_11 65535;
BA_ "GenSigSNA" SG_ 2621702144 BATT_capBrick04_0 65535;
BA_ "GenSigSNA" SG_ 2621702144 BATT_capBrick03_0 65535;
BA_ "GenSigSNA" SG_ 2621702144 BATT_capBrick02_0 65535;
BA_ "GenSigSNA" SG_ 2621702144 BATT_capBrick01_0 65535;
BA_ "GenSigSNA" SG_ 2621702145 BATT_capBrick04_1 65535;
BA_ "GenSigSNA" SG_ 2621702145 BATT_capBrick03_1 65535;
BA_ "GenSigSNA" SG_ 2621702145 BATT_capBrick02_1 65535;
BA_ "GenSigSNA" SG_ 2621702145 BATT_capBrick01_1 65535;
BA_ "GenSigSNA" SG_ 2621702146 BATT_capBrick04_2 65535;
BA_ "GenSigSNA" SG_ 2621702146 BATT_capBrick03_2 65535;
BA_ "GenSigSNA" SG_ 2621702146 BATT_capBrick02_2 65535;
BA_ "GenSigSNA" SG_ 2621702146 BATT_capBrick01_2 65535;
BA_ "GenSigSNA" SG_ 2621702147 BATT_capBrick04_3 65535;
BA_ "GenSigSNA" SG_ 2621702147 BATT_capBrick03_3 65535;
BA_ "GenSigSNA" SG_ 2621702147 BATT_capBrick02_3 65535;
BA_ "GenSigSNA" SG_ 2621702147 BATT_capBrick01_3 65535;
BA_ "GenSigSNA" SG_ 2621702148 BATT_capBrick04_4 65535;
BA_ "GenSigSNA" SG_ 2621702148 BATT_capBrick03_4 65535;
BA_ "GenSigSNA" SG_ 2621702148 BATT_capBrick02_4 65535;
BA_ "GenSigSNA" SG_ 2621702148 BATT_capBrick01_4 65535;
BA_ "GenSigSNA" SG_ 2621702149 BATT_capBrick04_5 65535;
BA_ "GenSigSNA" SG_ 2621702149 BATT_capBrick03_5 65535;
BA_ "GenSigSNA" SG_ 2621702149 BATT_capBrick02_5 65535;
BA_ "GenSigSNA" SG_ 2621702149 BATT_capBrick01_5 65535;
BA_ "GenSigSNA" SG_ 2621702150 BATT_capBrick04_6 65535;
BA_ "GenSigSNA" SG_ 2621702150 BATT_capBrick03_6 65535;
BA_ "GenSigSNA" SG_ 2621702150 BATT_capBrick02_6 65535;
BA_ "GenSigSNA" SG_ 2621702150 BATT_capBrick01_6 65535;
VAL_ 2618556416 BATT_fetChgDiagState_0  4 "Check Closed Result"  3 "Check Open Result"  2 "Start Closed Check"  1 "Start Open Check"  0 "Idle"  ;
VAL_ 2618556416 BATT_fetChgDiagClosedResult_0  3 "Fail"  2 "Pass"  1 "In Progress"  0 "Pending"  ;
VAL_ 2618556416 BATT_fetChgDiagOpenResult_0  3 "Fail"  2 "Pass"  1 "In Progress"  0 "Pending"  ;
VAL_ 2618556417 BATT_fetChgDiagOpenResult_1  3 "Fail"  2 "Pass"  1 "In Progress"  0 "Pending"  ;
VAL_ 2618556417 BATT_fetChgDiagClosedResult_1  3 "Fail"  2 "Pass"  1 "In Progress"  0 "Pending"  ;
VAL_ 2618556417 BATT_fetChgDiagState_1  4 "Check Closed Result"  3 "Check Open Result"  2 "Start Closed Check"  1 "Start Open Check"  0 "Idle"  ;
VAL_ 2618556418 BATT_fetChgDiagState_2  4 "Check Closed Result"  3 "Check Open Result"  2 "Start Closed Check"  1 "Start Open Check"  0 "Idle"  ;
VAL_ 2618556418 BATT_fetChgDiagClosedResult_2  3 "Fail"  2 "Pass"  1 "In Progress"  0 "Pending"  ;
VAL_ 2618556418 BATT_fetChgDiagOpenResult_2  3 "Fail"  2 "Pass"  1 "In Progress"  0 "Pending"  ;
VAL_ 2618556419 BATT_fetChgDiagClosedResult_3  3 "Fail"  2 "Pass"  1 "In Progress"  0 "Pending"  ;
VAL_ 2618556419 BATT_fetChgDiagOpenResult_3  3 "Fail"  2 "Pass"  1 "In Progress"  0 "Pending"  ;
VAL_ 2618556419 BATT_fetChgDiagState_3  4 "Check Closed Result"  3 "Check Open Result"  2 "Start Closed Check"  1 "Start Open Check"  0 "Idle"  ;
VAL_ 2618556420 BATT_fetChgDiagState_4  4 "Check Closed Result"  3 "Check Open Result"  2 "Start Closed Check"  1 "Start Open Check"  0 "Idle"  ;
VAL_ 2618556420 BATT_fetChgDiagClosedResult_4  3 "Fail"  2 "Pass"  1 "In Progress"  0 "Pending"  ;
VAL_ 2618556420 BATT_fetChgDiagOpenResult_4  3 "Fail"  2 "Pass"  1 "In Progress"  0 "Pending"  ;
VAL_ 2618556421 BATT_fetChgDiagOpenResult_5  3 "Fail"  2 "Pass"  1 "In Progress"  0 "Pending"  ;
VAL_ 2618556421 BATT_fetChgDiagClosedResult_5  3 "Fail"  2 "Pass"  1 "In Progress"  0 "Pending"  ;
VAL_ 2618556421 BATT_fetChgDiagState_5  4 "Check Closed Result"  3 "Check Open Result"  2 "Start Closed Check"  1 "Start Open Check"  0 "Idle"  ;
VAL_ 2618556422 BATT_fetChgDiagOpenResult_6  3 "Fail"  2 "Pass"  1 "In Progress"  0 "Pending"  ;
VAL_ 2618556422 BATT_fetChgDiagState_6  4 "Check Closed Result"  3 "Check Open Result"  2 "Start Closed Check"  1 "Start Open Check"  0 "Idle"  ;
VAL_ 2618556422 BATT_fetChgDiagClosedResult_6  3 "Fail"  2 "Pass"  1 "In Progress"  0 "Pending"  ;
VAL_ 2618556423 BATT_fetChgDiagState_7  4 "Check Closed Result"  3 "Check Open Result"  2 "Start Closed Check"  1 "Start Open Check"  0 "Idle"  ;
VAL_ 2618556423 BATT_fetChgDiagClosedResult_7  3 "Fail"  2 "Pass"  1 "In Progress"  0 "Pending"  ;
VAL_ 2618556423 BATT_fetChgDiagOpenResult_7  3 "Fail"  2 "Pass"  1 "In Progress"  0 "Pending"  ;
VAL_ 2618556424 BATT_fetChgDiagClosedResult_8  3 "Fail"  2 "Pass"  1 "In Progress"  0 "Pending"  ;
VAL_ 2618556424 BATT_fetChgDiagOpenResult_8  3 "Fail"  2 "Pass"  1 "In Progress"  0 "Pending"  ;
VAL_ 2618556424 BATT_fetChgDiagState_8  4 "Check Closed Result"  3 "Check Open Result"  2 "Start Closed Check"  1 "Start Open Check"  0 "Idle"  ;
VAL_ 2618556425 BATT_fetChgDiagState_9  4 "Check Closed Result"  3 "Check Open Result"  2 "Start Closed Check"  1 "Start Open Check"  0 "Idle"  ;
VAL_ 2618556425 BATT_fetChgDiagClosedResult_9  3 "Fail"  2 "Pass"  1 "In Progress"  0 "Pending"  ;
VAL_ 2618556425 BATT_fetChgDiagOpenResult_9  3 "Fail"  2 "Pass"  1 "In Progress"  0 "Pending"  ;
VAL_ 2618556426 BATT_fetChgDiagState_10  4 "Check Closed Result"  3 "Check Open Result"  2 "Start Closed Check"  1 "Start Open Check"  0 "Idle"  ;
VAL_ 2618556426 BATT_fetChgDiagClosedResult_10  3 "Fail"  2 "Pass"  1 "In Progress"  0 "Pending"  ;
VAL_ 2618556426 BATT_fetChgDiagOpenResult_10  3 "Fail"  2 "Pass"  1 "In Progress"  0 "Pending"  ;
VAL_ 2618556427 BATT_fetChgDiagOpenResult_11  3 "Fail"  2 "Pass"  1 "In Progress"  0 "Pending"  ;
VAL_ 2618556427 BATT_fetChgDiagClosedResult_11  3 "Fail"  2 "Pass"  1 "In Progress"  0 "Pending"  ;
VAL_ 2618556427 BATT_fetChgDiagState_11  4 "Check Closed Result"  3 "Check Open Result"  2 "Start Closed Check"  1 "Start Open Check"  0 "Idle"  ;
VAL_ 2618818560 BATT_fetDsgDiagClosedResult_0  3 "Fail"  2 "Pass"  1 "In Progress"  0 "Pending"  ;
VAL_ 2618818560 BATT_fetDsgDiagState_0  4 "Check Closed Result"  3 "Check Open Result"  2 "Start Closed Check"  1 "Start Open Check"  0 "Idle"  ;
VAL_ 2618818560 BATT_fetDsgDiagOpenResult_0  3 "Fail"  2 "Pass"  1 "In Progress"  0 "Pending"  ;
VAL_ 2618818561 BATT_fetDsgDiagState_1  4 "Check Closed Result"  3 "Check Open Result"  2 "Start Closed Check"  1 "Start Open Check"  0 "Idle"  ;
VAL_ 2618818561 BATT_fetDsgDiagClosedResult_1  3 "Fail"  2 "Pass"  1 "In Progress"  0 "Pending"  ;
VAL_ 2618818561 BATT_fetDsgDiagOpenResult_1  3 "Fail"  2 "Pass"  1 "In Progress"  0 "Pending"  ;
VAL_ 2618818562 BATT_fetDsgDiagOpenResult_2  3 "Fail"  2 "Pass"  1 "In Progress"  0 "Pending"  ;
VAL_ 2618818562 BATT_fetDsgDiagClosedResult_2  3 "Fail"  2 "Pass"  1 "In Progress"  0 "Pending"  ;
VAL_ 2618818562 BATT_fetDsgDiagState_2  4 "Check Closed Result"  3 "Check Open Result"  2 "Start Closed Check"  1 "Start Open Check"  0 "Idle"  ;
VAL_ 2618818563 BATT_fetDsgDiagState_3  4 "Check Closed Result"  3 "Check Open Result"  2 "Start Closed Check"  1 "Start Open Check"  0 "Idle"  ;
VAL_ 2618818563 BATT_fetDsgDiagOpenResult_3  3 "Fail"  2 "Pass"  1 "In Progress"  0 "Pending"  ;
VAL_ 2618818563 BATT_fetDsgDiagClosedResult_3  3 "Fail"  2 "Pass"  1 "In Progress"  0 "Pending"  ;
VAL_ 2618818564 BATT_fetDsgDiagOpenResult_4  3 "Fail"  2 "Pass"  1 "In Progress"  0 "Pending"  ;
VAL_ 2618818564 BATT_fetDsgDiagState_4  4 "Check Closed Result"  3 "Check Open Result"  2 "Start Closed Check"  1 "Start Open Check"  0 "Idle"  ;
VAL_ 2618818564 BATT_fetDsgDiagClosedResult_4  3 "Fail"  2 "Pass"  1 "In Progress"  0 "Pending"  ;
VAL_ 2618818565 BATT_fetDsgDiagClosedResult_5  3 "Fail"  2 "Pass"  1 "In Progress"  0 "Pending"  ;
VAL_ 2618818565 BATT_fetDsgDiagState_5  4 "Check Closed Result"  3 "Check Open Result"  2 "Start Closed Check"  1 "Start Open Check"  0 "Idle"  ;
VAL_ 2618818565 BATT_fetDsgDiagOpenResult_5  3 "Fail"  2 "Pass"  1 "In Progress"  0 "Pending"  ;
VAL_ 2618818566 BATT_fetDsgDiagClosedResult_6  3 "Fail"  2 "Pass"  1 "In Progress"  0 "Pending"  ;
VAL_ 2618818566 BATT_fetDsgDiagState_6  4 "Check Closed Result"  3 "Check Open Result"  2 "Start Closed Check"  1 "Start Open Check"  0 "Idle"  ;
VAL_ 2618818566 BATT_fetDsgDiagOpenResult_6  3 "Fail"  2 "Pass"  1 "In Progress"  0 "Pending"  ;
VAL_ 2618818567 BATT_fetDsgDiagClosedResult_7  3 "Fail"  2 "Pass"  1 "In Progress"  0 "Pending"  ;
VAL_ 2618818567 BATT_fetDsgDiagState_7  4 "Check Closed Result"  3 "Check Open Result"  2 "Start Closed Check"  1 "Start Open Check"  0 "Idle"  ;
VAL_ 2618818567 BATT_fetDsgDiagOpenResult_7  3 "Fail"  2 "Pass"  1 "In Progress"  0 "Pending"  ;
VAL_ 2618818568 BATT_fetDsgDiagState_8  4 "Check Closed Result"  3 "Check Open Result"  2 "Start Closed Check"  1 "Start Open Check"  0 "Idle"  ;
VAL_ 2618818568 BATT_fetDsgDiagOpenResult_8  3 "Fail"  2 "Pass"  1 "In Progress"  0 "Pending"  ;
VAL_ 2618818568 BATT_fetDsgDiagClosedResult_8  3 "Fail"  2 "Pass"  1 "In Progress"  0 "Pending"  ;
VAL_ 2618818569 BATT_fetDsgDiagClosedResult_9  3 "Fail"  2 "Pass"  1 "In Progress"  0 "Pending"  ;
VAL_ 2618818569 BATT_fetDsgDiagState_9  4 "Check Closed Result"  3 "Check Open Result"  2 "Start Closed Check"  1 "Start Open Check"  0 "Idle"  ;
VAL_ 2618818569 BATT_fetDsgDiagOpenResult_9  3 "Fail"  2 "Pass"  1 "In Progress"  0 "Pending"  ;
VAL_ 2618818570 BATT_fetDsgDiagOpenResult_10  3 "Fail"  2 "Pass"  1 "In Progress"  0 "Pending"  ;
VAL_ 2618818570 BATT_fetDsgDiagState_10  4 "Check Closed Result"  3 "Check Open Result"  2 "Start Closed Check"  1 "Start Open Check"  0 "Idle"  ;
VAL_ 2618818570 BATT_fetDsgDiagClosedResult_10  3 "Fail"  2 "Pass"  1 "In Progress"  0 "Pending"  ;
VAL_ 2618818571 BATT_fetDsgDiagOpenResult_11  3 "Fail"  2 "Pass"  1 "In Progress"  0 "Pending"  ;
VAL_ 2618818571 BATT_fetDsgDiagClosedResult_11  3 "Fail"  2 "Pass"  1 "In Progress"  0 "Pending"  ;
VAL_ 2618818571 BATT_fetDsgDiagState_11  4 "Check Closed Result"  3 "Check Open Result"  2 "Start Closed Check"  1 "Start Open Check"  0 "Idle"  ;
VAL_ 2619080704 BATT_resBrick04_0  65535 "SNA"  ;
VAL_ 2619080704 BATT_resBrick03_0  65535 "SNA"  ;
VAL_ 2619080704 BATT_resBrick02_0  65535 "SNA"  ;
VAL_ 2619080704 BATT_resBrick01_0  65535 "SNA"  ;
VAL_ 2619080705 BATT_resBrick04_1  65535 "SNA"  ;
VAL_ 2619080705 BATT_resBrick03_1  65535 "SNA"  ;
VAL_ 2619080705 BATT_resBrick02_1  65535 "SNA"  ;
VAL_ 2619080705 BATT_resBrick01_1  65535 "SNA"  ;
VAL_ 2619080706 BATT_resBrick04_2  65535 "SNA"  ;
VAL_ 2619080706 BATT_resBrick03_2  65535 "SNA"  ;
VAL_ 2619080706 BATT_resBrick02_2  65535 "SNA"  ;
VAL_ 2619080706 BATT_resBrick01_2  65535 "SNA"  ;
VAL_ 2619080707 BATT_resBrick04_3  65535 "SNA"  ;
VAL_ 2619080707 BATT_resBrick03_3  65535 "SNA"  ;
VAL_ 2619080707 BATT_resBrick02_3  65535 "SNA"  ;
VAL_ 2619080707 BATT_resBrick01_3  65535 "SNA"  ;
VAL_ 2619080708 BATT_resBrick04_4  65535 "SNA"  ;
VAL_ 2619080708 BATT_resBrick03_4  65535 "SNA"  ;
VAL_ 2619080708 BATT_resBrick02_4  65535 "SNA"  ;
VAL_ 2619080708 BATT_resBrick01_4  65535 "SNA"  ;
VAL_ 2619080709 BATT_resBrick04_5  65535 "SNA"  ;
VAL_ 2619080709 BATT_resBrick03_5  65535 "SNA"  ;
VAL_ 2619080709 BATT_resBrick02_5  65535 "SNA"  ;
VAL_ 2619080709 BATT_resBrick01_5  65535 "SNA"  ;
VAL_ 2619080710 BATT_resBrick04_6  65535 "SNA"  ;
VAL_ 2619080710 BATT_resBrick03_6  65535 "SNA"  ;
VAL_ 2619080710 BATT_resBrick02_6  65535 "SNA"  ;
VAL_ 2619080710 BATT_resBrick01_6  65535 "SNA"  ;
VAL_ 2619080711 BATT_resBrick04_7  65535 "SNA"  ;
VAL_ 2619080711 BATT_resBrick03_7  65535 "SNA"  ;
VAL_ 2619080711 BATT_resBrick02_7  65535 "SNA"  ;
VAL_ 2619080711 BATT_resBrick01_7  65535 "SNA"  ;
VAL_ 2619080712 BATT_resBrick04_8  65535 "SNA"  ;
VAL_ 2619080712 BATT_resBrick03_8  65535 "SNA"  ;
VAL_ 2619080712 BATT_resBrick02_8  65535 "SNA"  ;
VAL_ 2619080712 BATT_resBrick01_8  65535 "SNA"  ;
VAL_ 2619080713 BATT_resBrick04_9  65535 "SNA"  ;
VAL_ 2619080713 BATT_resBrick03_9  65535 "SNA"  ;
VAL_ 2619080713 BATT_resBrick02_9  65535 "SNA"  ;
VAL_ 2619080713 BATT_resBrick01_9  65535 "SNA"  ;
VAL_ 2619080714 BATT_resBrick04_10  65535 "SNA"  ;
VAL_ 2619080714 BATT_resBrick03_10  65535 "SNA"  ;
VAL_ 2619080714 BATT_resBrick02_10  65535 "SNA"  ;
VAL_ 2619080714 BATT_resBrick01_10  65535 "SNA"  ;
VAL_ 2619080715 BATT_resBrick04_11  65535 "SNA"  ;
VAL_ 2619080715 BATT_resBrick03_11  65535 "SNA"  ;
VAL_ 2619080715 BATT_resBrick02_11  65535 "SNA"  ;
VAL_ 2619080715 BATT_resBrick01_11  65535 "SNA"  ;
VAL_ 2619342848 BATT_resBrick08_0  65535 "SNA"  ;
VAL_ 2619342848 BATT_resBrick07_0  65535 "SNA"  ;
VAL_ 2619342848 BATT_resBrick06_0  65535 "SNA"  ;
VAL_ 2619342848 BATT_resBrick05_0  65535 "SNA"  ;
VAL_ 2619342849 BATT_resBrick08_1  65535 "SNA"  ;
VAL_ 2619342849 BATT_resBrick07_1  65535 "SNA"  ;
VAL_ 2619342849 BATT_resBrick06_1  65535 "SNA"  ;
VAL_ 2619342849 BATT_resBrick05_1  65535 "SNA"  ;
VAL_ 2619342850 BATT_resBrick08_2  65535 "SNA"  ;
VAL_ 2619342850 BATT_resBrick07_2  65535 "SNA"  ;
VAL_ 2619342850 BATT_resBrick06_2  65535 "SNA"  ;
VAL_ 2619342850 BATT_resBrick05_2  65535 "SNA"  ;
VAL_ 2619342851 BATT_resBrick08_3  65535 "SNA"  ;
VAL_ 2619342851 BATT_resBrick07_3  65535 "SNA"  ;
VAL_ 2619342851 BATT_resBrick06_3  65535 "SNA"  ;
VAL_ 2619342851 BATT_resBrick05_3  65535 "SNA"  ;
VAL_ 2619342852 BATT_resBrick08_4  65535 "SNA"  ;
VAL_ 2619342852 BATT_resBrick07_4  65535 "SNA"  ;
VAL_ 2619342852 BATT_resBrick06_4  65535 "SNA"  ;
VAL_ 2619342852 BATT_resBrick05_4  65535 "SNA"  ;
VAL_ 2619342853 BATT_resBrick08_5  65535 "SNA"  ;
VAL_ 2619342853 BATT_resBrick07_5  65535 "SNA"  ;
VAL_ 2619342853 BATT_resBrick06_5  65535 "SNA"  ;
VAL_ 2619342853 BATT_resBrick05_5  65535 "SNA"  ;
VAL_ 2619342854 BATT_resBrick08_6  65535 "SNA"  ;
VAL_ 2619342854 BATT_resBrick07_6  65535 "SNA"  ;
VAL_ 2619342854 BATT_resBrick06_6  65535 "SNA"  ;
VAL_ 2619342854 BATT_resBrick05_6  65535 "SNA"  ;
VAL_ 2619342855 BATT_resBrick08_7  65535 "SNA"  ;
VAL_ 2619342855 BATT_resBrick07_7  65535 "SNA"  ;
VAL_ 2619342855 BATT_resBrick06_7  65535 "SNA"  ;
VAL_ 2619342855 BATT_resBrick05_7  65535 "SNA"  ;
VAL_ 2619342856 BATT_resBrick08_8  65535 "SNA"  ;
VAL_ 2619342856 BATT_resBrick07_8  65535 "SNA"  ;
VAL_ 2619342856 BATT_resBrick06_8  65535 "SNA"  ;
VAL_ 2619342856 BATT_resBrick05_8  65535 "SNA"  ;
VAL_ 2619342857 BATT_resBrick08_9  65535 "SNA"  ;
VAL_ 2619342857 BATT_resBrick07_9  65535 "SNA"  ;
VAL_ 2619342857 BATT_resBrick06_9  65535 "SNA"  ;
VAL_ 2619342857 BATT_resBrick05_9  65535 "SNA"  ;
VAL_ 2619342858 BATT_resBrick08_10  65535 "SNA"  ;
VAL_ 2619342858 BATT_resBrick07_10  65535 "SNA"  ;
VAL_ 2619342858 BATT_resBrick06_10  65535 "SNA"  ;
VAL_ 2619342858 BATT_resBrick05_10  65535 "SNA"  ;
VAL_ 2619342859 BATT_resBrick08_11  65535 "SNA"  ;
VAL_ 2619342859 BATT_resBrick07_11  65535 "SNA"  ;
VAL_ 2619342859 BATT_resBrick06_11  65535 "SNA"  ;
VAL_ 2619342859 BATT_resBrick05_11  65535 "SNA"  ;
VAL_ 2619604992 BATT_resBrick12_0  65535 "SNA"  ;
VAL_ 2619604992 BATT_resBrick11_0  65535 "SNA"  ;
VAL_ 2619604992 BATT_resBrick09_0  65535 "SNA"  ;
VAL_ 2619604992 BATT_resBrick10_0  65535 "SNA"  ;
VAL_ 2619604993 BATT_resBrick12_1  65535 "SNA"  ;
VAL_ 2619604993 BATT_resBrick11_1  65535 "SNA"  ;
VAL_ 2619604993 BATT_resBrick09_1  65535 "SNA"  ;
VAL_ 2619604993 BATT_resBrick10_1  65535 "SNA"  ;
VAL_ 2619604994 BATT_resBrick12_2  65535 "SNA"  ;
VAL_ 2619604994 BATT_resBrick11_2  65535 "SNA"  ;
VAL_ 2619604994 BATT_resBrick09_2  65535 "SNA"  ;
VAL_ 2619604994 BATT_resBrick10_2  65535 "SNA"  ;
VAL_ 2619604995 BATT_resBrick12_3  65535 "SNA"  ;
VAL_ 2619604995 BATT_resBrick11_3  65535 "SNA"  ;
VAL_ 2619604995 BATT_resBrick09_3  65535 "SNA"  ;
VAL_ 2619604995 BATT_resBrick10_3  65535 "SNA"  ;
VAL_ 2619604996 BATT_resBrick12_4  65535 "SNA"  ;
VAL_ 2619604996 BATT_resBrick11_4  65535 "SNA"  ;
VAL_ 2619604996 BATT_resBrick09_4  65535 "SNA"  ;
VAL_ 2619604996 BATT_resBrick10_4  65535 "SNA"  ;
VAL_ 2619604997 BATT_resBrick12_5  65535 "SNA"  ;
VAL_ 2619604997 BATT_resBrick11_5  65535 "SNA"  ;
VAL_ 2619604997 BATT_resBrick09_5  65535 "SNA"  ;
VAL_ 2619604997 BATT_resBrick10_5  65535 "SNA"  ;
VAL_ 2619604998 BATT_resBrick12_6  65535 "SNA"  ;
VAL_ 2619604998 BATT_resBrick11_6  65535 "SNA"  ;
VAL_ 2619604998 BATT_resBrick09_6  65535 "SNA"  ;
VAL_ 2619604998 BATT_resBrick10_6  65535 "SNA"  ;
VAL_ 2619604999 BATT_resBrick12_7  65535 "SNA"  ;
VAL_ 2619604999 BATT_resBrick11_7  65535 "SNA"  ;
VAL_ 2619604999 BATT_resBrick09_7  65535 "SNA"  ;
VAL_ 2619604999 BATT_resBrick10_7  65535 "SNA"  ;
VAL_ 2619605000 BATT_resBrick12_8  65535 "SNA"  ;
VAL_ 2619605000 BATT_resBrick11_8  65535 "SNA"  ;
VAL_ 2619605000 BATT_resBrick09_8  65535 "SNA"  ;
VAL_ 2619605000 BATT_resBrick10_8  65535 "SNA"  ;
VAL_ 2619605001 BATT_resBrick12_9  65535 "SNA"  ;
VAL_ 2619605001 BATT_resBrick11_9  65535 "SNA"  ;
VAL_ 2619605001 BATT_resBrick09_9  65535 "SNA"  ;
VAL_ 2619605001 BATT_resBrick10_9  65535 "SNA"  ;
VAL_ 2619605002 BATT_resBrick12_10  65535 "SNA"  ;
VAL_ 2619605002 BATT_resBrick11_10  65535 "SNA"  ;
VAL_ 2619605002 BATT_resBrick09_10  65535 "SNA"  ;
VAL_ 2619605002 BATT_resBrick10_10  65535 "SNA"  ;
VAL_ 2619605003 BATT_resBrick12_11  65535 "SNA"  ;
VAL_ 2619605003 BATT_resBrick11_11  65535 "SNA"  ;
VAL_ 2619605003 BATT_resBrick09_11  65535 "SNA"  ;
VAL_ 2619605003 BATT_resBrick10_11  65535 "SNA"  ;
VAL_ 2620653568 BATT_wakeReason_0  3 "RTC"  2 "IGN_HI"  1 "IGN_LO"  0 "CAN"  ;
VAL_ 2620653569 BATT_wakeReason_1  3 "RTC"  2 "IGN_HI"  1 "IGN_LO"  0 "CAN"  ;
VAL_ 2620653570 BATT_wakeReason_2  3 "RTC"  2 "IGN_HI"  1 "IGN_LO"  0 "CAN"  ;
VAL_ 2620653571 BATT_wakeReason_3  3 "RTC"  2 "IGN_HI"  1 "IGN_LO"  0 "CAN"  ;
VAL_ 2620653572 BATT_wakeReason_4  3 "RTC"  2 "IGN_HI"  1 "IGN_LO"  0 "CAN"  ;
VAL_ 2620653573 BATT_wakeReason_5  3 "RTC"  2 "IGN_HI"  1 "IGN_LO"  0 "CAN"  ;
VAL_ 2620653574 BATT_wakeReason_6  3 "RTC"  2 "IGN_HI"  1 "IGN_LO"  0 "CAN"  ;
VAL_ 2620653575 BATT_wakeReason_7  3 "RTC"  2 "IGN_HI"  1 "IGN_LO"  0 "CAN"  ;
VAL_ 2620653576 BATT_wakeReason_8  3 "RTC"  2 "IGN_HI"  1 "IGN_LO"  0 "CAN"  ;
VAL_ 2620653577 BATT_wakeReason_9  3 "RTC"  2 "IGN_HI"  1 "IGN_LO"  0 "CAN"  ;
VAL_ 2620653578 BATT_wakeReason_10  3 "RTC"  2 "IGN_HI"  1 "IGN_LO"  0 "CAN"  ;
VAL_ 2620653579 BATT_wakeReason_11  3 "RTC"  2 "IGN_HI"  1 "IGN_LO"  0 "CAN"  ;
VAL_ 2621440000 BATT_resBrick14_0  65535 "SNA"  ;
VAL_ 2621440000 BATT_resBrick13_0  65535 "SNA"  ;
VAL_ 2621440001 BATT_resBrick14_1  65535 "SNA"  ;
VAL_ 2621440001 BATT_resBrick13_1  65535 "SNA"  ;
VAL_ 2621440002 BATT_resBrick14_2  65535 "SNA"  ;
VAL_ 2621440002 BATT_resBrick13_2  65535 "SNA"  ;
VAL_ 2621440003 BATT_resBrick14_3  65535 "SNA"  ;
VAL_ 2621440003 BATT_resBrick13_3  65535 "SNA"  ;
VAL_ 2621440004 BATT_resBrick14_4  65535 "SNA"  ;
VAL_ 2621440004 BATT_resBrick13_4  65535 "SNA"  ;
VAL_ 2621440005 BATT_resBrick14_5  65535 "SNA"  ;
VAL_ 2621440005 BATT_resBrick13_5  65535 "SNA"  ;
VAL_ 2621440006 BATT_resBrick14_6  65535 "SNA"  ;
VAL_ 2621440006 BATT_resBrick13_6  65535 "SNA"  ;
VAL_ 2621440007 BATT_resBrick14_7  65535 "SNA"  ;
VAL_ 2621440007 BATT_resBrick13_7  65535 "SNA"  ;
VAL_ 2621440008 BATT_resBrick14_8  65535 "SNA"  ;
VAL_ 2621440008 BATT_resBrick13_8  65535 "SNA"  ;
VAL_ 2621440009 BATT_resBrick14_9  65535 "SNA"  ;
VAL_ 2621440009 BATT_resBrick13_9  65535 "SNA"  ;
VAL_ 2621440010 BATT_resBrick14_10  65535 "SNA"  ;
VAL_ 2621440010 BATT_resBrick13_10  65535 "SNA"  ;
VAL_ 2621440011 BATT_resBrick14_11  65535 "SNA"  ;
VAL_ 2621440011 BATT_resBrick13_11  65535 "SNA"  ;
VAL_ 2621702144 BATT_capBrick04_0  65535 "SNA"  ;
VAL_ 2621702144 BATT_capBrick03_0  65535 "SNA"  ;
VAL_ 2621702144 BATT_capBrick02_0  65535 "SNA"  ;
VAL_ 2621702144 BATT_capBrick01_0  65535 "SNA"  ;
VAL_ 2621702145 BATT_capBrick04_1  65535 "SNA"  ;
VAL_ 2621702145 BATT_capBrick03_1  65535 "SNA"  ;
VAL_ 2621702145 BATT_capBrick02_1  65535 "SNA"  ;
VAL_ 2621702145 BATT_capBrick01_1  65535 "SNA"  ;
VAL_ 2621702146 BATT_capBrick04_2  65535 "SNA"  ;
VAL_ 2621702146 BATT_capBrick03_2  65535 "SNA"  ;
VAL_ 2621702146 BATT_capBrick02_2  65535 "SNA"  ;
VAL_ 2621702146 BATT_capBrick01_2  65535 "SNA"  ;
VAL_ 2621702147 BATT_capBrick04_3  65535 "SNA"  ;
VAL_ 2621702147 BATT_capBrick03_3  65535 "SNA"  ;
VAL_ 2621702147 BATT_capBrick02_3  65535 "SNA"  ;
VAL_ 2621702147 BATT_capBrick01_3  65535 "SNA"  ;
VAL_ 2621702148 BATT_capBrick04_4  65535 "SNA"  ;
VAL_ 2621702148 BATT_capBrick03_4  65535 "SNA"  ;
VAL_ 2621702148 BATT_capBrick02_4  65535 "SNA"  ;
VAL_ 2621702148 BATT_capBrick01_4  65535 "SNA"  ;
VAL_ 2621702149 BATT_capBrick04_5  65535 "SNA"  ;
VAL_ 2621702149 BATT_capBrick03_5  65535 "SNA"  ;
VAL_ 2621702149 BATT_capBrick02_5  65535 "SNA"  ;
VAL_ 2621702149 BATT_capBrick01_5  65535 "SNA"  ;
VAL_ 2621702150 BATT_capBrick04_6  65535 "SNA"  ;
VAL_ 2621702150 BATT_capBrick03_6  65535 "SNA"  ;
VAL_ 2621702150 BATT_capBrick02_6  65535 "SNA"  ;
VAL_ 2621702150 BATT_capBrick01_6  65535 "SNA"  ;
